VERSION ""

NS_ :

BS_:

BU_: WCM VPM VLM VKM UVM TIM TEST_TOOL_2 TEST_TOOL_1 TCP TCM TCCM3 TCCM STC SRR_SRR SRR_SLR SRR_RR SRR_RF SRR_LR_CR SRR_LF SIB SDM SCL SBZA_R SBZA_L SBM SADS RadioLow RSC RDCM PTM PDR PA NVM MTCM_R MTCM_L MSM_RR MSM_P MSM_LR MSM_D MSB2 MSB1 MRCM_R MRCM_L MFC LRR_HC LRR LIB1 IPC ICS_Info ICCM HVAC_FP_R HVAC_FP_F HUD_CAN HDLM FCM_LC FCM EPS EOCM_HCP2 EOCM_HCP1 EOCM ELM ECP_X1 ECP_MC ECP_E ECM EBCM DMS DEFC DCM CSM CMMb CMMa CGM BSM_MH BSM BCM ARS ARB APA AOS AMP ALC AHS AHL_AFL AGC

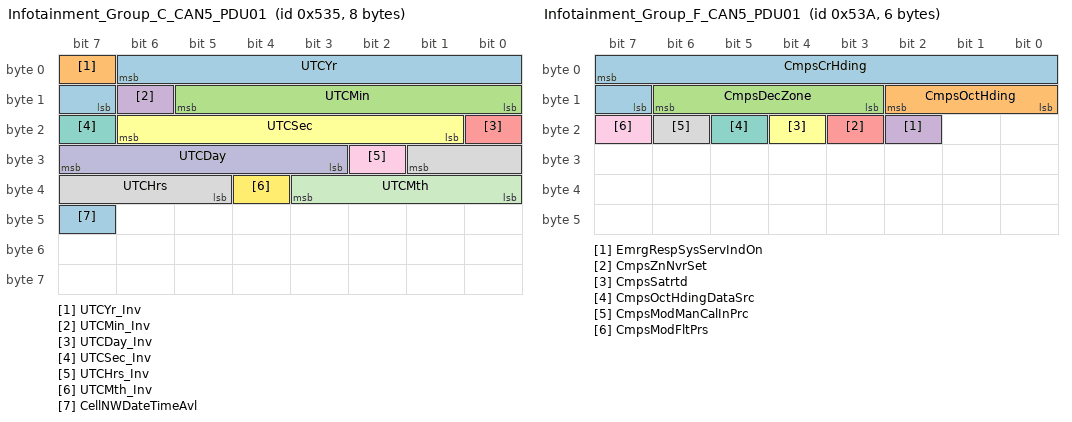
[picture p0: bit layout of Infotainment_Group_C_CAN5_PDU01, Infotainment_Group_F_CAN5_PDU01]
BO_ 1333 Infotainment_Group_C_CAN5_PDU01: 8 TCP
 SG_ UTCYr : 6|8@0+ (1,2000) [2000|2255] "year" CGM,CSM,RadioLow,VKM
 SG_ UTCYr_Inv : 7|1@0+ (1,0) [0|1] "" CGM,CSM,RadioLow,VKM
 SG_ UTCMin : 13|6@0+ (1,0) [0|63] "minutes" CGM,CSM,RadioLow,VKM
 SG_ UTCMin_Inv : 14|1@0+ (1,0) [0|1] "" CGM,CSM,RadioLow,VKM
 SG_ UTCDay_Inv : 16|1@0+ (1,0) [0|1] "" CGM,CSM,RadioLow,VKM
 SG_ UTCSec : 22|6@0+ (1,0) [0|63] "seconds" CGM,CSM,RadioLow
 SG_ UTCSec_Inv : 23|1@0+ (1,0) [0|1] "" CGM,CSM,RadioLow
 SG_ UTCHrs : 25|5@0+ (1,0) [0|31] "hour" CGM,CSM,RadioLow,VKM
 SG_ UTCHrs_Inv : 26|1@0+ (1,0) [0|1] "" CGM,CSM,RadioLow,VKM
 SG_ UTCDay : 31|5@0+ (1,0) [0|31] "day" CGM,CSM,RadioLow,VKM
 SG_ UTCMth : 35|4@0+ (1,0) [0|12] "" CGM,CSM,RadioLow,VKM
 SG_ UTCMth_Inv : 36|1@0+ (1,0) [0|1] "" CGM,CSM,RadioLow,VKM
 SG_ CellNWDateTimeAvl : 47|1@0+ (1,0) [0|1] "" CSM,RadioLow

BO_ 1338 Infotainment_Group_F_CAN5_PDU01: 6 TCP
 SG_ CmpsCrHding : 7|9@0+ (1,0) [0|511] "deg" CSM,IPC,RadioLow
 SG_ CmpsOctHding : 10|3@0+ (1,0) [0|7] "" CSM,IPC,RadioLow
 SG_ CmpsDecZone : 14|4@0+ (1,0) [0|15] "" CSM,IPC,RadioLow
 SG_ EmrgRespSysServIndOn : 18|1@0+ (1,0) [0|1] "" IPC
 SG_ CmpsZnNvrSet : 19|1@0+ (1,0) [0|1] "" CSM,RadioLow
 SG_ CmpsSatrtd : 20|1@0+ (1,0) [0|1] "" CSM,RadioLow
 SG_ CmpsOctHdingDataSrc : 21|1@0+ (1,0) [0|1] "" CSM,RadioLow
 SG_ CmpsModManCalInPrc : 22|1@0+ (1,0) [0|1] "" CSM,RadioLow
 SG_ CmpsModFltPrs : 23|1@0+ (1,0) [0|1] "" CSM,IPC,RadioLow

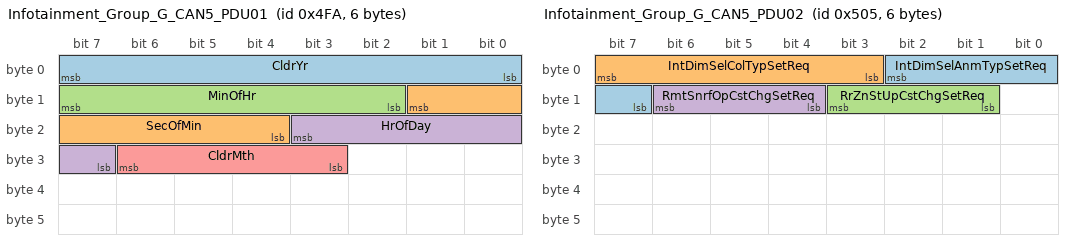
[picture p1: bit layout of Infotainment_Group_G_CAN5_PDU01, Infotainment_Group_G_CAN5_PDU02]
BO_ 1274 Infotainment_Group_G_CAN5_PDU01: 6 CSM
 SG_ CldrYr : 7|8@0+ (1,2000) [2000|2255] "year" CGM,ICS_Info,IPC,PDR
 SG_ SecOfMin : 9|6@0+ (1,0) [0|63] "seconds" CGM,ICS_Info,IPC,PDR
 SG_ MinOfHr : 15|6@0+ (1,0) [0|63] "minutes" CGM,ICS_Info,IPC,PDR
 SG_ HrOfDay : 19|5@0+ (1,0) [0|31] "hour" CGM,ICS_Info,IPC,PDR
 SG_ CldrMth : 30|4@0+ (1,0) [0|12] "" CGM,ICS_Info,IPC,PDR

BO_ 1285 Infotainment_Group_G_CAN5_PDU02: 6 CSM
 SG_ IntDimSelAnmTypSetReq : 2|4@0+ (1,0) [0|15] "" CGM
 SG_ IntDimSelColTypSetReq : 7|5@0+ (1,0) [0|31] "" CGM
 SG_ RrZnStUpCstChgSetReq : 11|3@0+ (1,0) [0|7] "" CGM
 SG_ RmtSnrfOpCstChgSetReq : 14|3@0+ (1,0) [0|7] "" CGM

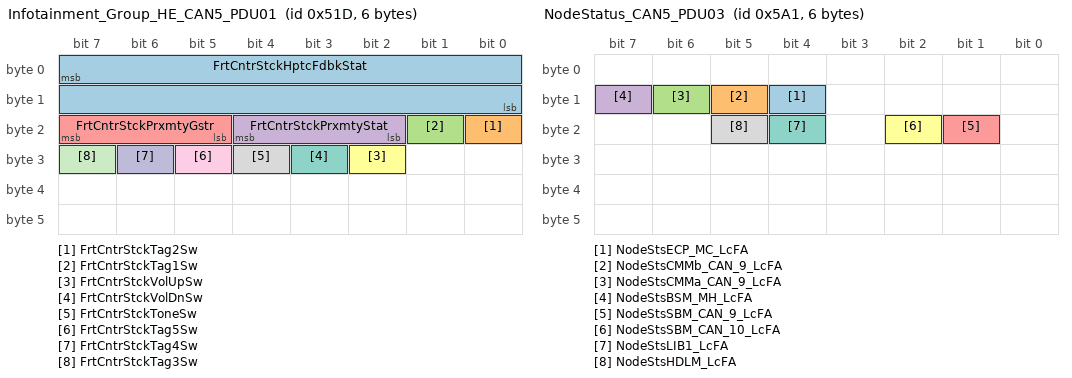
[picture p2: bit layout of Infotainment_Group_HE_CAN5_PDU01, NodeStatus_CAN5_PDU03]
BO_ 1309 Infotainment_Group_HE_CAN5_PDU01: 6 ICS_Info
 SG_ FrtCntrStckHptcFdbkStat : 7|16@0+ (1,0) [0|15] "" CSM,TCP
 SG_ FrtCntrStckTag2Sw : 16|1@0+ (1,0) [0|1] "" CSM,TCP
 SG_ FrtCntrStckTag1Sw : 17|1@0+ (1,0) [0|1] "" CSM,TCP
 SG_ FrtCntrStckPrxmtyStat : 20|3@0+ (1,0) [0|7] "" CSM,TCP
 SG_ FrtCntrStckPrxmtyGstr : 23|3@0+ (1,0) [0|7] "" CSM,TCP
 SG_ FrtCntrStckVolUpSw : 26|1@0+ (1,0) [0|1] "" CSM,TCP
 SG_ FrtCntrStckVolDnSw : 27|1@0+ (1,0) [0|1] "" CSM,TCP
 SG_ FrtCntrStckToneSw : 28|1@0+ (1,0) [0|1] "" CSM,TCP
 SG_ FrtCntrStckTag5Sw : 29|1@0+ (1,0) [0|1] "" CSM,TCP
 SG_ FrtCntrStckTag4Sw : 30|1@0+ (1,0) [0|1] "" CSM,TCP
 SG_ FrtCntrStckTag3Sw : 31|1@0+ (1,0) [0|1] "" CSM,TCP

BO_ 1033 LnFllwgFtrStat_CAN2_PDU01: 6 CGM
 SG_ LnFllwgFtrStat : 7|4@0+ (1,0) [0|10] "" TCP

BO_ 1377 NodeStatus_CAN5_PDU01: 8 CGM
 SG_ NodeStsAPA_CAN_2_LcFA : 0|1@0+ (1,0) [0|1] "" Vector__XXX
 SG_ NodeStsAPA_CAN_1_LcFA : 1|1@0+ (1,0) [0|1] "" CSM
 SG_ NodeStsAOS_LcFA : 2|1@0+ (1,0) [0|1] "" CSM
 SG_ NodeStsAMP_LcFA : 3|1@0+ (1,0) [0|1] "" Vector__XXX
 SG_ NodeStsALC_LcFA : 4|1@0+ (1,0) [0|1] "" CSM,IPC
 SG_ NodeStsAHL_AFL_LcFA : 5|1@0+ (1,0) [0|1] "" CSM,IPC
 SG_ NodeStsAGC_LcFA : 6|1@0+ (1,0) [0|1] "" Vector__XXX
 SG_ NodeStsDMS_LcFA : 8|1@0+ (1,0) [0|1] "" CSM
 SG_ NodeStsDEFC_LcFA : 9|1@0+ (1,0) [0|1] "" CSM,IPC
 SG_ NodeStsDCM_LcFA : 10|1@0+ (1,0) [0|1] "" CSM
 SG_ NodeStsCSM_LcFA : 11|1@0+ (1,0) [0|1] "" Vector__XXX
 SG_ NodeStsBSM_CAN_3_LcFA : 12|1@0+ (1,0) [0|1] "" Vector__XXX
 SG_ NodeStsBSM_CAN_2_LcFA : 13|1@0+ (1,0) [0|1] "" CSM,IPC
 SG_ NodeStsBCM_LcFA : 14|1@0+ (1,0) [0|1] "" AGC,AMP,CSM,HUD_CAN,HVAC_FP_F,HVAC_FP_R,ICS_Info,IPC,PDR,MFC,RSC,RadioLow,TCP,VKM,WCM
 SG_ NodeStsARB_LcFA : 15|1@0+ (1,0) [0|1] "" CSM
 SG_ NodeStsELM_LcFA : 16|1@0+ (1,0) [0|1] "" AMP,CSM,IPC,RadioLow,TCP
 SG_ NodeStsECP_X1_CAN_3_LcFA : 18|1@0+ (1,0) [0|1] "" Vector__XXX
 SG_ NodeStsECP_X1_CAN_2_LcFA : 19|1@0+ (1,0) [0|1] "" AMP,CSM,IPC
 SG_ NodeStsECM_CAN_3_LcFA : 20|1@0+ (1,0) [0|1] "" CSM,IPC
 SG_ NodeStsECM_CAN_2_LcFA : 21|1@0+ (1,0) [0|1] "" AGC,AMP,CSM,HUD_CAN,HVAC_FP_R,ICS_Info,IPC,PDR,MFC,RSC,RadioLow,TCP,VKM,WCM
 SG_ NodeStsEBCM_CAN_2_LcFA : 22|1@0+ (1,0) [0|1] "" CSM,IPC,TCP
 SG_ NodeStsEBCM_CAN_1_LcFA : 23|1@0+ (1,0) [0|1] "" CSM,IPC,RadioLow,TCP
 SG_ NodeStsEPS_LcFA : 24|1@0+ (1,0) [0|1] "" CSM,IPC
 SG_ NodeStsEOCM_HCP2_LcFA : 25|1@0+ (1,0) [0|1] "" CSM
 SG_ NodeStsEOCM_HCP1_CAN_8_LcFA : 26|1@0+ (1,0) [0|1] "" Vector__XXX
 SG_ NodeStsEOCM_HCP1_CAN_2_LcFA : 27|1@0+ (1,0) [0|1] "" CSM,IPC,RadioLow,TCP
 SG_ NodeStsEOCM_HCP1_CAN_1_LcFA : 28|1@0+ (1,0) [0|1] "" CSM,IPC
 SG_ NodeStsEOCM_CAN_8_LcFA : 29|1@0+ (1,0) [0|1] "" Vector__XXX
 SG_ NodeStsEOCM_CAN_2_LcFA : 30|1@0+ (1,0) [0|1] "" CSM,IPC,RadioLow,TCP
 SG_ NodeStsEOCM_CAN_1_LcFA : 31|1@0+ (1,0) [0|1] "" CSM,IPC
 SG_ NodeStsIPC_LcFA : 32|1@0+ (1,0) [0|1] "" Vector__XXX
 SG_ NodeStsICS_Info_LcFA : 33|1@0+ (1,0) [0|1] "" Vector__XXX
 SG_ NodeStsICCM_LcFA : 34|1@0+ (1,0) [0|1] "" CSM,IPC
 SG_ NodeStsHVAC_FP_R_LcFA : 35|1@0+ (1,0) [0|1] "" Vector__XXX
 SG_ NodeStsHVAC_FP_F_LcFA : 36|1@0+ (1,0) [0|1] "" Vector__XXX
 SG_ NodeStsHUD_CAN_LcFA : 37|1@0+ (1,0) [0|1] "" Vector__XXX
 SG_ NodeStsFCM_LcFA : 38|1@0+ (1,0) [0|1] "" CSM,HUD_CAN,IPC,RadioLow
 SG_ NodeStsFCM_LC_LcFA : 39|1@0+ (1,0) [0|1] "" CSM,HUD_CAN,IPC
 SG_ NodeStsMSM_D_LcFA : 40|1@0+ (1,0) [0|1] "" CSM,IPC
 SG_ NodeStsMSB2_LcFA : 41|1@0+ (1,0) [0|1] "" CSM
 SG_ NodeStsMSB1_LcFA : 42|1@0+ (1,0) [0|1] "" CSM
 SG_ NodeStsMRCM_R_LcFA : 43|1@0+ (1,0) [0|1] "" CSM
 SG_ NodeStsMRCM_L_LcFA : 44|1@0+ (1,0) [0|1] "" CSM,IPC,RadioLow
 SG_ NodeStsMFC_LcFA : 45|1@0+ (1,0) [0|1] "" Vector__XXX
 SG_ NodeStsLRR_LcFA : 46|1@0+ (1,0) [0|1] "" CSM
 SG_ NodeStsLRR_HC_LcFA : 47|1@0+ (1,0) [0|1] "" CSM
 SG_ NodeStsPDR_LcFA : 48|1@0+ (1,0) [0|1] "" Vector__XXX
 SG_ NodeStsPA_LcFA : 49|1@0+ (1,0) [0|1] "" CSM
 SG_ NodeStsNVM_LcFA : 50|1@0+ (1,0) [0|1] "" CSM
 SG_ NodeStsMTCM_R_LcFA : 51|1@0+ (1,0) [0|1] "" CSM
 SG_ NodeStsMTCM_L_LcFA : 52|1@0+ (1,0) [0|1] "" CSM
 SG_ NodeStsMSM_RR_LcFA : 53|1@0+ (1,0) [0|1] "" CSM
 SG_ NodeStsMSM_P_LcFA : 54|1@0+ (1,0) [0|1] "" CSM
 SG_ NodeStsMSM_LR_LcFA : 55|1@0+ (1,0) [0|1] "" CSM
 SG_ NodeStsSBZA_R_LcFA : 56|1@0+ (1,0) [0|1] "" CSM
 SG_ NodeStsSBZA_L_LcFA : 57|1@0+ (1,0) [0|1] "" CSM
 SG_ NodeStsSADS_LcFA : 58|1@0+ (1,0) [0|1] "" CSM,IPC
 SG_ NodeStsAHS_LcFA : 59|1@0+ (1,0) [0|1] "" Vector__XXX
 SG_ NodeStsRSC_LcFA : 60|1@0+ (1,0) [0|1] "" Vector__XXX
 SG_ NodeStsRDCM_LcFA : 61|1@0+ (1,0) [0|1] "" CSM,IPC
 SG_ NodeStsRadioLow_LcFA : 62|1@0+ (1,0) [0|1] "" Vector__XXX
 SG_ NodeStsPTM_LcFA : 63|1@0+ (1,0) [0|1] "" CSM,TCP

BO_ 1378 NodeStatus_CAN5_PDU02: 6 CGM
 SG_ NodeStsSRR_SLR_LcFA : 0|1@0+ (1,0) [0|1] "" Vector__XXX
 SG_ NodeStsSRR_RR_LcFA : 1|1@0+ (1,0) [0|1] "" CSM
 SG_ NodeStsSRR_RF_LcFA : 2|1@0+ (1,0) [0|1] "" CSM
 SG_ NodeStsSRR_LR_CR_LcFA : 3|1@0+ (1,0) [0|1] "" CSM
 SG_ NodeStsSRR_LF_LcFA : 4|1@0+ (1,0) [0|1] "" CSM
 SG_ NodeStsSIB_LcFA : 5|1@0+ (1,0) [0|1] "" CSM
 SG_ NodeStsSDM_LcFA : 6|1@0+ (1,0) [0|1] "" CSM,IPC,TCP,WCM
 SG_ NodeStsSCL_LcFA : 7|1@0+ (1,0) [0|1] "" CSM,IPC
 SG_ NodeStsTIM_LcFA : 8|1@0+ (1,0) [0|1] "" CSM
 SG_ NodeStsTCP_LcFA : 9|1@0+ (1,0) [0|1] "" Vector__XXX
 SG_ NodeStsTCM_LcFA : 10|1@0+ (1,0) [0|1] "" CSM,IPC,TCP
 SG_ NodeStsTCCM3_LcFA : 11|1@0+ (1,0) [0|1] "" CSM,IPC
 SG_ NodeStsTCCM_LcFA : 12|1@0+ (1,0) [0|1] "" CSM,IPC
 SG_ NodeStsSTC_LcFA : 14|1@0+ (1,0) [0|1] "" CSM,IPC,RadioLow
 SG_ NodeStsSRR_SRR_LcFA : 15|1@0+ (1,0) [0|1] "" Vector__XXX
 SG_ NodeStsECP_E_CAN_9_LcFA : 16|1@0+ (1,0) [0|1] "" IPC
 SG_ NodeStsCMMb_CAN_2_LcFA : 17|1@0+ (1,0) [0|1] "" CSM,TCP
 SG_ NodeStsCMMa_CAN_2_LcFA : 18|1@0+ (1,0) [0|1] "" CSM,TCP
 SG_ NodeStsARS_LcFA : 19|1@0+ (1,0) [0|1] "" CSM,TCP
 SG_ NodeStsVLM_LcFA : 20|1@0+ (1,0) [0|1] "" CSM,IPC
 SG_ NodeStsWCM_LcFA : 21|1@0+ (1,0) [0|1] "" Vector__XXX
 SG_ NodeStsVPM_LcFA : 22|1@0+ (1,0) [0|1] "" CSM
 SG_ NodeStsVKM_LcFA : 23|1@0+ (1,0) [0|1] "" Vector__XXX
 SG_ NodeStsECP_E_CAN_2_LcFA : 31|1@0+ (1,0) [0|1] "" IPC

BO_ 1441 NodeStatus_CAN5_PDU03: 6 CGM
 SG_ NodeStsECP_MC_LcFA : 12|1@0+ (1,0) [0|1] "" Vector__XXX
 SG_ NodeStsCMMb_CAN_9_LcFA : 13|1@0+ (1,0) [0|1] "" CSM,TCP
 SG_ NodeStsCMMa_CAN_9_LcFA : 14|1@0+ (1,0) [0|1] "" Vector__XXX
 SG_ NodeStsBSM_MH_LcFA : 15|1@0+ (1,0) [0|1] "" Vector__XXX
 SG_ NodeStsSBM_CAN_9_LcFA : 17|1@0+ (1,0) [0|1] "" Vector__XXX
 SG_ NodeStsSBM_CAN_10_LcFA : 18|1@0+ (1,0) [0|1] "" Vector__XXX
 SG_ NodeStsLIB1_LcFA : 20|1@0+ (1,0) [0|1] "" Vector__XXX
 SG_ NodeStsHDLM_LcFA : 21|1@0+ (1,0) [0|1] "" Vector__XXX

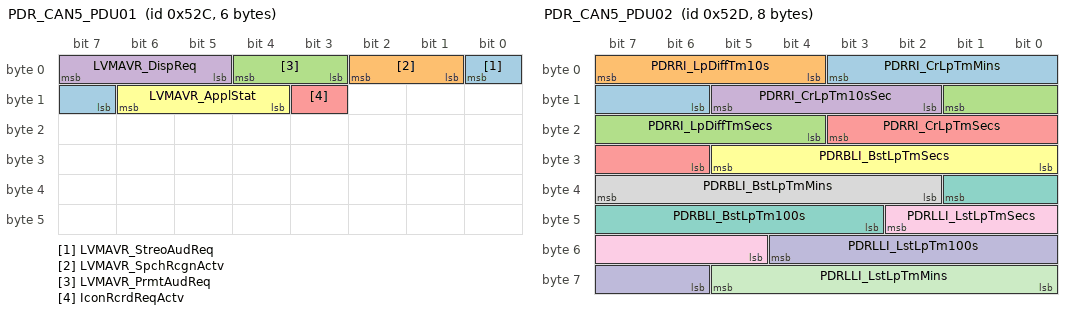
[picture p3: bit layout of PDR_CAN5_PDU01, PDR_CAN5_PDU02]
BO_ 1324 PDR_CAN5_PDU01: 6 PDR
 SG_ LVMAVR_StreoAudReq : 0|2@0+ (1,0) [0|1] "" CSM
 SG_ LVMAVR_SpchRcgnActv : 2|2@0+ (1,0) [0|2] "" CSM
 SG_ LVMAVR_PrmtAudReq : 4|2@0+ (1,0) [0|1] "" CSM
 SG_ LVMAVR_DispReq : 7|3@0+ (1,0) [0|3] "" CSM
 SG_ IconRcrdReqActv : 11|1@0+ (1,0) [0|1] "" CSM
 SG_ LVMAVR_ApplStat : 14|3@0+ (1,0) [0|4] "" CSM

BO_ 1325 PDR_CAN5_PDU02: 8 PDR
 SG_ PDRRI_CrLpTmMins : 3|6@0+ (1,0) [0|63] "Min" IPC
 SG_ PDRRI_LpDiffTm10s : 7|4@0+ (0.1,0) [0|1.5] "Sec" IPC
 SG_ PDRRI_LpDiffTmSecs : 9|6@0+ (1,0) [0|63] "Sec" IPC
 SG_ PDRRI_CrLpTm10sSec : 13|4@0+ (0.1,0) [0|1.5] "Sec" IPC
 SG_ PDRRI_CrLpTmSecs : 19|6@0+ (1,0) [0|63] "Sec" IPC
 SG_ PDRBLI_BstLpTmSecs : 29|6@0+ (1,0) [0|63] "Sec" IPC
 SG_ PDRBLI_BstLpTm100s : 33|7@0+ (0.01,0) [0|1.27] "Sec" IPC
 SG_ PDRBLI_BstLpTmMins : 39|6@0+ (1,0) [0|63] "Min" IPC
 SG_ PDRLLI_LstLpTmSecs : 42|6@0+ (1,0) [0|63] "Sec" IPC
 SG_ PDRLLI_LstLpTm100s : 52|7@0+ (0.01,0) [0|1.27] "Sec" IPC
 SG_ PDRLLI_LstLpTmMins : 61|6@0+ (1,0) [0|63] "Min" IPC

BO_ 566 PrplStat_PCSM_PDU: 8 CGM
 SG_ PrplStat_PCSM : 0|64@1+ (1,0) [0|1.84467e+019] "" IPC,TCP

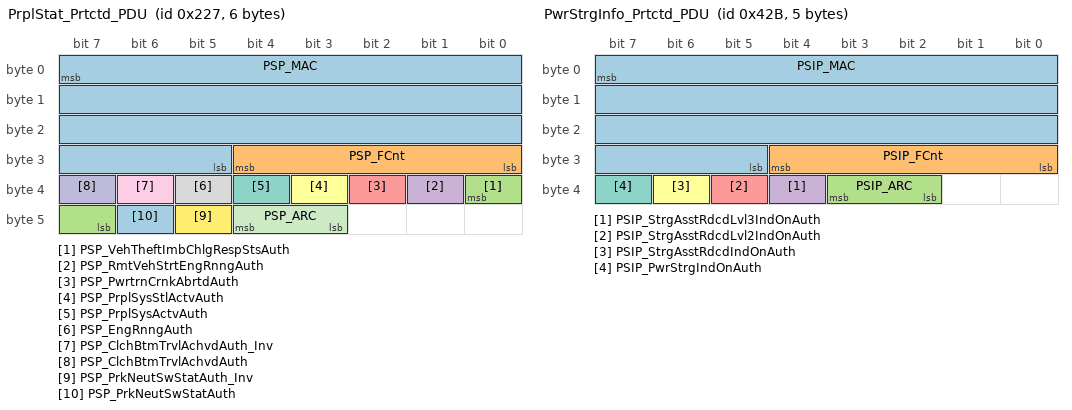
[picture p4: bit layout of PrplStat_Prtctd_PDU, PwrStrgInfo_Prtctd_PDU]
BO_ 551 PrplStat_Prtctd_PDU: 6 CGM
 SG_ PSP_MAC : 7|27@0+ (1,0) [0|1.34218e+008] "" IPC,TCP
 SG_ PSP_FCnt : 28|5@0+ (1,0) [0|31] "" IPC,TCP
 SG_ PSP_VehTheftImbChlgRespStsAuth : 32|2@0+ (1,0) [0|2] "" IPC,TCP
 SG_ PSP_RmtVehStrtEngRnngAuth : 33|1@0+ (1,0) [0|1] "" CSM,IPC,RadioLow,TCP
 SG_ PSP_PwrtrnCrnkAbrtdAuth : 34|1@0+ (1,0) [0|1] "" IPC,TCP
 SG_ PSP_PrplSysStlActvAuth : 35|1@0+ (1,0) [0|1] "" IPC,TCP
 SG_ PSP_PrplSysActvAuth : 36|1@0+ (1,0) [0|1] "" CSM,HVAC_FP_F,ICS_Info,IPC,TCP,WCM
 SG_ PSP_EngRnngAuth : 37|1@0+ (1,0) [0|1] "" AGC,AMP,CSM,HUD_CAN,HVAC_FP_F,HVAC_FP_R,ICS_Info,IPC,PDR,MFC,RSC,RadioLow,TCP,VKM,WCM
 SG_ PSP_ClchBtmTrvlAchvdAuth_Inv : 38|1@0+ (1,0) [0|1] "" CSM,IPC,TCP
 SG_ PSP_ClchBtmTrvlAchvdAuth : 39|1@0+ (1,0) [0|1] "" CSM,IPC,TCP
 SG_ PSP_ARC : 44|2@0+ (1,0) [0|3] "" IPC,TCP
 SG_ PSP_PrkNeutSwStatAuth_Inv : 45|1@0+ (1,0) [0|1] "" IPC,TCP
 SG_ PSP_PrkNeutSwStatAuth : 46|1@0+ (1,0) [0|1] "" IPC,TCP

BO_ 1092 PstClsnInfo_PCSM_PDU: 8 CGM
 SG_ PstClsnInfo_PCSM : 0|64@1+ (1,0) [0|1.84467e+019] "" TCP

BO_ 1090 PstClsnInfo_Prtctd_PDU: 8 CGM
 SG_ PCIP_MAC : 7|27@0+ (1,0) [0|1.34218e+008] "" TCP
 SG_ PCIP_FCnt : 28|5@0+ (1,0) [0|31] "" TCP
 SG_ PCIP_MemStRclDsblReqdAuth : 32|1@0+ (1,0) [0|1] "" TCP
 SG_ PCIP_IntrLgtOnReqdAuth : 33|1@0+ (1,0) [0|1] "" TCP
 SG_ PCIP_HzrdLgtsOnReqdAuth : 34|1@0+ (1,0) [0|1] "" TCP
 SG_ PCIP_HybVehHiVltgDsblReqdAuth : 35|1@0+ (1,0) [0|1] "" TCP
 SG_ PCIP_HVACBlwDsblReqdAuth : 36|1@0+ (1,0) [0|1] "" TCP
 SG_ PCIP_FuelCutOffReqdAuth : 37|1@0+ (1,0) [0|1] "" TCP
 SG_ PCIP_DrUnlckReqdAuth : 38|1@0+ (1,0) [0|1] "" TCP
 SG_ PCIP_BrkActReqdAuth : 39|1@0+ (1,0) [0|1] "" TCP
 SG_ PCIP_NtfnEvntCntAuth : 46|8@0+ (1,0) [0|255] "" TCP
 SG_ PCIP_NftnFrtImpPrtnsrSevAchAuth : 47|1@0+ (1,0) [0|1] "" TCP
 SG_ PCIP_NtfnRlOvrSevAchvdAuth : 48|1@0+ (1,0) [0|1] "" TCP
 SG_ PCIP_NtfnPedtrnPrtctnSevAchAuth : 49|1@0+ (1,0) [0|1] "" TCP
 SG_ PCIP_NtfnLtSdSevAchvdAuth : 50|1@0+ (1,0) [0|1] "" TCP
 SG_ PCIP_NtfnFrtImpStg2SevAchvdAuth : 51|1@0+ (1,0) [0|1] "" TCP
 SG_ PCIP_NtfnFrtImpStg1SevAchvdAuth : 52|1@0+ (1,0) [0|1] "" TCP
 SG_ PCIP_NtfnEvntStsAuth : 54|2@0+ (1,0) [0|2] "" CSM,RadioLow,TCP
 SG_ PCIP_HVCrshImpSnsSysDsbldAuth : 57|1@0+ (1,0) [0|1] "" TCP
 SG_ PCIP_ARC : 59|2@0+ (1,0) [0|3] "" TCP
 SG_ PCIP_CruzCtlDsblReqdAuth : 60|1@0+ (1,0) [0|1] "" TCP
 SG_ PCIP_eCallReqdAuth : 61|1@0+ (1,0) [0|1] "" CSM,ICS_Info,RadioLow,TCP
 SG_ PCIP_NtfnRtSdSevAchvdAuth : 62|1@0+ (1,0) [0|1] "" TCP
 SG_ PCIP_NtfnRrImpSevAchvdAuth : 63|1@0+ (1,0) [0|1] "" TCP

BO_ 1811 PwrStrgInfo_PCSM_PDU: 8 CGM
 SG_ PwrStrgInfo_PCSM : 0|64@1+ (1,0) [0|1.84467e+019] "" IPC

BO_ 1067 PwrStrgInfo_Prtctd_PDU: 5 CGM
 SG_ PSIP_MAC : 7|27@0+ (1,0) [0|1.34218e+008] "" IPC
 SG_ PSIP_FCnt : 28|5@0+ (1,0) [0|31] "" IPC
 SG_ PSIP_ARC : 35|2@0+ (1,0) [0|3] "" IPC
 SG_ PSIP_StrgAsstRdcdLvl3IndOnAuth : 36|1@0+ (1,0) [0|1] "" IPC
 SG_ PSIP_StrgAsstRdcdLvl2IndOnAuth : 37|1@0+ (1,0) [0|1] "" IPC
 SG_ PSIP_StrgAsstRdcdIndOnAuth : 38|1@0+ (1,0) [0|1] "" IPC
 SG_ PSIP_PwrStrgIndOnAuth : 39|1@0+ (1,0) [0|1] "" IPC

BO_ 1830 RPPSD_BrstGrp_PCSM_PDU: 8 TCP
 SG_ RPPSD_BrstGrp1_PCSM : 0|64@1+ (1,0) [0|1.84467e+019] "" Vector__XXX

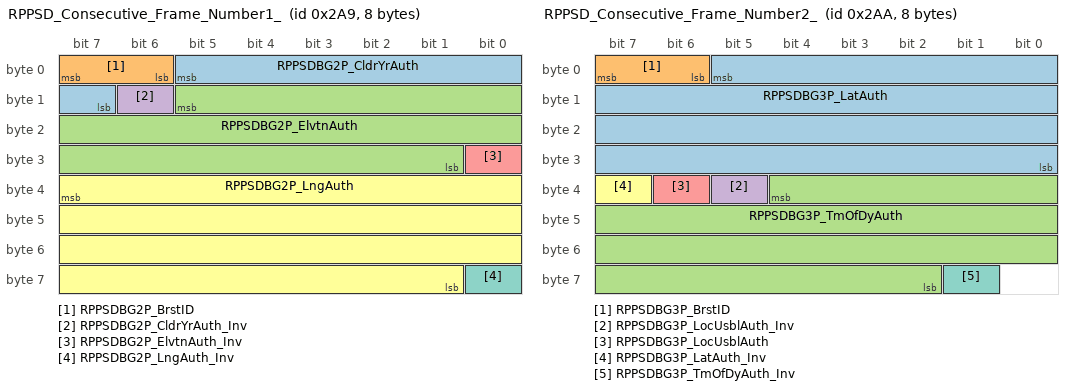
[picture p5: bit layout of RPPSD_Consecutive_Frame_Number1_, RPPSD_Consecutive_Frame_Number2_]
BO_ 681 RPPSD_Consecutive_Frame_Number1_: 8 TCP
 SG_ RPPSDBG2P_CldrYrAuth : 5|7@0+ (1,2014) [2014|2141] "year" Vector__XXX
 SG_ RPPSDBG2P_BrstID : 7|2@0+ (1,0) [0|3] "" Vector__XXX
 SG_ RPPSDBG2P_ElvtnAuth : 13|21@0+ (1,-100000) [-100000|1.99715e+006] "cm" Vector__XXX
 SG_ RPPSDBG2P_CldrYrAuth_Inv : 14|1@0+ (1,0) [0|1] "" Vector__XXX
 SG_ RPPSDBG2P_ElvtnAuth_Inv : 24|1@0+ (1,0) [0|1] "" Vector__XXX
 SG_ RPPSDBG2P_LngAuth : 39|31@0- (1,0) [-1.07374e+009|1.07374e+009] "ms arc" Vector__XXX
 SG_ RPPSDBG2P_LngAuth_Inv : 56|1@0+ (1,0) [0|1] "" Vector__XXX

BO_ 682 RPPSD_Consecutive_Frame_Number2_: 8 TCP
 SG_ RPPSDBG3P_LatAuth : 5|30@0- (1,0) [-5.36871e+008|5.36871e+008] "ms arc" Vector__XXX
 SG_ RPPSDBG3P_BrstID : 7|2@0+ (1,0) [0|3] "" Vector__XXX
 SG_ RPPSDBG3P_TmOfDyAuth : 36|27@0+ (1,0) [0|1.34218e+008] "ms" Vector__XXX
 SG_ RPPSDBG3P_LocUsblAuth_Inv : 37|1@0+ (1,0) [0|1] "" Vector__XXX
 SG_ RPPSDBG3P_LocUsblAuth : 38|1@0+ (1,0) [0|1] "" Vector__XXX
 SG_ RPPSDBG3P_LatAuth_Inv : 39|1@0+ (1,0) [0|1] "" Vector__XXX
 SG_ RPPSDBG3P_TmOfDyAuth_Inv : 57|1@0+ (1,0) [0|1] "" Vector__XXX

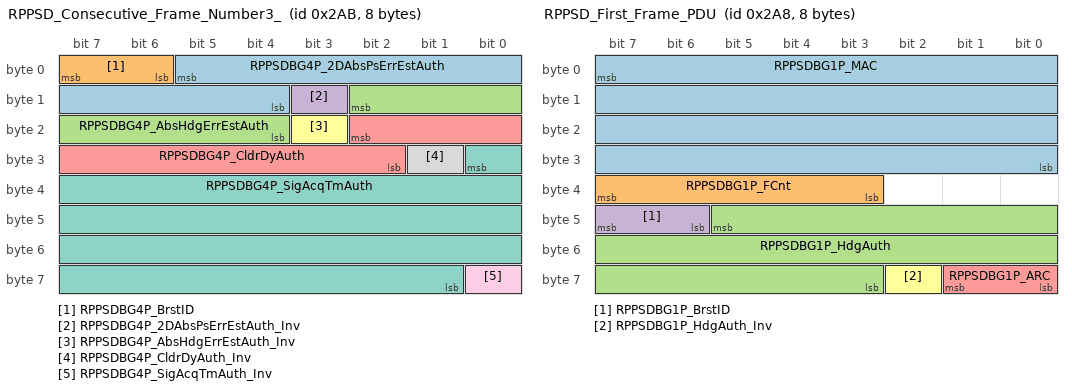
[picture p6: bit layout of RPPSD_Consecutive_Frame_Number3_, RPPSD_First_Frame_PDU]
BO_ 683 RPPSD_Consecutive_Frame_Number3_: 8 TCP
 SG_ RPPSDBG4P_2DAbsPsErrEstAuth : 5|10@0+ (0.1,0) [0|102.3] "m" Vector__XXX
 SG_ RPPSDBG4P_BrstID : 7|2@0+ (1,0) [0|3] "" Vector__XXX
 SG_ RPPSDBG4P_AbsHdgErrEstAuth : 10|7@0+ (0.5,0) [0|63.5] "deg" Vector__XXX
 SG_ RPPSDBG4P_2DAbsPsErrEstAuth_Inv : 11|1@0+ (1,0) [0|1] "" Vector__XXX
 SG_ RPPSDBG4P_CldrDyAuth : 18|9@0+ (1,0) [0|511] "day" Vector__XXX
 SG_ RPPSDBG4P_AbsHdgErrEstAuth_Inv : 19|1@0+ (1,0) [0|1] "" Vector__XXX
 SG_ RPPSDBG4P_SigAcqTmAuth : 24|32@0+ (1,0) [0|4.29497e+009] "ms" Vector__XXX
 SG_ RPPSDBG4P_CldrDyAuth_Inv : 25|1@0+ (1,0) [0|1] "" Vector__XXX
 SG_ RPPSDBG4P_SigAcqTmAuth_Inv : 56|1@0+ (1,0) [0|1] "" Vector__XXX

BO_ 680 RPPSD_First_Frame_PDU: 8 TCP
 SG_ RPPSDBG1P_MAC : 7|32@0+ (1,0) [0|4.29497e+009] "" Vector__XXX
 SG_ RPPSDBG1P_FCnt : 39|5@0+ (1,0) [0|31] "" Vector__XXX
 SG_ RPPSDBG1P_HdgAuth : 45|19@0+ (0.001,0) [0|524.287] "deg" Vector__XXX
 SG_ RPPSDBG1P_BrstID : 47|2@0+ (1,0) [0|3] "" Vector__XXX
 SG_ RPPSDBG1P_ARC : 57|2@0+ (1,0) [0|3] "" Vector__XXX
 SG_ RPPSDBG1P_HdgAuth_Inv : 58|1@0+ (1,0) [0|1] "" Vector__XXX

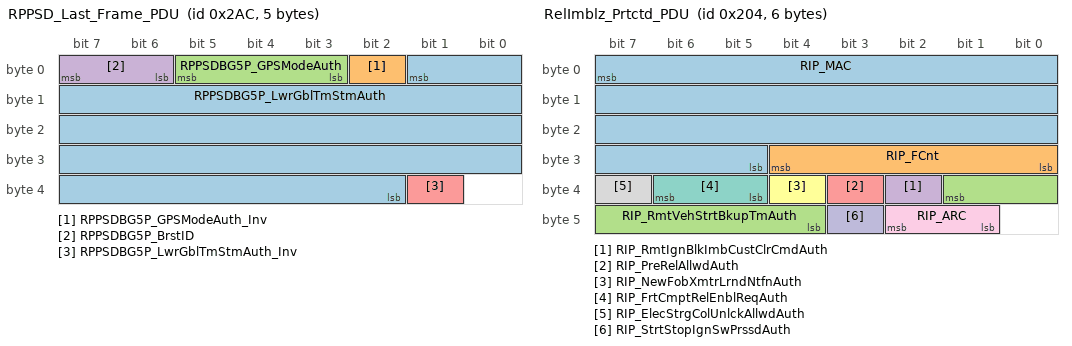
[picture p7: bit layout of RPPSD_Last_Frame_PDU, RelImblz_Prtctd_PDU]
BO_ 684 RPPSD_Last_Frame_PDU: 5 TCP
 SG_ RPPSDBG5P_LwrGblTmStmAuth : 1|32@0+ (1,0) [0|4.29497e+009] "nsec" Vector__XXX
 SG_ RPPSDBG5P_GPSModeAuth_Inv : 2|1@0+ (1,0) [0|1] "" Vector__XXX
 SG_ RPPSDBG5P_GPSModeAuth : 5|3@0+ (1,0) [0|7] "" Vector__XXX
 SG_ RPPSDBG5P_BrstID : 7|2@0+ (1,0) [0|3] "" Vector__XXX
 SG_ RPPSDBG5P_LwrGblTmStmAuth_Inv : 33|1@0+ (1,0) [0|1] "" Vector__XXX

BO_ 1327 RSC_CAN5_PDU01: 6 RSC
 SG_ RrSeatCtrlrPrsnt : 3|1@0+ (1,0) [0|1] "" CSM
 SG_ RrSeatCtrlrBttns : 7|4@0+ (1,0) [0|15] "" CSM

BO_ 520 RelImblz_PCSM_PDU: 8 CGM
 SG_ RelImblz_PCSM : 0|64@1+ (1,0) [0|1.84467e+019] "" TCP

BO_ 516 RelImblz_Prtctd_PDU: 6 CGM
 SG_ RIP_MAC : 7|27@0+ (1,0) [0|1.34218e+008] "" TCP
 SG_ RIP_FCnt : 28|5@0+ (1,0) [0|31] "" TCP
 SG_ RIP_RmtVehStrtBkupTmAuth : 33|6@0+ (1,0) [0|63] "min" TCP
 SG_ RIP_RmtIgnBlkImbCustClrCmdAuth : 34|1@0+ (1,0) [0|1] "" TCP
 SG_ RIP_PreRelAllwdAuth : 35|1@0+ (1,0) [0|1] "" TCP
 SG_ RIP_NewFobXmtrLrndNtfnAuth : 36|1@0+ (1,0) [0|1] "" TCP
 SG_ RIP_FrtCmptRelEnblReqAuth : 38|2@0+ (1,0) [0|2] "" TCP
 SG_ RIP_ElecStrgColUnlckAllwdAuth : 39|1@0+ (1,0) [0|1] "" TCP
 SG_ RIP_ARC : 42|2@0+ (1,0) [0|3] "" TCP
 SG_ RIP_StrtStopIgnSwPrssdAuth : 43|1@0+ (1,0) [0|1] "" CSM,RadioLow,TCP

BO_ 1462 RrCrsTrfcBrkgAutoBrkgRelIndOn_PD: 6 CGM
 SG_ RrCrsTrfcBrkgAutoBrkgRelIndOn : 7|1@0+ (1,0) [0|1] "" IPC

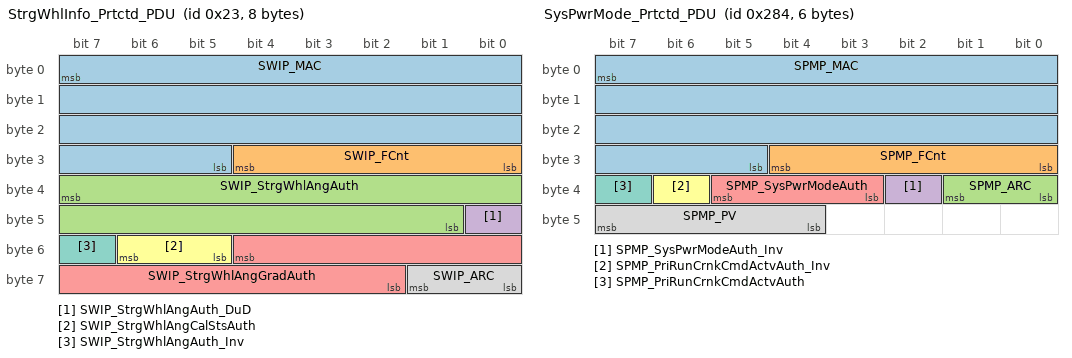
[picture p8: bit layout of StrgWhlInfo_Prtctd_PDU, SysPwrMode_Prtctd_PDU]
BO_ 35 StrgWhlInfo_Prtctd_PDU: 8 CGM
 SG_ SWIP_MAC : 7|27@0+ (1,0) [0|1.34218e+008] "" Vector__XXX
 SG_ SWIP_FCnt : 28|5@0+ (1,0) [0|31] "" Vector__XXX
 SG_ SWIP_StrgWhlAngAuth : 39|15@0- (0.0625,0) [-1024|1023.94] "deg" CSM,PDR,RadioLow,TCP
 SG_ SWIP_StrgWhlAngAuth_DuD : 40|1@0+ (1,0) [0|1] "" PDR
 SG_ SWIP_StrgWhlAngGradAuth : 52|11@0- (2,0) [-2048|2046] "deg/s" CSM,TCP
 SG_ SWIP_StrgWhlAngCalStsAuth : 54|2@0+ (1,0) [0|2] "" CSM,RadioLow
 SG_ SWIP_StrgWhlAngAuth_Inv : 55|1@0+ (1,0) [0|1] "" PDR
 SG_ SWIP_ARC : 57|2@0+ (1,0) [0|3] "" Vector__XXX

BO_ 1357 StrtupShtdnVisInds_PDU: 8 CGM
 SG_ SSVI_PrssClchPrssStrtAgnIO : 6|1@0+ (1,0) [0|1] "" IPC
 SG_ SSVI_NoRmtDtdIO : 7|1@0+ (1,0) [0|1] "" IPC,TCP
 SG_ SSVI_AutoShtdnDsbldIO : 9|1@0+ (1,0) [0|1] "" IPC
 SG_ SSVI_ShfToNeutPrssStrtAgnIO : 10|1@0+ (1,0) [0|1] "" IPC
 SG_ SSVI_AutoShtdnIO : 16|1@0+ (1,0) [0|1] "" IPC
 SG_ SSVI_AppPrkBrkIO : 17|1@0+ (1,0) [0|1] "" IPC
 SG_ SSVI_AppBrkPedIO : 18|1@0+ (1,0) [0|1] "" IPC,TCP
 SG_ SSVI_PrssStrtAgnIO : 19|1@0+ (1,0) [0|1] "" IPC
 SG_ SSVI_ShfToPrkIO : 20|1@0+ (1,0) [0|1] "" IPC
 SG_ SSVI_AppClchPedIO : 21|1@0+ (1,0) [0|1] "" IPC,TCP
 SG_ SSVI_NoRmtDtdPrssBrkToRestrtIO : 22|1@0+ (1,0) [0|1] "" IPC
 SG_ SSVI_AutoShtdnTmr : 30|8@0+ (1,0) [0|255] "Min" IPC
 SG_ SSVI_PrssBtnAgnToTrnEngOffIO : 31|1@0+ (1,0) [0|1] "" IPC
 SG_ ShfToNeutRestrtVehIndOn : 32|1@0+ (1,0) [0|1] "" IPC
 SG_ RestrtVehIndOn : 33|1@0+ (1,0) [0|1] "" IPC
 SG_ SSVI_KeyMvmtRqrdIndOn : 34|1@0+ (1,0) [0|1] "" IPC
 SG_ SSVI_PrssClchBrkForStrtIO : 35|1@0+ (1,0) [0|1] "" IPC
 SG_ SSVI_ClsEngCmptToStrtVehIO : 36|1@0+ (1,0) [0|1] "" IPC
 SG_ SSVI_KylsStrtUseXmtrPcktIO : 37|1@0+ (1,0) [0|1] "" IPC
 SG_ SSVI_NoRmtDtdPrssClchToRestrtIO : 38|1@0+ (1,0) [0|1] "" IPC
 SG_ VehInNeutShfToDrvIndOn : 47|1@0+ (1,0) [0|1] "" IPC
 SG_ SSVI_CS : 50|11@0+ (1,0) [0|2047] "" IPC
 SG_ SSVI_ARC : 55|2@0+ (1,0) [0|3] "" IPC

BO_ 522 SysPwrMode_PCSM_PDU: 8 CGM
 SG_ SysPwrMode_PCSM : 0|64@1+ (1,0) [0|1.84467e+019] "" RSC,VKM

BO_ 644 SysPwrMode_Prtctd_PDU: 6 CGM
 SG_ SPMP_MAC : 7|27@0+ (1,0) [0|1.34218e+008] "" RSC,VKM
 SG_ SPMP_FCnt : 28|5@0+ (1,0) [0|31] "" RSC,VKM
 SG_ SPMP_ARC : 33|2@0+ (1,0) [0|3] "" AGC,HUD_CAN,HVAC_FP_R,IPC,RSC,VKM
 SG_ SPMP_SysPwrModeAuth_Inv : 34|1@0+ (1,0) [0|1] "" AGC,AMP,CSM,HUD_CAN,HVAC_FP_F,HVAC_FP_R,ICS_Info,IPC,PDR,MFC,RSC,RadioLow,TCP,VKM,WCM
 SG_ SPMP_SysPwrModeAuth : 37|3@0+ (1,0) [0|4] "" AGC,AMP,CSM,HUD_CAN,HVAC_FP_F,HVAC_FP_R,ICS_Info,IPC,PDR,MFC,RSC,RadioLow,TCP,VKM,WCM
 SG_ SPMP_PriRunCrnkCmdActvAuth_Inv : 38|1@0+ (1,0) [0|1] "" IPC,RSC,VKM
 SG_ SPMP_PriRunCrnkCmdActvAuth : 39|1@0+ (1,0) [0|1] "" IPC,RSC,VKM
 SG_ SPMP_PV : 47|4@0+ (1,0) [0|15] "" AGC,HUD_CAN,HVAC_FP_R,IPC,RSC,VKM

BO_ 621 TCP_CAN5_PDU02: 6 TCP
 SG_ PrcsPsngSysSigAcqTm : 7|32@0+ (1,0) [0|4.29497e+009] "ms" CSM

BO_ 1334 TCP_CAN5_PDU03: 6 TCP
 SG_ EmrgRespSysTyp : 7|3@0+ (1,0) [0|6] "" IPC

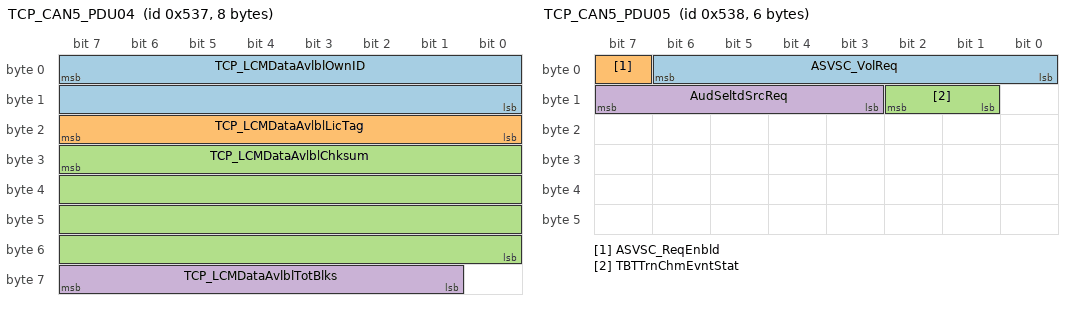
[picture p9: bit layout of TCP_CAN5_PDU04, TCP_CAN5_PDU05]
BO_ 1335 TCP_CAN5_PDU04: 8 TCP
 SG_ TCP_LCMDataAvlblOwnID : 7|16@0+ (1,0) [0|65535] "" CSM,RadioLow
 SG_ TCP_LCMDataAvlblLicTag : 23|8@0+ (1,0) [0|255] "" CSM,RadioLow
 SG_ TCP_LCMDataAvlblChksum : 31|32@0+ (1,0) [0|4.29497e+009] "" CSM,RadioLow
 SG_ TCP_LCMDataAvlblTotBlks : 63|7@0+ (1,0) [0|127] "" CSM,RadioLow

BO_ 1336 TCP_CAN5_PDU05: 6 TCP
 SG_ ASVSC_VolReq : 6|7@0+ (0.787402,0) [0|100] "" CSM
 SG_ ASVSC_ReqEnbld : 7|1@0+ (1,0) [0|1] "" CSM
 SG_ TBTTrnChmEvntStat : 10|2@0+ (1,0) [0|2] "" IPC
 SG_ AudSeltdSrcReq : 15|5@0+ (1,0) [0|30] "" CSM

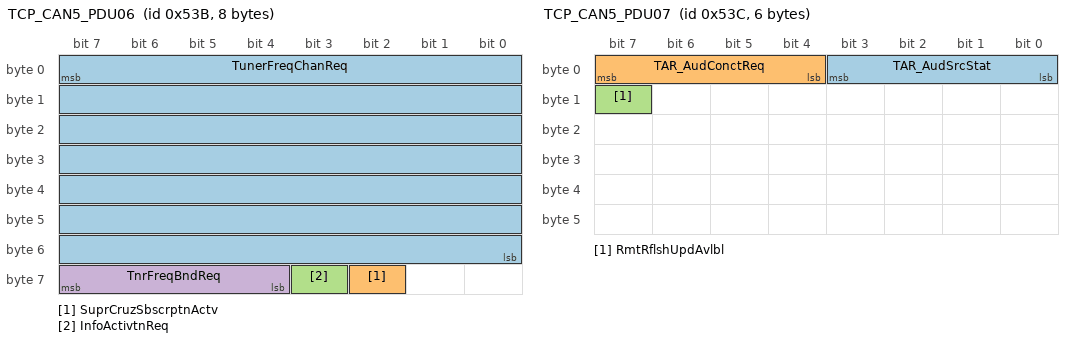
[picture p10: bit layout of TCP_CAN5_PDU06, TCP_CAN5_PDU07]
BO_ 1339 TCP_CAN5_PDU06: 8 TCP
 SG_ TunerFreqChanReq : 7|56@0+ (1,0) [0|7.20576e+016] "" CSM
 SG_ SuprCruzSbscrptnActv : 58|1@0+ (1,0) [0|1] "" CGM
 SG_ InfoActivtnReq : 59|1@0+ (1,0) [0|1] "" CSM,RadioLow
 SG_ TnrFreqBndReq : 63|4@0+ (1,0) [0|15] "" CSM

BO_ 1340 TCP_CAN5_PDU07: 6 TCP
 SG_ TAR_AudSrcStat : 3|4@0+ (1,0) [0|14] "" CGM,CSM,RadioLow
 SG_ TAR_AudConctReq : 7|4@0+ (1,0) [0|15] "" CGM,CSM,RadioLow
 SG_ RmtRflshUpdAvlbl : 15|1@0+ (1,0) [0|1] "" CSM,RadioLow

BO_ 407 TCP_NM_PDU_On_CAN_5_Cluster: 8 TCP
 SG_ ISignal_TCP_CAN_5_Cluster : 23|48@0+ (1,0) [0|281474976710655] "" AGC,AMP,CGM,CSM,HUD_CAN,HVAC_FP_F,HVAC_FP_R,ICS_Info,IPC,PDR,MFC,RSC,RadioLow,VKM,WCM

BO_ 1828 TlmGPSDateSrc_PCSM_PDU: 8 TCP
 SG_ TlmGPSDateSrc_PCSM : 0|64@1+ (1,0) [0|1.84467e+019] "" CGM,VKM

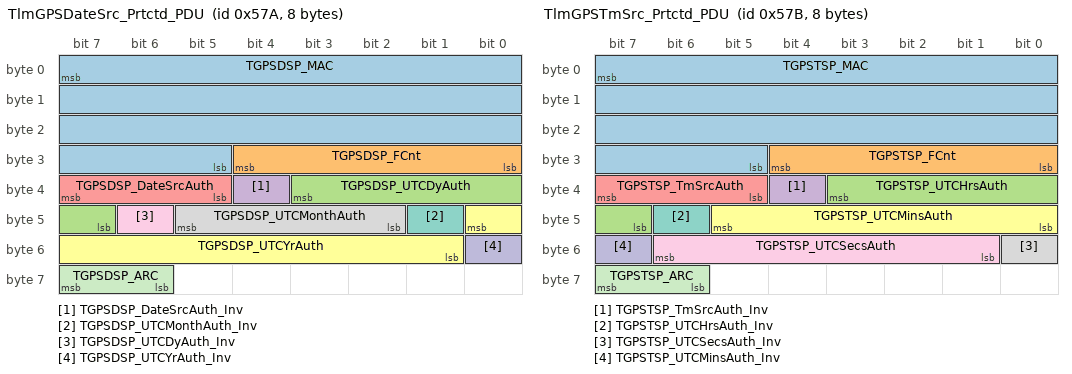
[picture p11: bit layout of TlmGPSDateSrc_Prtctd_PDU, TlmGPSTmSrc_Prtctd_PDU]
BO_ 1402 TlmGPSDateSrc_Prtctd_PDU: 8 TCP
 SG_ TGPSDSP_MAC : 7|27@0+ (1,0) [0|1.34218e+008] "" CGM,VKM
 SG_ TGPSDSP_FCnt : 28|5@0+ (1,0) [0|31] "" CGM,VKM
 SG_ TGPSDSP_UTCDyAuth : 35|5@0+ (1,0) [0|31] "day" CGM,VKM
 SG_ TGPSDSP_DateSrcAuth_Inv : 36|1@0+ (1,0) [0|1] "" CGM,VKM
 SG_ TGPSDSP_DateSrcAuth : 39|3@0+ (1,0) [0|5] "" CGM,VKM
 SG_ TGPSDSP_UTCYrAuth : 40|8@0+ (1,2000) [2000|2255] "year" CGM,VKM
 SG_ TGPSDSP_UTCMonthAuth_Inv : 41|1@0+ (1,0) [0|1] "" CGM,VKM
 SG_ TGPSDSP_UTCMonthAuth : 45|4@0+ (1,0) [0|12] "" CGM,VKM
 SG_ TGPSDSP_UTCDyAuth_Inv : 46|1@0+ (1,0) [0|1] "" CGM,VKM
 SG_ TGPSDSP_UTCYrAuth_Inv : 48|1@0+ (1,0) [0|1] "" CGM,VKM
 SG_ TGPSDSP_ARC : 63|2@0+ (1,0) [0|3] "" CGM,VKM

BO_ 1829 TlmGPSTmSrc_PCSM_PDU: 8 TCP
 SG_ TlmGPSTmSrc_PCSM : 0|64@1+ (1,0) [0|1.84467e+019] "" CGM,VKM

BO_ 1403 TlmGPSTmSrc_Prtctd_PDU: 8 TCP
 SG_ TGPSTSP_MAC : 7|27@0+ (1,0) [0|1.34218e+008] "" CGM,VKM
 SG_ TGPSTSP_FCnt : 28|5@0+ (1,0) [0|31] "" CGM,VKM
 SG_ TGPSTSP_UTCHrsAuth : 35|5@0+ (1,0) [0|31] "hour" CGM,VKM
 SG_ TGPSTSP_TmSrcAuth_Inv : 36|1@0+ (1,0) [0|1] "" CGM,VKM
 SG_ TGPSTSP_TmSrcAuth : 39|3@0+ (1,0) [0|5] "" CGM,VKM
 SG_ TGPSTSP_UTCMinsAuth : 45|6@0+ (1,0) [0|63] "minutes" CGM,VKM
 SG_ TGPSTSP_UTCHrsAuth_Inv : 46|1@0+ (1,0) [0|1] "" CGM,VKM
 SG_ TGPSTSP_UTCSecsAuth_Inv : 48|1@0+ (1,0) [0|1] "" CGM,VKM
 SG_ TGPSTSP_UTCSecsAuth : 54|6@0+ (1,0) [0|63] "seconds" CGM,VKM
 SG_ TGPSTSP_UTCMinsAuth_Inv : 55|1@0+ (1,0) [0|1] "" CGM,VKM
 SG_ TGPSTSP_ARC : 63|2@0+ (1,0) [0|3] "" CGM,VKM

BO_ 1818 TlmGenInfo1_PCSM_PDU: 8 TCP
 SG_ TlmGenInfo1_PCSM : 0|64@1+ (1,0) [0|1.84467e+019] "" Vector__XXX

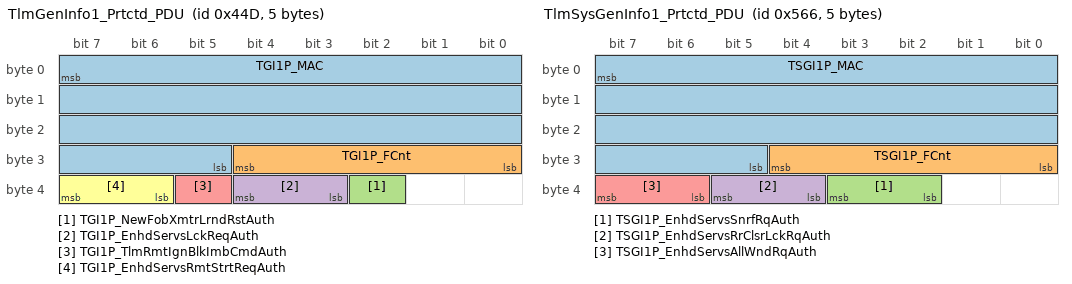
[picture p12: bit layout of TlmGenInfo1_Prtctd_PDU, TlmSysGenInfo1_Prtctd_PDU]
BO_ 1101 TlmGenInfo1_Prtctd_PDU: 5 TCP
 SG_ TGI1P_MAC : 7|27@0+ (1,0) [0|1.34218e+008] "" Vector__XXX
 SG_ TGI1P_FCnt : 28|5@0+ (1,0) [0|31] "" Vector__XXX
 SG_ TGI1P_NewFobXmtrLrndRstAuth : 34|1@0+ (1,0) [0|1] "" Vector__XXX
 SG_ TGI1P_EnhdServsLckReqAuth : 36|2@0+ (1,0) [0|2] "" Vector__XXX
 SG_ TGI1P_TlmRmtIgnBlkImbCmdAuth : 37|1@0+ (1,0) [0|1] "" Vector__XXX
 SG_ TGI1P_EnhdServsRmtStrtReqAuth : 39|2@0+ (1,0) [0|2] "" CSM,RadioLow

BO_ 1832 TlmSysGenInfo1_PCSM_PDU: 8 TCP
 SG_ TlmSysGenInfo1_PCSM : 0|64@1+ (1,0) [0|1.84467e+019] "" Vector__XXX

BO_ 1382 TlmSysGenInfo1_Prtctd_PDU: 5 TCP
 SG_ TSGI1P_MAC : 7|27@0+ (1,0) [0|1.34218e+008] "" Vector__XXX
 SG_ TSGI1P_FCnt : 28|5@0+ (1,0) [0|31] "" Vector__XXX
 SG_ TSGI1P_EnhdServsSnrfRqAuth : 35|2@0+ (1,0) [0|3] "" Vector__XXX
 SG_ TSGI1P_EnhdServsRrClsrLckRqAuth : 37|2@0+ (1,0) [0|2] "" Vector__XXX
 SG_ TSGI1P_EnhdServsAllWndRqAuth : 39|2@0+ (1,0) [0|3] "" Vector__XXX

BO_ 1104 TlmVirtKeyReq_PCSM_PDU: 8 TCP
 SG_ TlmVirtKeyReq_PCSM : 0|64@1+ (1,0) [0|1.84467e+019] "" VKM

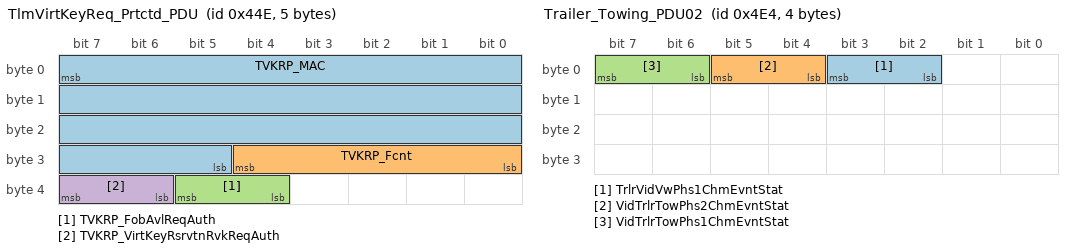
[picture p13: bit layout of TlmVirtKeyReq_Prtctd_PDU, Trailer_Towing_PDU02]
BO_ 1102 TlmVirtKeyReq_Prtctd_PDU: 5 TCP
 SG_ TVKRP_MAC : 7|27@0+ (1,0) [0|1.34218e+008] "" VKM
 SG_ TVKRP_Fcnt : 28|5@0+ (1,0) [0|31] "" VKM
 SG_ TVKRP_FobAvlReqAuth : 37|2@0+ (1,0) [0|3] "" VKM
 SG_ TVKRP_VirtKeyRsrvtnRvkReqAuth : 39|2@0+ (1,0) [0|2] "" VKM

BO_ 1520 IPC_LCMFileDat_Data_PDU: 8 IPC

BO_ 1521 IPC_LCMFileDat_FlwCtrl_PDU: 8 CSM

BO_ 1008 RrSeatCtrlrTxt_Data_PDU: 8 CSM

BO_ 1009 RrSeatCtrlrTxt_FlwCtrl_PDU: 8 RSC

BO_ 1010 TCP_LCMFileDat_Data_PDU: 8 TCP

BO_ 1011 TCP_LCMFileDat_FlwCtrl_PDU: 8 CSM

BO_ 1018 WCM_LCMFileDat_Data_PDU: 8 WCM

BO_ 1019 WCM_LCMFileDat_FlwCtrl_PDU: 8 CSM

BO_ 1267 Trailer_Towing_PDU01: 4 CSM
 SG_ HtchVwAutoElecPrkBrkAppReqd : 7|1@0+ (1,0) [0|1] "" Vector__XXX

BO_ 1252 Trailer_Towing_PDU02: 4 CGM
 SG_ TrlrVidVwPhs1ChmEvntStat : 3|2@0+ (1,0) [0|2] "" IPC
 SG_ VidTrlrTowPhs2ChmEvntStat : 5|2@0+ (1,0) [0|2] "" IPC
 SG_ VidTrlrTowPhs1ChmEvntStat : 7|2@0+ (1,0) [0|2] "" IPC

BO_ 1194 Trans_Type_CAN5_PDU01: 6 CGM
 SG_ TrnsOilTmp : 6|8@0+ (1,-40) [-40|215] "deg C" CSM,IPC,PDR,TCP
 SG_ TrnsOilTmp_Inv : 7|1@0+ (1,0) [0|1] "" CSM,IPC,PDR

BO_ 1229 Trans_Type_CAN5_PDU02: 6 CGM
 SG_ TrnsThrmlMngmntSt : 7|2@0+ (1,0) [0|2] "" CSM,IPC,TCP

BO_ 1051 TrlrBrkInfo_PCSM_PDU: 8 CGM
 SG_ TrlrBrkInfo_PCSM : 0|64@1+ (1,0) [0|1.84467e+019] "" IPC

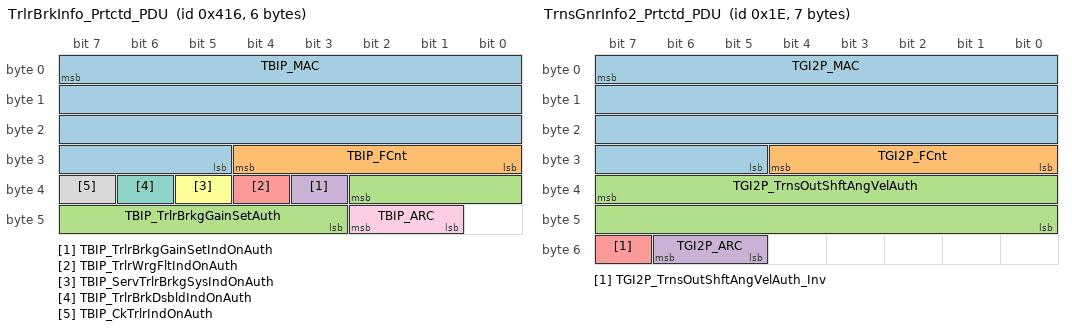
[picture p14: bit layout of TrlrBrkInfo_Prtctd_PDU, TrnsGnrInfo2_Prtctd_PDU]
BO_ 1046 TrlrBrkInfo_Prtctd_PDU: 6 CGM
 SG_ TBIP_MAC : 7|27@0+ (1,0) [0|1.34218e+008] "" IPC
 SG_ TBIP_FCnt : 28|5@0+ (1,0) [0|31] "" IPC
 SG_ TBIP_TrlrBrkgGainSetAuth : 34|8@0+ (0.392157,0) [0|100] "%" CSM,IPC
 SG_ TBIP_TrlrBrkgGainSetIndOnAuth : 35|1@0+ (1,0) [0|1] "" IPC
 SG_ TBIP_TrlrWrgFltIndOnAuth : 36|1@0+ (1,0) [0|1] "" IPC
 SG_ TBIP_ServTrlrBrkgSysIndOnAuth : 37|1@0+ (1,0) [0|1] "" IPC
 SG_ TBIP_TrlrBrkDsbldIndOnAuth : 38|1@0+ (1,0) [0|1] "" IPC
 SG_ TBIP_CkTrlrIndOnAuth : 39|1@0+ (1,0) [0|1] "" IPC
 SG_ TBIP_ARC : 42|2@0+ (1,0) [0|3] "" IPC

BO_ 30 TrnsGnrInfo2_Prtctd_PDU: 7 CGM
 SG_ TGI2P_MAC : 7|27@0+ (1,0) [0|1.34218e+008] "" Vector__XXX
 SG_ TGI2P_FCnt : 28|5@0+ (1,0) [0|31] "" Vector__XXX
 SG_ TGI2P_TrnsOutShftAngVelAuth : 39|16@0+ (0.25,0) [0|16383.8] "rpm" AMP,RadioLow
 SG_ TGI2P_ARC : 54|2@0+ (1,0) [0|3] "" Vector__XXX
 SG_ TGI2P_TrnsOutShftAngVelAuth_Inv : 55|1@0+ (1,0) [0|1] "" AMP

BO_ 1639 USDT_Req_BootMode_To_AGC_CAN_5_c: 8 CGM

BO_ 1650 USDT_Req_BootMode_To_AHL_AFL_CAN: 8 TCP

BO_ 1585 USDT_Req_BootMode_To_AHS_CAN_1_c: 8 TCP

BO_ 1594 USDT_Req_BootMode_To_ALC_CAN_1_c: 8 TCP

BO_ 1665 USDT_Req_BootMode_To_AMP_CAN_5_c: 8 CGM

BO_ 1625 USDT_Req_BootMode_To_AOS_CAN_1_c: 8 TCP

BO_ 1723 USDT_Req_BootMode_To_APA_CAN_2_c: 8 TCP

BO_ 1714 USDT_Req_BootMode_To_ARB_CAN_1_c: 8 TCP

BO_ 1586 USDT_Req_BootMode_To_ARS_CAN_2_c: 8 TCP

BO_ 1600 USDT_Req_BootMode_To_BCM_CAN_2_c: 8 TCP

BO_ 1739 USDT_Req_BootMode_To_BSM_CAN_2_c: 8 TCP

BO_ 1597 USDT_Req_BootMode_To_CMMa_CAN_2_: 8 TCP

BO_ 1598 USDT_Req_BootMode_To_CMMb_CAN_2_: 8 TCP

BO_ 1664 USDT_Req_BootMode_To_CSM_CAN_5_c: 8 CGM

BO_ 1563 USDT_Req_BootMode_To_DCM_CAN_2_c: 8 TCP

BO_ 1556 USDT_Req_BootMode_To_DEFC_CAN_3_: 8 TCP

BO_ 1642 USDT_Req_BootMode_To_DMS_CAN_2_c: 8 TCP

BO_ 1576 USDT_Req_BootMode_To_EBCM_CAN_2_: 8 TCP

BO_ 1553 USDT_Req_BootMode_To_ECM_CAN_2_c: 8 TCP

BO_ 1559 USDT_Req_BootMode_To_ECP_E_CAN_2: 8 TCP

BO_ 1565 USDT_Req_BootMode_To_ECP_MC_CAN_: 8 TCP

BO_ 1601 USDT_Req_BootMode_To_ELM_CAN_2_c: 8 TCP

BO_ 1644 USDT_Req_BootMode_To_EOCM_CAN_8_: 8 TCP

BO_ 1636 USDT_Req_BootMode_To_EOCM_HCP1_C: 8 TCP

BO_ 1755 USDT_Req_BootMode_To_EOCM_HCP2_C: 8 TCP

BO_ 1725 USDT_Req_BootMode_To_FCM_CAN_2_c: 8 TCP

BO_ 1724 USDT_Req_BootMode_To_FCM_LC_CAN_: 8 TCP

BO_ 1646 USDT_Req_BootMode_To_HDLM_CAN_8_: 8 TCP

BO_ 1634 USDT_Req_BootMode_To_HUD_CAN_CAN: 8 CGM

BO_ 1640 USDT_Req_BootMode_To_HVAC_FP_F_C: 8 CGM

BO_ 1690 USDT_Req_BootMode_To_HVAC_FP_R_C: 8 CGM

BO_ 1555 USDT_Req_BootMode_To_ICCM_CAN_2_: 8 TCP

BO_ 1638 USDT_Req_BootMode_To_ICS_Info_CA: 8 CGM

BO_ 1632 USDT_Req_BootMode_To_IPC_CAN_5_c: 8 CGM

BO_ 1766 USDT_Req_BootMode_To_LIB1_CAN_2_: 8 TCP

BO_ 1746 USDT_Req_BootMode_To_LRR_CAN_8_c: 8 TCP

BO_ 1677 USDT_Req_BootMode_To_MFC_CAN_5_c: 8 CGM

BO_ 1707 USDT_Req_BootMode_To_MRCM_L_CAN_: 8 TCP

BO_ 1708 USDT_Req_BootMode_To_MRCM_R_CAN_: 8 TCP

BO_ 1628 USDT_Req_BootMode_To_MSB1_CAN_1_: 8 TCP

BO_ 1630 USDT_Req_BootMode_To_MSB2_CAN_1_: 8 TCP

BO_ 1704 USDT_Req_BootMode_To_MSM_D_CAN_4: 8 TCP

BO_ 1706 USDT_Req_BootMode_To_MSM_LR_CAN_: 8 TCP

BO_ 1702 USDT_Req_BootMode_To_MSM_P_CAN_4: 8 TCP

BO_ 1703 USDT_Req_BootMode_To_MSM_RR_CAN_: 8 TCP

BO_ 1713 USDT_Req_BootMode_To_MTCM_L_CAN_: 8 TCP

BO_ 1720 USDT_Req_BootMode_To_MTCM_R_CAN_: 8 TCP

BO_ 1637 USDT_Req_BootMode_To_NVM_CAN_2_c: 8 TCP

BO_ 1727 USDT_Req_BootMode_To_PA_CAN_1_co: 8 TCP

BO_ 1641 USDT_Req_BootMode_To_PDR_CAN_5_c: 8 CGM

BO_ 1700 USDT_Req_BootMode_To_PTM_CAN_4_c: 8 TCP

BO_ 1562 USDT_Req_BootMode_To_RDCM_CAN_2_: 8 TCP

BO_ 1669 USDT_Req_BootMode_To_RSC_CAN_5_c: 8 CGM

BO_ 1592 USDT_Req_BootMode_To_SADS_CAN_1_: 8 TCP

BO_ 1579 USDT_Req_BootMode_To_SBM_CAN_2_c: 8 TCP

BO_ 1721 USDT_Req_BootMode_To_SBZA_L_CAN_: 8 TCP

BO_ 1722 USDT_Req_BootMode_To_SBZA_R_CAN_: 8 TCP

BO_ 1730 USDT_Req_BootMode_To_SCL_CAN_1_c: 8 TCP

BO_ 1624 USDT_Req_BootMode_To_SDM_CAN_1_c: 8 TCP

BO_ 1606 USDT_Req_BootMode_To_SIB_CAN_3_c: 8 TCP

BO_ 1747 USDT_Req_BootMode_To_SRR_LF_CAN_: 8 TCP

BO_ 1751 USDT_Req_BootMode_To_SRR_LR_CR_C: 8 TCP

BO_ 1750 USDT_Req_BootMode_To_SRR_RF_CAN_: 8 TCP

BO_ 1752 USDT_Req_BootMode_To_SRR_RR_CAN_: 8 TCP

BO_ 1753 USDT_Req_BootMode_To_SRR_SLR_CAN: 8 TCP

BO_ 1754 USDT_Req_BootMode_To_SRR_SRR_CAN: 8 TCP

BO_ 1709 USDT_Req_BootMode_To_STC_CAN_4_c: 8 TCP

BO_ 1564 USDT_Req_BootMode_To_TCCM3_CAN_3: 8 TCP

BO_ 1560 USDT_Req_BootMode_To_TCM_CAN_2_c: 8 TCP

BO_ 1687 USDT_Req_BootMode_To_TCP_CAN_5_c: 8 CGM

BO_ 1653 USDT_Req_BootMode_To_TIM_CAN_4_c: 8 TCP

BO_ 1616 USDT_Req_BootMode_To_UVM_CAN_1_c: 8 TCP

BO_ 1684 USDT_Req_BootMode_To_VKM_CAN_5_c: 8 CGM

BO_ 1593 USDT_Req_BootMode_To_VLM_CAN_1_c: 8 TCP

BO_ 1645 USDT_Req_BootMode_To_VPM_CAN_1_c: 8 TCP

BO_ 1726 USDT_Req_BootMode_To_WCM_CAN_5_c: 8 CGM

BO_ 2497341425 USDT_Req_From_TEST_TOOL_1_To_AGC: 8 CGM

BO_ 2497348081 USDT_Req_From_TEST_TOOL_1_To_AMP: 8 CGM

BO_ 2430336753 USDT_Req_From_TEST_TOOL_1_To_All: 8 CGM

BO_ 2431385329 USDT_Req_From_TEST_TOOL_1_To_CAN: 8 CGM

BO_ 2497347825 USDT_Req_From_TEST_TOOL_1_To_CSM: 8 CGM

BO_ 2497340145 USDT_Req_From_TEST_TOOL_1_To_HUD: 8 CGM

BO_ 2497341681 USDT_Req_From_TEST_TOOL_1_To_HVA: 8 CGM

BO_ 2497354481 USDT_Req_From_TEST_TOOL_1_To_H01: 8 CGM

BO_ 2497341169 USDT_Req_From_TEST_TOOL_1_To_ICS: 8 CGM

BO_ 2497339633 USDT_Req_From_TEST_TOOL_1_To_IPC: 8 CGM

BO_ 2497351153 USDT_Req_From_TEST_TOOL_1_To_MFC: 8 CGM

BO_ 2497341937 USDT_Req_From_TEST_TOOL_1_To_PDR: 8 CGM

BO_ 2497349105 USDT_Req_From_TEST_TOOL_1_To_RSC: 8 CGM

BO_ 2497353713 USDT_Req_From_TEST_TOOL_1_To_TCP: 8 CGM

BO_ 2497352945 USDT_Req_From_TEST_TOOL_1_To_VKM: 8 CGM

BO_ 2497363697 USDT_Req_From_TEST_TOOL_1_To_WCM: 8 CGM

BO_ 2497341426 USDT_Req_From_TEST_TOOL_2_To_AGC: 8 CGM

BO_ 2497348082 USDT_Req_From_TEST_TOOL_2_To_AMP: 8 CGM

BO_ 2430336754 USDT_Req_From_TEST_TOOL_2_To_All: 8 CGM

BO_ 2431385330 USDT_Req_From_TEST_TOOL_2_To_CAN: 8 CGM

BO_ 2497347826 USDT_Req_From_TEST_TOOL_2_To_CSM: 8 CGM

BO_ 2497340146 USDT_Req_From_TEST_TOOL_2_To_HUD: 8 CGM

BO_ 2497341682 USDT_Req_From_TEST_TOOL_2_To_HVA: 8 CGM

BO_ 2497354482 USDT_Req_From_TEST_TOOL_2_To_H01: 8 CGM

BO_ 2497341170 USDT_Req_From_TEST_TOOL_2_To_ICS: 8 CGM

BO_ 2497339634 USDT_Req_From_TEST_TOOL_2_To_IPC: 8 CGM

BO_ 2497351154 USDT_Req_From_TEST_TOOL_2_To_MFC: 8 CGM

BO_ 2497341938 USDT_Req_From_TEST_TOOL_2_To_PDR: 8 CGM

BO_ 2497349106 USDT_Req_From_TEST_TOOL_2_To_RSC: 8 CGM

BO_ 2497353714 USDT_Req_From_TEST_TOOL_2_To_TCP: 8 CGM

BO_ 2497352946 USDT_Req_From_TEST_TOOL_2_To_VKM: 8 CGM

BO_ 2497363698 USDT_Req_From_TEST_TOOL_2_To_WCM: 8 CGM

BO_ 2497341427 USDT_Req_From_TEST_TOOL_3_To_AGC: 8 TCP

BO_ 2497344243 USDT_Req_From_TEST_TOOL_3_To_AHL: 8 TCP

BO_ 2497327603 USDT_Req_From_TEST_TOOL_3_To_AHS: 8 TCP

BO_ 2497329907 USDT_Req_From_TEST_TOOL_3_To_ALC: 8 TCP

BO_ 2497348083 USDT_Req_From_TEST_TOOL_3_To_AMP: 8 TCP

BO_ 2497337843 USDT_Req_From_TEST_TOOL_3_To_AOS: 8 TCP

BO_ 2484780019 USDT_Req_From_TEST_TOOL_3_To_APA: 8 TCP

BO_ 2497362931 USDT_Req_From_TEST_TOOL_3_To_A01: 8 TCP

BO_ 2497360627 USDT_Req_From_TEST_TOOL_3_To_ARB: 8 TCP

BO_ 2497327859 USDT_Req_From_TEST_TOOL_3_To_ARS: 8 TCP

BO_ 2430336755 USDT_Req_From_TEST_TOOL_3_To_All: 8 TCP

BO_ 2497331443 USDT_Req_From_TEST_TOOL_3_To_BCM: 8 TCP

BO_ 2497367027 USDT_Req_From_TEST_TOOL_3_To_BSM: 8 TCP

BO_ 2486881267 USDT_Req_From_TEST_TOOL_3_To_B01: 8 TCP

BO_ 2417753843 USDT_Req_From_TEST_TOOL_3_To_CAN: 8 TCP

BO_ 2418802419 USDT_Req_From_TEST_TOOL_3_To_C01: 8 TCP

BO_ 2419850995 USDT_Req_From_TEST_TOOL_3_To_C02: 8 TCP

BO_ 2420899571 USDT_Req_From_TEST_TOOL_3_To_C03: 8 TCP

BO_ 2431385331 USDT_Req_From_TEST_TOOL_3_To_C04: 8 TCP

BO_ 2425093875 USDT_Req_From_TEST_TOOL_3_To_C05: 8 TCP

BO_ 2497332723 USDT_Req_From_TEST_TOOL_3_To_CGM: 8 TCP

BO_ 2497330675 USDT_Req_From_TEST_TOOL_3_To_CMM: 8 TCP

BO_ 2497330931 USDT_Req_From_TEST_TOOL_3_To_C06: 8 TCP

BO_ 2497347827 USDT_Req_From_TEST_TOOL_3_To_CSM: 8 TCP

BO_ 2497321971 USDT_Req_From_TEST_TOOL_3_To_DCM: 8 TCP

BO_ 2497320179 USDT_Req_From_TEST_TOOL_3_To_DEF: 8 TCP

BO_ 2497342195 USDT_Req_From_TEST_TOOL_3_To_DMS: 8 TCP

BO_ 2484742387 USDT_Req_From_TEST_TOOL_3_To_EBC: 8 TCP

BO_ 2497325299 USDT_Req_From_TEST_TOOL_3_To_E01: 8 TCP

BO_ 2497319411 USDT_Req_From_TEST_TOOL_3_To_ECM: 8 TCP

BO_ 2486833651 USDT_Req_From_TEST_TOOL_3_To_E02: 8 TCP

BO_ 2497320947 USDT_Req_From_TEST_TOOL_3_To_ECP: 8 TCP

BO_ 2497322483 USDT_Req_From_TEST_TOOL_3_To_E03: 8 TCP

BO_ 2486835187 USDT_Req_From_TEST_TOOL_3_To_E04: 8 TCP

BO_ 2497331699 USDT_Req_From_TEST_TOOL_3_To_ELM: 8 TCP

BO_ 2484759795 USDT_Req_From_TEST_TOOL_3_To_EOC: 8 TCP

BO_ 2485808371 USDT_Req_From_TEST_TOOL_3_To_E05: 8 TCP

BO_ 2497342707 USDT_Req_From_TEST_TOOL_3_To_E06: 8 TCP

BO_ 2484757747 USDT_Req_From_TEST_TOOL_3_To_E07: 8 TCP

BO_ 2485806323 USDT_Req_From_TEST_TOOL_3_To_E08: 8 TCP

BO_ 2497340659 USDT_Req_From_TEST_TOOL_3_To_E09: 8 TCP

BO_ 2497371123 USDT_Req_From_TEST_TOOL_3_To_E10: 8 TCP

BO_ 2497363443 USDT_Req_From_TEST_TOOL_3_To_FCM: 8 TCP

BO_ 2497363187 USDT_Req_From_TEST_TOOL_3_To_F01: 8 TCP

BO_ 2497343219 USDT_Req_From_TEST_TOOL_3_To_HDL: 8 TCP

BO_ 2497340147 USDT_Req_From_TEST_TOOL_3_To_HUD: 8 TCP

BO_ 2497341683 USDT_Req_From_TEST_TOOL_3_To_HVA: 8 TCP

BO_ 2497354483 USDT_Req_From_TEST_TOOL_3_To_H01: 8 TCP

BO_ 2497319923 USDT_Req_From_TEST_TOOL_3_To_ICC: 8 TCP

BO_ 2497341171 USDT_Req_From_TEST_TOOL_3_To_ICS: 8 TCP

BO_ 2497339635 USDT_Req_From_TEST_TOOL_3_To_IPC: 8 TCP

BO_ 2497373939 USDT_Req_From_TEST_TOOL_3_To_LIB: 8 TCP

BO_ 2497368819 USDT_Req_From_TEST_TOOL_3_To_LRR: 8 TCP

BO_ 2497351155 USDT_Req_From_TEST_TOOL_3_To_MFC: 8 TCP

BO_ 2497358835 USDT_Req_From_TEST_TOOL_3_To_MRC: 8 TCP

BO_ 2497359091 USDT_Req_From_TEST_TOOL_3_To_M01: 8 TCP

BO_ 2497338611 USDT_Req_From_TEST_TOOL_3_To_MSB: 8 TCP

BO_ 2497339123 USDT_Req_From_TEST_TOOL_3_To_M02: 8 TCP

BO_ 2497358067 USDT_Req_From_TEST_TOOL_3_To_MSM: 8 TCP

BO_ 2497358579 USDT_Req_From_TEST_TOOL_3_To_M03: 8 TCP

BO_ 2497357555 USDT_Req_From_TEST_TOOL_3_To_M04: 8 TCP

BO_ 2497357811 USDT_Req_From_TEST_TOOL_3_To_M05: 8 TCP

BO_ 2497360371 USDT_Req_From_TEST_TOOL_3_To_MTC: 8 TCP

BO_ 2497362163 USDT_Req_From_TEST_TOOL_3_To_M06: 8 TCP

BO_ 2497340915 USDT_Req_From_TEST_TOOL_3_To_NVM: 8 TCP

BO_ 2497363955 USDT_Req_From_TEST_TOOL_3_To_PA_: 8 TCP

BO_ 2497341939 USDT_Req_From_TEST_TOOL_3_To_PDR: 8 TCP

BO_ 2497357043 USDT_Req_From_TEST_TOOL_3_To_PTM: 8 TCP

BO_ 2497321715 USDT_Req_From_TEST_TOOL_3_To_RDC: 8 TCP

BO_ 2497349107 USDT_Req_From_TEST_TOOL_3_To_RSC: 8 TCP

BO_ 2497329395 USDT_Req_From_TEST_TOOL_3_To_SAD: 8 TCP

BO_ 2497326067 USDT_Req_From_TEST_TOOL_3_To_SBM: 8 TCP

BO_ 2497362419 USDT_Req_From_TEST_TOOL_3_To_SBZ: 8 TCP

BO_ 2497362675 USDT_Req_From_TEST_TOOL_3_To_S01: 8 TCP

BO_ 2497364723 USDT_Req_From_TEST_TOOL_3_To_SCL: 8 TCP

BO_ 2497337587 USDT_Req_From_TEST_TOOL_3_To_SDM: 8 TCP

BO_ 2497332979 USDT_Req_From_TEST_TOOL_3_To_SIB: 8 TCP

BO_ 2497369075 USDT_Req_From_TEST_TOOL_3_To_SRR: 8 TCP

BO_ 2497370099 USDT_Req_From_TEST_TOOL_3_To_S02: 8 TCP

BO_ 2497369843 USDT_Req_From_TEST_TOOL_3_To_S03: 8 TCP

BO_ 2497370355 USDT_Req_From_TEST_TOOL_3_To_S04: 8 TCP

BO_ 2497370611 USDT_Req_From_TEST_TOOL_3_To_S05: 8 TCP

BO_ 2497370867 USDT_Req_From_TEST_TOOL_3_To_S06: 8 TCP

BO_ 2497359347 USDT_Req_From_TEST_TOOL_3_To_STC: 8 TCP

BO_ 2497322227 USDT_Req_From_TEST_TOOL_3_To_TCC: 8 TCP

BO_ 2497321203 USDT_Req_From_TEST_TOOL_3_To_TCM: 8 TCP

BO_ 2497345011 USDT_Req_From_TEST_TOOL_3_To_TIM: 8 TCP

BO_ 2497335539 USDT_Req_From_TEST_TOOL_3_To_UVM: 8 TCP

BO_ 2497352947 USDT_Req_From_TEST_TOOL_3_To_VKM: 8 TCP

BO_ 2497329651 USDT_Req_From_TEST_TOOL_3_To_VLM: 8 TCP

BO_ 2497342963 USDT_Req_From_TEST_TOOL_3_To_VPM: 8 TCP

BO_ 2497363699 USDT_Req_From_TEST_TOOL_3_To_WCM: 8 TCP

BO_ 2497341428 USDT_Req_From_TEST_TOOL_4_To_AGC: 8 CGM

BO_ 2497348084 USDT_Req_From_TEST_TOOL_4_To_AMP: 8 CGM

BO_ 2430336756 USDT_Req_From_TEST_TOOL_4_To_All: 8 CGM

BO_ 2431385332 USDT_Req_From_TEST_TOOL_4_To_CAN: 8 CGM

BO_ 2497347828 USDT_Req_From_TEST_TOOL_4_To_CSM: 8 CGM

BO_ 2497340148 USDT_Req_From_TEST_TOOL_4_To_HUD: 8 CGM

BO_ 2497341684 USDT_Req_From_TEST_TOOL_4_To_HVA: 8 CGM

BO_ 2497354484 USDT_Req_From_TEST_TOOL_4_To_H01: 8 CGM

BO_ 2497341172 USDT_Req_From_TEST_TOOL_4_To_ICS: 8 CGM

BO_ 2497339636 USDT_Req_From_TEST_TOOL_4_To_IPC: 8 CGM

BO_ 2497351156 USDT_Req_From_TEST_TOOL_4_To_MFC: 8 CGM

BO_ 2497341940 USDT_Req_From_TEST_TOOL_4_To_PDR: 8 CGM

BO_ 2497349108 USDT_Req_From_TEST_TOOL_4_To_RSC: 8 CGM

BO_ 2497353716 USDT_Req_From_TEST_TOOL_4_To_TCP: 8 CGM

BO_ 2497352948 USDT_Req_From_TEST_TOOL_4_To_VKM: 8 CGM

BO_ 2497363700 USDT_Req_From_TEST_TOOL_4_To_WCM: 8 CGM

BO_ 2497341429 USDT_Req_From_TEST_TOOL_5_To_AGC: 8 CGM

BO_ 2497348085 USDT_Req_From_TEST_TOOL_5_To_AMP: 8 CGM

BO_ 2430336757 USDT_Req_From_TEST_TOOL_5_To_All: 8 CGM

BO_ 2431385333 USDT_Req_From_TEST_TOOL_5_To_CAN: 8 CGM

BO_ 2497347829 USDT_Req_From_TEST_TOOL_5_To_CSM: 8 CGM

BO_ 2497340149 USDT_Req_From_TEST_TOOL_5_To_HUD: 8 CGM

BO_ 2497341685 USDT_Req_From_TEST_TOOL_5_To_HVA: 8 CGM

BO_ 2497354485 USDT_Req_From_TEST_TOOL_5_To_H01: 8 CGM

BO_ 2497341173 USDT_Req_From_TEST_TOOL_5_To_ICS: 8 CGM

BO_ 2497339637 USDT_Req_From_TEST_TOOL_5_To_IPC: 8 CGM

BO_ 2497351157 USDT_Req_From_TEST_TOOL_5_To_MFC: 8 CGM

BO_ 2497341941 USDT_Req_From_TEST_TOOL_5_To_PDR: 8 CGM

BO_ 2497349109 USDT_Req_From_TEST_TOOL_5_To_RSC: 8 CGM

BO_ 2497353717 USDT_Req_From_TEST_TOOL_5_To_TCP: 8 CGM

BO_ 2497352949 USDT_Req_From_TEST_TOOL_5_To_VKM: 8 CGM

BO_ 2497363701 USDT_Req_From_TEST_TOOL_5_To_WCM: 8 CGM

BO_ 2497341430 USDT_Req_From_TEST_TOOL_6_To_AGC: 8 CSM

BO_ 2497344246 USDT_Req_From_TEST_TOOL_6_To_AHL: 8 CSM

BO_ 2497327606 USDT_Req_From_TEST_TOOL_6_To_AHS: 8 CSM

BO_ 2497329910 USDT_Req_From_TEST_TOOL_6_To_ALC: 8 CSM

BO_ 2497348086 USDT_Req_From_TEST_TOOL_6_To_AMP: 8 CSM

BO_ 2497337846 USDT_Req_From_TEST_TOOL_6_To_AOS: 8 CSM

BO_ 2484780022 USDT_Req_From_TEST_TOOL_6_To_APA: 8 CSM

BO_ 2497362934 USDT_Req_From_TEST_TOOL_6_To_A01: 8 CSM

BO_ 2497360630 USDT_Req_From_TEST_TOOL_6_To_ARB: 8 CSM

BO_ 2497327862 USDT_Req_From_TEST_TOOL_6_To_ARS: 8 CSM

BO_ 2430336758 USDT_Req_From_TEST_TOOL_6_To_All: 8 CSM

BO_ 2497331446 USDT_Req_From_TEST_TOOL_6_To_BCM: 8 CSM

BO_ 2497367030 USDT_Req_From_TEST_TOOL_6_To_BSM: 8 CSM

BO_ 2486881270 USDT_Req_From_TEST_TOOL_6_To_B01: 8 CSM

BO_ 2417753846 USDT_Req_From_TEST_TOOL_6_To_CAN: 8 CSM

BO_ 2418802422 USDT_Req_From_TEST_TOOL_6_To_C01: 8 CSM

BO_ 2419850998 USDT_Req_From_TEST_TOOL_6_To_C02: 8 CSM

BO_ 2420899574 USDT_Req_From_TEST_TOOL_6_To_C03: 8 CSM

BO_ 2431385334 USDT_Req_From_TEST_TOOL_6_To_C04: 8 CSM

BO_ 2425093878 USDT_Req_From_TEST_TOOL_6_To_C05: 8 CSM

BO_ 2497332726 USDT_Req_From_TEST_TOOL_6_To_CGM: 8 CSM

BO_ 2497330678 USDT_Req_From_TEST_TOOL_6_To_CMM: 8 CSM

BO_ 2497330934 USDT_Req_From_TEST_TOOL_6_To_C06: 8 CSM

BO_ 2497321974 USDT_Req_From_TEST_TOOL_6_To_DCM: 8 CSM

BO_ 2497320182 USDT_Req_From_TEST_TOOL_6_To_DEF: 8 CSM

BO_ 2497342198 USDT_Req_From_TEST_TOOL_6_To_DMS: 8 CSM

BO_ 2484742390 USDT_Req_From_TEST_TOOL_6_To_EBC: 8 CSM

BO_ 2497325302 USDT_Req_From_TEST_TOOL_6_To_E01: 8 CSM

BO_ 2497319414 USDT_Req_From_TEST_TOOL_6_To_ECM: 8 CSM

BO_ 2486833654 USDT_Req_From_TEST_TOOL_6_To_E02: 8 CSM

BO_ 2497320950 USDT_Req_From_TEST_TOOL_6_To_ECP: 8 CSM

BO_ 2497322486 USDT_Req_From_TEST_TOOL_6_To_E03: 8 CSM

BO_ 2486835190 USDT_Req_From_TEST_TOOL_6_To_E04: 8 CSM

BO_ 2497331702 USDT_Req_From_TEST_TOOL_6_To_ELM: 8 CSM

BO_ 2484759798 USDT_Req_From_TEST_TOOL_6_To_EOC: 8 CSM

BO_ 2485808374 USDT_Req_From_TEST_TOOL_6_To_E05: 8 CSM

BO_ 2497342710 USDT_Req_From_TEST_TOOL_6_To_E06: 8 CSM

BO_ 2484757750 USDT_Req_From_TEST_TOOL_6_To_E07: 8 CSM

BO_ 2485806326 USDT_Req_From_TEST_TOOL_6_To_E08: 8 CSM

BO_ 2497340662 USDT_Req_From_TEST_TOOL_6_To_E09: 8 CSM

BO_ 2497371126 USDT_Req_From_TEST_TOOL_6_To_E10: 8 CSM

BO_ 2497363446 USDT_Req_From_TEST_TOOL_6_To_FCM: 8 CSM

BO_ 2497363190 USDT_Req_From_TEST_TOOL_6_To_F01: 8 CSM

BO_ 2497343222 USDT_Req_From_TEST_TOOL_6_To_HDL: 8 CSM

BO_ 2497340150 USDT_Req_From_TEST_TOOL_6_To_HUD: 8 CSM

BO_ 2497341686 USDT_Req_From_TEST_TOOL_6_To_HVA: 8 CSM

BO_ 2497354486 USDT_Req_From_TEST_TOOL_6_To_H01: 8 CSM

BO_ 2497319926 USDT_Req_From_TEST_TOOL_6_To_ICC: 8 CSM

BO_ 2497341174 USDT_Req_From_TEST_TOOL_6_To_ICS: 8 CSM

BO_ 2497339638 USDT_Req_From_TEST_TOOL_6_To_IPC: 8 CSM

BO_ 2497373942 USDT_Req_From_TEST_TOOL_6_To_LIB: 8 CSM

BO_ 2497368822 USDT_Req_From_TEST_TOOL_6_To_LRR: 8 CSM

BO_ 2497351158 USDT_Req_From_TEST_TOOL_6_To_MFC: 8 CSM

BO_ 2497358838 USDT_Req_From_TEST_TOOL_6_To_MRC: 8 CSM

BO_ 2497359094 USDT_Req_From_TEST_TOOL_6_To_M01: 8 CSM

BO_ 2497338614 USDT_Req_From_TEST_TOOL_6_To_MSB: 8 CSM

BO_ 2497339126 USDT_Req_From_TEST_TOOL_6_To_M02: 8 CSM

BO_ 2497358070 USDT_Req_From_TEST_TOOL_6_To_MSM: 8 CSM

BO_ 2497358582 USDT_Req_From_TEST_TOOL_6_To_M03: 8 CSM

BO_ 2497357558 USDT_Req_From_TEST_TOOL_6_To_M04: 8 CSM

BO_ 2497357814 USDT_Req_From_TEST_TOOL_6_To_M05: 8 CSM

BO_ 2497360374 USDT_Req_From_TEST_TOOL_6_To_MTC: 8 CSM

BO_ 2497362166 USDT_Req_From_TEST_TOOL_6_To_M06: 8 CSM

BO_ 2497340918 USDT_Req_From_TEST_TOOL_6_To_NVM: 8 CSM

BO_ 2497363958 USDT_Req_From_TEST_TOOL_6_To_PA_: 8 CSM

BO_ 2497341942 USDT_Req_From_TEST_TOOL_6_To_PDR: 8 CSM

BO_ 2497357046 USDT_Req_From_TEST_TOOL_6_To_PTM: 8 CSM

BO_ 2497321718 USDT_Req_From_TEST_TOOL_6_To_RDC: 8 CSM

BO_ 2497349110 USDT_Req_From_TEST_TOOL_6_To_RSC: 8 CSM

BO_ 2497329398 USDT_Req_From_TEST_TOOL_6_To_SAD: 8 CSM

BO_ 2497326070 USDT_Req_From_TEST_TOOL_6_To_SBM: 8 CSM

BO_ 2497362422 USDT_Req_From_TEST_TOOL_6_To_SBZ: 8 CSM

BO_ 2497362678 USDT_Req_From_TEST_TOOL_6_To_S01: 8 CSM

BO_ 2497364726 USDT_Req_From_TEST_TOOL_6_To_SCL: 8 CSM

BO_ 2497337590 USDT_Req_From_TEST_TOOL_6_To_SDM: 8 CSM

BO_ 2497332982 USDT_Req_From_TEST_TOOL_6_To_SIB: 8 CSM

BO_ 2497369078 USDT_Req_From_TEST_TOOL_6_To_SRR: 8 CSM

BO_ 2497370102 USDT_Req_From_TEST_TOOL_6_To_S02: 8 CSM

BO_ 2497369846 USDT_Req_From_TEST_TOOL_6_To_S03: 8 CSM

BO_ 2497370358 USDT_Req_From_TEST_TOOL_6_To_S04: 8 CSM

BO_ 2497370614 USDT_Req_From_TEST_TOOL_6_To_S05: 8 CSM

BO_ 2497370870 USDT_Req_From_TEST_TOOL_6_To_S06: 8 CSM

BO_ 2497359350 USDT_Req_From_TEST_TOOL_6_To_STC: 8 CSM

BO_ 2497322230 USDT_Req_From_TEST_TOOL_6_To_TCC: 8 CSM

BO_ 2497321206 USDT_Req_From_TEST_TOOL_6_To_TCM: 8 CSM

BO_ 2497353718 USDT_Req_From_TEST_TOOL_6_To_TCP: 8 CSM

BO_ 2497345014 USDT_Req_From_TEST_TOOL_6_To_TIM: 8 CSM

BO_ 2497335542 USDT_Req_From_TEST_TOOL_6_To_UVM: 8 CSM

BO_ 2497352950 USDT_Req_From_TEST_TOOL_6_To_VKM: 8 CSM

BO_ 2497329654 USDT_Req_From_TEST_TOOL_6_To_VLM: 8 CSM

BO_ 2497342966 USDT_Req_From_TEST_TOOL_6_To_VPM: 8 CSM

BO_ 2497363702 USDT_Req_From_TEST_TOOL_6_To_WCM: 8 CSM

BO_ 2497379431 USDT_Rsp_BootMode_From_AGC_CAN_5: 8 AGC

BO_ 2497379442 USDT_Rsp_BootMode_From_AHL_AFL_C: 8 CGM

BO_ 2497379377 USDT_Rsp_BootMode_From_AHS_CAN_1: 8 CGM

BO_ 2497379386 USDT_Rsp_BootMode_From_ALC_CAN_1: 8 CGM

BO_ 2497379457 USDT_Rsp_BootMode_From_AMP_CAN_5: 8 AMP

BO_ 2497379417 USDT_Rsp_BootMode_From_AOS_CAN_1: 8 CGM

BO_ 2497379515 USDT_Rsp_BootMode_From_APA_CAN_2: 8 CGM

BO_ 2497379506 USDT_Rsp_BootMode_From_ARB_CAN_1: 8 CGM

BO_ 2497379378 USDT_Rsp_BootMode_From_ARS_CAN_2: 8 CGM

BO_ 2497379392 USDT_Rsp_BootMode_From_BCM_CAN_2: 8 CGM

BO_ 2497379531 USDT_Rsp_BootMode_From_BSM_CAN_2: 8 CGM

BO_ 2497379389 USDT_Rsp_BootMode_From_CMMa_CAN_: 8 CGM

BO_ 2497379390 USDT_Rsp_BootMode_From_CMMb_CAN_: 8 CGM

BO_ 2497379456 USDT_Rsp_BootMode_From_CSM_CAN_5: 8 CSM

BO_ 2497379355 USDT_Rsp_BootMode_From_DCM_CAN_2: 8 CGM

BO_ 2497379348 USDT_Rsp_BootMode_From_DEFC_CAN_: 8 CGM

BO_ 2497379434 USDT_Rsp_BootMode_From_DMS_CAN_2: 8 CGM

BO_ 2497379368 USDT_Rsp_BootMode_From_EBCM_CAN_: 8 CGM

BO_ 2497379345 USDT_Rsp_BootMode_From_ECM_CAN_2: 8 CGM

BO_ 2497379351 USDT_Rsp_BootMode_From_ECP_E_CAN: 8 CGM

BO_ 2497379357 USDT_Rsp_BootMode_From_ECP_MC_CA: 8 CGM

BO_ 2497379393 USDT_Rsp_BootMode_From_ELM_CAN_2: 8 CGM

BO_ 2497379436 USDT_Rsp_BootMode_From_EOCM_CAN_: 8 CGM

BO_ 2497379428 USDT_Rsp_BootMode_From_EOCM_HCP1: 8 CGM

BO_ 2497379547 USDT_Rsp_BootMode_From_EOCM_HCP2: 8 CGM

BO_ 2497379517 USDT_Rsp_BootMode_From_FCM_CAN_2: 8 CGM

BO_ 2497379516 USDT_Rsp_BootMode_From_FCM_LC_CA: 8 CGM

BO_ 2497379438 USDT_Rsp_BootMode_From_HDLM_CAN_: 8 CGM

BO_ 2497379426 USDT_Rsp_BootMode_From_HUD_CAN_C: 8 HUD_CAN

BO_ 2497379432 USDT_Rsp_BootMode_From_HVAC_FP_F: 8 HVAC_FP_F

BO_ 2497379482 USDT_Rsp_BootMode_From_HVAC_FP_R: 8 HVAC_FP_R

BO_ 2497379347 USDT_Rsp_BootMode_From_ICCM_CAN_: 8 CGM

BO_ 2497379430 USDT_Rsp_BootMode_From_ICS_Info_: 8 ICS_Info

BO_ 2497379424 USDT_Rsp_BootMode_From_IPC_CAN_5: 8 IPC

BO_ 2497379558 USDT_Rsp_BootMode_From_LIB1_CAN_: 8 CGM

BO_ 2497379538 USDT_Rsp_BootMode_From_LRR_CAN_8: 8 CGM

BO_ 2497379469 USDT_Rsp_BootMode_From_MFC_CAN_5: 8 MFC

BO_ 2497379499 USDT_Rsp_BootMode_From_MRCM_L_CA: 8 CGM

BO_ 2497379500 USDT_Rsp_BootMode_From_MRCM_R_CA: 8 CGM

BO_ 2497379420 USDT_Rsp_BootMode_From_MSB1_CAN_: 8 CGM

BO_ 2497379422 USDT_Rsp_BootMode_From_MSB2_CAN_: 8 CGM

BO_ 2497379496 USDT_Rsp_BootMode_From_MSM_D_CAN: 8 CGM

BO_ 2497379498 USDT_Rsp_BootMode_From_MSM_LR_CA: 8 CGM

BO_ 2497379494 USDT_Rsp_BootMode_From_MSM_P_CAN: 8 CGM

BO_ 2497379495 USDT_Rsp_BootMode_From_MSM_RR_CA: 8 CGM

BO_ 2497379505 USDT_Rsp_BootMode_From_MTCM_L_CA: 8 CGM

BO_ 2497379512 USDT_Rsp_BootMode_From_MTCM_R_CA: 8 CGM

BO_ 2497379429 USDT_Rsp_BootMode_From_NVM_CAN_2: 8 CGM

BO_ 2497379519 USDT_Rsp_BootMode_From_PA_CAN_1_: 8 CGM

BO_ 2497379433 USDT_Rsp_BootMode_From_PDR_CAN_5: 8 PDR

BO_ 2497379492 USDT_Rsp_BootMode_From_PTM_CAN_4: 8 CGM

BO_ 2497379354 USDT_Rsp_BootMode_From_RDCM_CAN_: 8 CGM

BO_ 2497379461 USDT_Rsp_BootMode_From_RSC_CAN_5: 8 RSC

BO_ 2497379384 USDT_Rsp_BootMode_From_SADS_CAN_: 8 CGM

BO_ 2497379371 USDT_Rsp_BootMode_From_SBM_CAN_2: 8 CGM

BO_ 2497379513 USDT_Rsp_BootMode_From_SBZA_L_CA: 8 CGM

BO_ 2497379514 USDT_Rsp_BootMode_From_SBZA_R_CA: 8 CGM

BO_ 2497379522 USDT_Rsp_BootMode_From_SCL_CAN_1: 8 CGM

BO_ 2497379416 USDT_Rsp_BootMode_From_SDM_CAN_1: 8 CGM

BO_ 2497379398 USDT_Rsp_BootMode_From_SIB_CAN_3: 8 CGM

BO_ 2497379539 USDT_Rsp_BootMode_From_SRR_LF_CA: 8 CGM

BO_ 2497379543 USDT_Rsp_BootMode_From_SRR_LR_CR: 8 CGM

BO_ 2497379542 USDT_Rsp_BootMode_From_SRR_RF_CA: 8 CGM

BO_ 2497379544 USDT_Rsp_BootMode_From_SRR_RR_CA: 8 CGM

BO_ 2497379545 USDT_Rsp_BootMode_From_SRR_SLR_C: 8 CGM

BO_ 2497379546 USDT_Rsp_BootMode_From_SRR_SRR_C: 8 CGM

BO_ 2497379501 USDT_Rsp_BootMode_From_STC_CAN_4: 8 CGM

BO_ 2497379356 USDT_Rsp_BootMode_From_TCCM3_CAN: 8 CGM

BO_ 2497379352 USDT_Rsp_BootMode_From_TCM_CAN_2: 8 CGM

BO_ 2497379479 USDT_Rsp_BootMode_From_TCP_CAN_5: 8 TCP

BO_ 2497379445 USDT_Rsp_BootMode_From_TIM_CAN_4: 8 CGM

BO_ 2497379408 USDT_Rsp_BootMode_From_UVM_CAN_1: 8 CGM

BO_ 2497379476 USDT_Rsp_BootMode_From_VKM_CAN_5: 8 VKM

BO_ 2497379385 USDT_Rsp_BootMode_From_VLM_CAN_1: 8 CGM

BO_ 2497379437 USDT_Rsp_BootMode_From_VPM_CAN_1: 8 CGM

BO_ 2497379518 USDT_Rsp_BootMode_From_WCM_CAN_5: 8 WCM

BO_ 2497376615 USDT_Rsp_From_AGC_CAN_5_connecto: 8 AGC

BO_ 2497376871 USDT_Rsp_From_AGC_CAN_5_connec01: 8 AGC

BO_ 2497377127 USDT_Rsp_From_AGC_CAN_5_connec02: 8 AGC

BO_ 2497377383 USDT_Rsp_From_AGC_CAN_5_connec03: 8 AGC

BO_ 2497377639 USDT_Rsp_From_AGC_CAN_5_connec04: 8 AGC

BO_ 2497377895 USDT_Rsp_From_AGC_CAN_5_connec05: 8 AGC

BO_ 2485842802 USDT_Rsp_From_AHL_AFL_CAN_2_conn: 8 CGM

BO_ 2485843570 USDT_Rsp_From_AHL_AFL_CAN_2_co01: 8 CGM

BO_ 2484794161 USDT_Rsp_From_AHS_CAN_1_connecto: 8 CGM

BO_ 2484794929 USDT_Rsp_From_AHS_CAN_1_connec01: 8 CGM

BO_ 2484794170 USDT_Rsp_From_ALC_CAN_1_connecto: 8 CGM

BO_ 2484794938 USDT_Rsp_From_ALC_CAN_1_connec01: 8 CGM

BO_ 2497376641 USDT_Rsp_From_AMP_CAN_5_connecto: 8 AMP

BO_ 2497376897 USDT_Rsp_From_AMP_CAN_5_connec01: 8 AMP

BO_ 2497377153 USDT_Rsp_From_AMP_CAN_5_connec02: 8 AMP

BO_ 2497377409 USDT_Rsp_From_AMP_CAN_5_connec03: 8 AMP

BO_ 2497377665 USDT_Rsp_From_AMP_CAN_5_connec04: 8 AMP

BO_ 2497377921 USDT_Rsp_From_AMP_CAN_5_connec05: 8 AMP

BO_ 2484794201 USDT_Rsp_From_AOS_CAN_1_connecto: 8 CGM

BO_ 2484794969 USDT_Rsp_From_AOS_CAN_1_connec01: 8 CGM

BO_ 2484794299 USDT_Rsp_From_APA_CAN_1_connecto: 8 CGM

BO_ 2484795067 USDT_Rsp_From_APA_CAN_1_connec01: 8 CGM

BO_ 2485842875 USDT_Rsp_From_APA_CAN_2_connecto: 8 CGM

BO_ 2485843643 USDT_Rsp_From_APA_CAN_2_connec01: 8 CGM

BO_ 2484794290 USDT_Rsp_From_ARB_CAN_1_connecto: 8 CGM

BO_ 2484795058 USDT_Rsp_From_ARB_CAN_1_connec01: 8 CGM

BO_ 2485842738 USDT_Rsp_From_ARS_CAN_2_connecto: 8 CGM

BO_ 2485843506 USDT_Rsp_From_ARS_CAN_2_connec01: 8 CGM

BO_ 2485842752 USDT_Rsp_From_BCM_CAN_2_connecto: 8 CGM

BO_ 2485843520 USDT_Rsp_From_BCM_CAN_2_connec01: 8 CGM

BO_ 2485842891 USDT_Rsp_From_BSM_CAN_2_connecto: 8 CGM

BO_ 2485843659 USDT_Rsp_From_BSM_CAN_2_connec01: 8 CGM

BO_ 2486891467 USDT_Rsp_From_BSM_CAN_3_connecto: 8 CGM

BO_ 2486892235 USDT_Rsp_From_BSM_CAN_3_connec01: 8 CGM

BO_ 2497377093 USDT_Rsp_From_CGM_CAN_5_connecto: 8 CGM

BO_ 2497377861 USDT_Rsp_From_CGM_CAN_5_connec01: 8 CGM

BO_ 2485842749 USDT_Rsp_From_CMMa_CAN_2_connect: 8 CGM

BO_ 2485843517 USDT_Rsp_From_CMMa_CAN_2_conne01: 8 CGM

BO_ 2485842750 USDT_Rsp_From_CMMb_CAN_2_connect: 8 CGM

BO_ 2485843518 USDT_Rsp_From_CMMb_CAN_2_conne01: 8 CGM

BO_ 2497376640 USDT_Rsp_From_CSM_CAN_5_connecto: 8 CSM

BO_ 2497376896 USDT_Rsp_From_CSM_CAN_5_connec01: 8 CSM

BO_ 2497377152 USDT_Rsp_From_CSM_CAN_5_connec02: 8 CSM

BO_ 2497377408 USDT_Rsp_From_CSM_CAN_5_connec03: 8 CSM

BO_ 2497377664 USDT_Rsp_From_CSM_CAN_5_connec04: 8 CSM

BO_ 2485842715 USDT_Rsp_From_DCM_CAN_2_connecto: 8 CGM

BO_ 2485843483 USDT_Rsp_From_DCM_CAN_2_connec01: 8 CGM

BO_ 2486891284 USDT_Rsp_From_DEFC_CAN_3_connect: 8 CGM

BO_ 2486892052 USDT_Rsp_From_DEFC_CAN_3_conne01: 8 CGM

BO_ 2485842794 USDT_Rsp_From_DMS_CAN_2_connecto: 8 CGM

BO_ 2485843562 USDT_Rsp_From_DMS_CAN_2_connec01: 8 CGM

BO_ 2484794152 USDT_Rsp_From_EBCM_CAN_1_connect: 8 CGM

BO_ 2484794920 USDT_Rsp_From_EBCM_CAN_1_conne01: 8 CGM

BO_ 2485842728 USDT_Rsp_From_EBCM_CAN_2_connect: 8 CGM

BO_ 2485843496 USDT_Rsp_From_EBCM_CAN_2_conne01: 8 CGM

BO_ 2485842705 USDT_Rsp_From_ECM_CAN_2_connecto: 8 CGM

BO_ 2485843473 USDT_Rsp_From_ECM_CAN_2_connec01: 8 CGM

BO_ 2486891281 USDT_Rsp_From_ECM_CAN_3_connecto: 8 CGM

BO_ 2486892049 USDT_Rsp_From_ECM_CAN_3_connec01: 8 CGM

BO_ 2485842711 USDT_Rsp_From_ECP_E_CAN_2_connec: 8 CGM

BO_ 2485843479 USDT_Rsp_From_ECP_E_CAN_2_conn01: 8 CGM

BO_ 2485842717 USDT_Rsp_From_ECP_MC_CAN_2_conne: 8 CGM

BO_ 2485843485 USDT_Rsp_From_ECP_MC_CAN_2_con01: 8 CGM

BO_ 2486891287 USDT_Rsp_From_ECP_X1_CAN_3_conne: 8 CGM

BO_ 2486892055 USDT_Rsp_From_ECP_X1_CAN_3_con01: 8 CGM

BO_ 2485842753 USDT_Rsp_From_ELM_CAN_2_connecto: 8 CGM

BO_ 2485843521 USDT_Rsp_From_ELM_CAN_2_connec01: 8 CGM

BO_ 2484794220 USDT_Rsp_From_EOCM_CAN_1_connect: 8 CGM

BO_ 2484794988 USDT_Rsp_From_EOCM_CAN_1_conne01: 8 CGM

BO_ 2485842796 USDT_Rsp_From_EOCM_CAN_2_connect: 8 CGM

BO_ 2485843564 USDT_Rsp_From_EOCM_CAN_2_conne01: 8 CGM

BO_ 2492134252 USDT_Rsp_From_EOCM_CAN_8_connect: 8 CGM

BO_ 2492135020 USDT_Rsp_From_EOCM_CAN_8_conne01: 8 CGM

BO_ 2484794212 USDT_Rsp_From_EOCM_HCP1_CAN_1_co: 8 CGM

BO_ 2484794980 USDT_Rsp_From_EOCM_HCP1_CAN_1_01: 8 CGM

BO_ 2485842788 USDT_Rsp_From_EOCM_HCP1_CAN_2_co: 8 CGM

BO_ 2485843556 USDT_Rsp_From_EOCM_HCP1_CAN_2_01: 8 CGM

BO_ 2492134244 USDT_Rsp_From_EOCM_HCP1_CAN_8_co: 8 CGM

BO_ 2492135012 USDT_Rsp_From_EOCM_HCP1_CAN_8_01: 8 CGM

BO_ 2492134363 USDT_Rsp_From_EOCM_HCP2_CAN_8_co: 8 CGM

BO_ 2492135131 USDT_Rsp_From_EOCM_HCP2_CAN_8_01: 8 CGM

BO_ 2485842877 USDT_Rsp_From_FCM_CAN_2_connecto: 8 CGM

BO_ 2485843645 USDT_Rsp_From_FCM_CAN_2_connec01: 8 CGM

BO_ 2492134332 USDT_Rsp_From_FCM_LC_CAN_8_conne: 8 CGM

BO_ 2492135100 USDT_Rsp_From_FCM_LC_CAN_8_con01: 8 CGM

BO_ 2492134254 USDT_Rsp_From_HDLM_CAN_8_connect: 8 CGM

BO_ 2492135022 USDT_Rsp_From_HDLM_CAN_8_conne01: 8 CGM

BO_ 2497376610 USDT_Rsp_From_HUD_CAN_CAN_5_conn: 8 HUD_CAN

BO_ 2497376866 USDT_Rsp_From_HUD_CAN_CAN_5_co01: 8 HUD_CAN

BO_ 2497377122 USDT_Rsp_From_HUD_CAN_CAN_5_co02: 8 HUD_CAN

BO_ 2497377378 USDT_Rsp_From_HUD_CAN_CAN_5_co03: 8 HUD_CAN

BO_ 2497377634 USDT_Rsp_From_HUD_CAN_CAN_5_co04: 8 HUD_CAN

BO_ 2497377890 USDT_Rsp_From_HUD_CAN_CAN_5_co05: 8 HUD_CAN

BO_ 2497376616 USDT_Rsp_From_HVAC_FP_F_CAN_5_co: 8 HVAC_FP_F

BO_ 2497376872 USDT_Rsp_From_HVAC_FP_F_CAN_5_01: 8 HVAC_FP_F

BO_ 2497377128 USDT_Rsp_From_HVAC_FP_F_CAN_5_02: 8 HVAC_FP_F

BO_ 2497377384 USDT_Rsp_From_HVAC_FP_F_CAN_5_03: 8 HVAC_FP_F

BO_ 2497377640 USDT_Rsp_From_HVAC_FP_F_CAN_5_04: 8 HVAC_FP_F

BO_ 2497377896 USDT_Rsp_From_HVAC_FP_F_CAN_5_05: 8 HVAC_FP_F

BO_ 2497376666 USDT_Rsp_From_HVAC_FP_R_CAN_5_co: 8 HVAC_FP_R

BO_ 2497376922 USDT_Rsp_From_HVAC_FP_R_CAN_5_01: 8 HVAC_FP_R

BO_ 2497377178 USDT_Rsp_From_HVAC_FP_R_CAN_5_02: 8 HVAC_FP_R

BO_ 2497377434 USDT_Rsp_From_HVAC_FP_R_CAN_5_03: 8 HVAC_FP_R

BO_ 2497377690 USDT_Rsp_From_HVAC_FP_R_CAN_5_04: 8 HVAC_FP_R

BO_ 2497377946 USDT_Rsp_From_HVAC_FP_R_CAN_5_05: 8 HVAC_FP_R

BO_ 2485842707 USDT_Rsp_From_ICCM_CAN_2_connect: 8 CGM

BO_ 2485843475 USDT_Rsp_From_ICCM_CAN_2_conne01: 8 CGM

BO_ 2497376614 USDT_Rsp_From_ICS_Info_CAN_5_con: 8 ICS_Info

BO_ 2497376870 USDT_Rsp_From_ICS_Info_CAN_5_c01: 8 ICS_Info

BO_ 2497377126 USDT_Rsp_From_ICS_Info_CAN_5_c02: 8 ICS_Info

BO_ 2497377382 USDT_Rsp_From_ICS_Info_CAN_5_c03: 8 ICS_Info

BO_ 2497377638 USDT_Rsp_From_ICS_Info_CAN_5_c04: 8 ICS_Info

BO_ 2497377894 USDT_Rsp_From_ICS_Info_CAN_5_c05: 8 ICS_Info

BO_ 2497376608 USDT_Rsp_From_IPC_CAN_5_connecto: 8 IPC

BO_ 2497376864 USDT_Rsp_From_IPC_CAN_5_connec01: 8 IPC

BO_ 2497377120 USDT_Rsp_From_IPC_CAN_5_connec02: 8 IPC

BO_ 2497377376 USDT_Rsp_From_IPC_CAN_5_connec03: 8 IPC

BO_ 2497377632 USDT_Rsp_From_IPC_CAN_5_connec04: 8 IPC

BO_ 2497377888 USDT_Rsp_From_IPC_CAN_5_connec05: 8 IPC

BO_ 2485842918 USDT_Rsp_From_LIB1_CAN_2_connect: 8 CGM

BO_ 2485843686 USDT_Rsp_From_LIB1_CAN_2_conne01: 8 CGM

BO_ 2492134354 USDT_Rsp_From_LRR_CAN_8_connecto: 8 CGM

BO_ 2492135122 USDT_Rsp_From_LRR_CAN_8_connec01: 8 CGM

BO_ 2497376653 USDT_Rsp_From_MFC_CAN_5_connecto: 8 MFC

BO_ 2497376909 USDT_Rsp_From_MFC_CAN_5_connec01: 8 MFC

BO_ 2497377165 USDT_Rsp_From_MFC_CAN_5_connec02: 8 MFC

BO_ 2497377421 USDT_Rsp_From_MFC_CAN_5_connec03: 8 MFC

BO_ 2497377677 USDT_Rsp_From_MFC_CAN_5_connec04: 8 MFC

BO_ 2497377933 USDT_Rsp_From_MFC_CAN_5_connec05: 8 MFC

BO_ 2487940011 USDT_Rsp_From_MRCM_L_CAN_4_conne: 8 CGM

BO_ 2487940779 USDT_Rsp_From_MRCM_L_CAN_4_con01: 8 CGM

BO_ 2487940012 USDT_Rsp_From_MRCM_R_CAN_4_conne: 8 CGM

BO_ 2487940780 USDT_Rsp_From_MRCM_R_CAN_4_con01: 8 CGM

BO_ 2484794204 USDT_Rsp_From_MSB1_CAN_1_connect: 8 CGM

BO_ 2484794972 USDT_Rsp_From_MSB1_CAN_1_conne01: 8 CGM

BO_ 2484794206 USDT_Rsp_From_MSB2_CAN_1_connect: 8 CGM

BO_ 2484794974 USDT_Rsp_From_MSB2_CAN_1_conne01: 8 CGM

BO_ 2487940008 USDT_Rsp_From_MSM_D_CAN_4_connec: 8 CGM

BO_ 2487940776 USDT_Rsp_From_MSM_D_CAN_4_conn01: 8 CGM

BO_ 2487940010 USDT_Rsp_From_MSM_LR_CAN_4_conne: 8 CGM

BO_ 2487940778 USDT_Rsp_From_MSM_LR_CAN_4_con01: 8 CGM

BO_ 2487940006 USDT_Rsp_From_MSM_P_CAN_4_connec: 8 CGM

BO_ 2487940774 USDT_Rsp_From_MSM_P_CAN_4_conn01: 8 CGM

BO_ 2487940007 USDT_Rsp_From_MSM_RR_CAN_4_conne: 8 CGM

BO_ 2487940775 USDT_Rsp_From_MSM_RR_CAN_4_con01: 8 CGM

BO_ 2487940017 USDT_Rsp_From_MTCM_L_CAN_4_conne: 8 CGM

BO_ 2487940785 USDT_Rsp_From_MTCM_L_CAN_4_con01: 8 CGM

BO_ 2487940024 USDT_Rsp_From_MTCM_R_CAN_4_conne: 8 CGM

BO_ 2487940792 USDT_Rsp_From_MTCM_R_CAN_4_con01: 8 CGM

BO_ 2485842789 USDT_Rsp_From_NVM_CAN_2_connecto: 8 CGM

BO_ 2485843557 USDT_Rsp_From_NVM_CAN_2_connec01: 8 CGM

BO_ 2484794303 USDT_Rsp_From_PA_CAN_1_connector: 8 CGM

BO_ 2484795071 USDT_Rsp_From_PA_CAN_1_connect01: 8 CGM

BO_ 2497376617 USDT_Rsp_From_PDR_CAN_5_connecto: 8 PDR

BO_ 2497376873 USDT_Rsp_From_PDR_CAN_5_connec01: 8 PDR

BO_ 2497377129 USDT_Rsp_From_PDR_CAN_5_connec02: 8 PDR

BO_ 2497377385 USDT_Rsp_From_PDR_CAN_5_connec03: 8 PDR

BO_ 2497377641 USDT_Rsp_From_PDR_CAN_5_connec04: 8 PDR

BO_ 2497377897 USDT_Rsp_From_PDR_CAN_5_connec05: 8 PDR

BO_ 2487940004 USDT_Rsp_From_PTM_CAN_4_connecto: 8 CGM

BO_ 2487940772 USDT_Rsp_From_PTM_CAN_4_connec01: 8 CGM

BO_ 2485842714 USDT_Rsp_From_RDCM_CAN_2_connect: 8 CGM

BO_ 2485843482 USDT_Rsp_From_RDCM_CAN_2_conne01: 8 CGM

BO_ 2497376645 USDT_Rsp_From_RSC_CAN_5_connecto: 8 RSC

BO_ 2497376901 USDT_Rsp_From_RSC_CAN_5_connec01: 8 RSC

BO_ 2497377157 USDT_Rsp_From_RSC_CAN_5_connec02: 8 RSC

BO_ 2497377413 USDT_Rsp_From_RSC_CAN_5_connec03: 8 RSC

BO_ 2497377669 USDT_Rsp_From_RSC_CAN_5_connec04: 8 RSC

BO_ 2497377925 USDT_Rsp_From_RSC_CAN_5_connec05: 8 RSC

BO_ 2484794168 USDT_Rsp_From_SADS_CAN_1_connect: 8 CGM

BO_ 2484794936 USDT_Rsp_From_SADS_CAN_1_conne01: 8 CGM

BO_ 2485842731 USDT_Rsp_From_SBM_CAN_2_connecto: 8 CGM

BO_ 2485843499 USDT_Rsp_From_SBM_CAN_2_connec01: 8 CGM

BO_ 2487940025 USDT_Rsp_From_SBZA_L_CAN_4_conne: 8 CGM

BO_ 2487940793 USDT_Rsp_From_SBZA_L_CAN_4_con01: 8 CGM

BO_ 2487940026 USDT_Rsp_From_SBZA_R_CAN_4_conne: 8 CGM

BO_ 2487940794 USDT_Rsp_From_SBZA_R_CAN_4_con01: 8 CGM

BO_ 2484794306 USDT_Rsp_From_SCL_CAN_1_connecto: 8 CGM

BO_ 2484795074 USDT_Rsp_From_SCL_CAN_1_connec01: 8 CGM

BO_ 2484794200 USDT_Rsp_From_SDM_CAN_1_connecto: 8 CGM

BO_ 2484794968 USDT_Rsp_From_SDM_CAN_1_connec01: 8 CGM

BO_ 2486891334 USDT_Rsp_From_SIB_CAN_3_connecto: 8 CGM

BO_ 2486892102 USDT_Rsp_From_SIB_CAN_3_connec01: 8 CGM

BO_ 2492134355 USDT_Rsp_From_SRR_LF_CAN_8_conne: 8 CGM

BO_ 2492135123 USDT_Rsp_From_SRR_LF_CAN_8_con01: 8 CGM

BO_ 2492134359 USDT_Rsp_From_SRR_LR_CR_CAN_8_co: 8 CGM

BO_ 2492135127 USDT_Rsp_From_SRR_LR_CR_CAN_8_01: 8 CGM

BO_ 2492134358 USDT_Rsp_From_SRR_RF_CAN_8_conne: 8 CGM

BO_ 2492135126 USDT_Rsp_From_SRR_RF_CAN_8_con01: 8 CGM

BO_ 2492134360 USDT_Rsp_From_SRR_RR_CAN_8_conne: 8 CGM

BO_ 2492135128 USDT_Rsp_From_SRR_RR_CAN_8_con01: 8 CGM

BO_ 2492134361 USDT_Rsp_From_SRR_SLR_CAN_8_conn: 8 CGM

BO_ 2492135129 USDT_Rsp_From_SRR_SLR_CAN_8_co01: 8 CGM

BO_ 2492134362 USDT_Rsp_From_SRR_SRR_CAN_8_conn: 8 CGM

BO_ 2492135130 USDT_Rsp_From_SRR_SRR_CAN_8_co01: 8 CGM

BO_ 2487940013 USDT_Rsp_From_STC_CAN_4_connecto: 8 CGM

BO_ 2487940781 USDT_Rsp_From_STC_CAN_4_connec01: 8 CGM

BO_ 2486891292 USDT_Rsp_From_TCCM3_CAN_3_connec: 8 CGM

BO_ 2486892060 USDT_Rsp_From_TCCM3_CAN_3_conn01: 8 CGM

BO_ 2485842712 USDT_Rsp_From_TCM_CAN_2_connecto: 8 CGM

BO_ 2485843480 USDT_Rsp_From_TCM_CAN_2_connec01: 8 CGM

BO_ 2497376663 USDT_Rsp_From_TCP_CAN_5_connecto: 8 TCP

BO_ 2497376919 USDT_Rsp_From_TCP_CAN_5_connec01: 8 TCP

BO_ 2497377431 USDT_Rsp_From_TCP_CAN_5_connec02: 8 TCP

BO_ 2497377687 USDT_Rsp_From_TCP_CAN_5_connec03: 8 TCP

BO_ 2497377943 USDT_Rsp_From_TCP_CAN_5_connec04: 8 TCP

BO_ 2487939957 USDT_Rsp_From_TIM_CAN_4_connecto: 8 CGM

BO_ 2487940725 USDT_Rsp_From_TIM_CAN_4_connec01: 8 CGM

BO_ 2484794192 USDT_Rsp_From_UVM_CAN_1_connecto: 8 CGM

BO_ 2484794960 USDT_Rsp_From_UVM_CAN_1_connec01: 8 CGM

BO_ 2497376660 USDT_Rsp_From_VKM_CAN_5_connecto: 8 VKM

BO_ 2497376916 USDT_Rsp_From_VKM_CAN_5_connec01: 8 VKM

BO_ 2497377172 USDT_Rsp_From_VKM_CAN_5_connec02: 8 VKM

BO_ 2497377428 USDT_Rsp_From_VKM_CAN_5_connec03: 8 VKM

BO_ 2497377684 USDT_Rsp_From_VKM_CAN_5_connec04: 8 VKM

BO_ 2497377940 USDT_Rsp_From_VKM_CAN_5_connec05: 8 VKM

BO_ 2484794169 USDT_Rsp_From_VLM_CAN_1_connecto: 8 CGM

BO_ 2484794937 USDT_Rsp_From_VLM_CAN_1_connec01: 8 CGM

BO_ 2484794221 USDT_Rsp_From_VPM_CAN_1_connecto: 8 CGM

BO_ 2484794989 USDT_Rsp_From_VPM_CAN_1_connec01: 8 CGM

BO_ 2497376702 USDT_Rsp_From_WCM_CAN_5_connecto: 8 WCM

BO_ 2497376958 USDT_Rsp_From_WCM_CAN_5_connec01: 8 WCM

BO_ 2497377214 USDT_Rsp_From_WCM_CAN_5_connec02: 8 WCM

BO_ 2497377470 USDT_Rsp_From_WCM_CAN_5_connec03: 8 WCM

BO_ 2497377726 USDT_Rsp_From_WCM_CAN_5_connec04: 8 WCM

BO_ 2497377982 USDT_Rsp_From_WCM_CAN_5_connec05: 8 WCM

BO_ 2497507687 UUDT_Rsp_From_AGC_CAN_5_connecto: 8 AGC

BO_ 2497507943 UUDT_Rsp_From_AGC_CAN_5_connec01: 8 AGC

BO_ 2497508199 UUDT_Rsp_From_AGC_CAN_5_connec02: 8 AGC

BO_ 2497508455 UUDT_Rsp_From_AGC_CAN_5_connec03: 8 AGC

BO_ 2497508711 UUDT_Rsp_From_AGC_CAN_5_connec04: 8 AGC

BO_ 2497508967 UUDT_Rsp_From_AGC_CAN_5_connec05: 8 AGC

BO_ 2485973874 UUDT_Rsp_From_AHL_AFL_CAN_2_conn: 8 CGM

BO_ 2485974642 UUDT_Rsp_From_AHL_AFL_CAN_2_co01: 8 CGM

BO_ 2484925233 UUDT_Rsp_From_AHS_CAN_1_connecto: 8 CGM

BO_ 2484926001 UUDT_Rsp_From_AHS_CAN_1_connec01: 8 CGM

BO_ 2484925242 UUDT_Rsp_From_ALC_CAN_1_connecto: 8 CGM

BO_ 2484926010 UUDT_Rsp_From_ALC_CAN_1_connec01: 8 CGM

BO_ 2497507713 UUDT_Rsp_From_AMP_CAN_5_connecto: 8 AMP

BO_ 2497507969 UUDT_Rsp_From_AMP_CAN_5_connec01: 8 AMP

BO_ 2497508225 UUDT_Rsp_From_AMP_CAN_5_connec02: 8 AMP

BO_ 2497508481 UUDT_Rsp_From_AMP_CAN_5_connec03: 8 AMP

BO_ 2497508737 UUDT_Rsp_From_AMP_CAN_5_connec04: 8 AMP

BO_ 2497508993 UUDT_Rsp_From_AMP_CAN_5_connec05: 8 AMP

BO_ 2484925273 UUDT_Rsp_From_AOS_CAN_1_connecto: 8 CGM

BO_ 2484926041 UUDT_Rsp_From_AOS_CAN_1_connec01: 8 CGM

BO_ 2485973947 UUDT_Rsp_From_APA_CAN_2_connecto: 8 CGM

BO_ 2485974715 UUDT_Rsp_From_APA_CAN_2_connec01: 8 CGM

BO_ 2484925362 UUDT_Rsp_From_ARB_CAN_1_connecto: 8 CGM

BO_ 2484926130 UUDT_Rsp_From_ARB_CAN_1_connec01: 8 CGM

BO_ 2485973810 UUDT_Rsp_From_ARS_CAN_2_connecto: 8 CGM

BO_ 2485974578 UUDT_Rsp_From_ARS_CAN_2_connec01: 8 CGM

BO_ 2485973824 UUDT_Rsp_From_BCM_CAN_2_connecto: 8 CGM

BO_ 2485974592 UUDT_Rsp_From_BCM_CAN_2_connec01: 8 CGM

BO_ 2485973963 UUDT_Rsp_From_BSM_CAN_2_connecto: 8 CGM

BO_ 2485974731 UUDT_Rsp_From_BSM_CAN_2_connec01: 8 CGM

BO_ 2497508165 UUDT_Rsp_From_CGM_CAN_5_connecto: 8 CGM

BO_ 2497508933 UUDT_Rsp_From_CGM_CAN_5_connec01: 8 CGM

BO_ 2485973821 UUDT_Rsp_From_CMMa_CAN_2_connect: 8 CGM

BO_ 2485974589 UUDT_Rsp_From_CMMa_CAN_2_conne01: 8 CGM

BO_ 2485973822 UUDT_Rsp_From_CMMb_CAN_2_connect: 8 CGM

BO_ 2485974590 UUDT_Rsp_From_CMMb_CAN_2_conne01: 8 CGM

BO_ 2497507712 UUDT_Rsp_From_CSM_CAN_5_connecto: 8 CSM

BO_ 2497507968 UUDT_Rsp_From_CSM_CAN_5_connec01: 8 CSM

BO_ 2497508224 UUDT_Rsp_From_CSM_CAN_5_connec02: 8 CSM

BO_ 2497508480 UUDT_Rsp_From_CSM_CAN_5_connec03: 8 CSM

BO_ 2497508736 UUDT_Rsp_From_CSM_CAN_5_connec04: 8 CSM

BO_ 2485973787 UUDT_Rsp_From_DCM_CAN_2_connecto: 8 CGM

BO_ 2485974555 UUDT_Rsp_From_DCM_CAN_2_connec01: 8 CGM

BO_ 2487022356 UUDT_Rsp_From_DEFC_CAN_3_connect: 8 CGM

BO_ 2487023124 UUDT_Rsp_From_DEFC_CAN_3_conne01: 8 CGM

BO_ 2485973866 UUDT_Rsp_From_DMS_CAN_2_connecto: 8 CGM

BO_ 2485974634 UUDT_Rsp_From_DMS_CAN_2_connec01: 8 CGM

BO_ 2485973800 UUDT_Rsp_From_EBCM_CAN_2_connect: 8 CGM

BO_ 2485974568 UUDT_Rsp_From_EBCM_CAN_2_conne01: 8 CGM

BO_ 2485973777 UUDT_Rsp_From_ECM_CAN_2_connecto: 8 CGM

BO_ 2485974545 UUDT_Rsp_From_ECM_CAN_2_connec01: 8 CGM

BO_ 2485973783 UUDT_Rsp_From_ECP_E_CAN_2_connec: 8 CGM

BO_ 2485974551 UUDT_Rsp_From_ECP_E_CAN_2_conn01: 8 CGM

BO_ 2485973789 UUDT_Rsp_From_ECP_MC_CAN_2_conne: 8 CGM

BO_ 2485974557 UUDT_Rsp_From_ECP_MC_CAN_2_con01: 8 CGM

BO_ 2485973825 UUDT_Rsp_From_ELM_CAN_2_connecto: 8 CGM

BO_ 2485974593 UUDT_Rsp_From_ELM_CAN_2_connec01: 8 CGM

BO_ 2492265324 UUDT_Rsp_From_EOCM_CAN_8_connect: 8 CGM

BO_ 2492266092 UUDT_Rsp_From_EOCM_CAN_8_conne01: 8 CGM

BO_ 2492265316 UUDT_Rsp_From_EOCM_HCP1_CAN_8_co: 8 CGM

BO_ 2492266084 UUDT_Rsp_From_EOCM_HCP1_CAN_8_01: 8 CGM

BO_ 2492265435 UUDT_Rsp_From_EOCM_HCP2_CAN_8_co: 8 CGM

BO_ 2492266203 UUDT_Rsp_From_EOCM_HCP2_CAN_8_01: 8 CGM

BO_ 2485973949 UUDT_Rsp_From_FCM_CAN_2_connecto: 8 CGM

BO_ 2485974717 UUDT_Rsp_From_FCM_CAN_2_connec01: 8 CGM

BO_ 2492265404 UUDT_Rsp_From_FCM_LC_CAN_8_conne: 8 CGM

BO_ 2492266172 UUDT_Rsp_From_FCM_LC_CAN_8_con01: 8 CGM

BO_ 2492265326 UUDT_Rsp_From_HDLM_CAN_8_connect: 8 CGM

BO_ 2492266094 UUDT_Rsp_From_HDLM_CAN_8_conne01: 8 CGM

BO_ 2497507682 UUDT_Rsp_From_HUD_CAN_CAN_5_conn: 8 HUD_CAN

BO_ 2497507938 UUDT_Rsp_From_HUD_CAN_CAN_5_co01: 8 HUD_CAN

BO_ 2497508194 UUDT_Rsp_From_HUD_CAN_CAN_5_co02: 8 HUD_CAN

BO_ 2497508450 UUDT_Rsp_From_HUD_CAN_CAN_5_co03: 8 HUD_CAN

BO_ 2497508706 UUDT_Rsp_From_HUD_CAN_CAN_5_co04: 8 HUD_CAN

BO_ 2497508962 UUDT_Rsp_From_HUD_CAN_CAN_5_co05: 8 HUD_CAN

BO_ 2497507688 UUDT_Rsp_From_HVAC_FP_F_CAN_5_co: 8 HVAC_FP_F

BO_ 2497507944 UUDT_Rsp_From_HVAC_FP_F_CAN_5_01: 8 HVAC_FP_F

BO_ 2497508200 UUDT_Rsp_From_HVAC_FP_F_CAN_5_02: 8 HVAC_FP_F

BO_ 2497508456 UUDT_Rsp_From_HVAC_FP_F_CAN_5_03: 8 HVAC_FP_F

BO_ 2497508712 UUDT_Rsp_From_HVAC_FP_F_CAN_5_04: 8 HVAC_FP_F

BO_ 2497508968 UUDT_Rsp_From_HVAC_FP_F_CAN_5_05: 8 HVAC_FP_F

BO_ 2497507738 UUDT_Rsp_From_HVAC_FP_R_CAN_5_co: 8 HVAC_FP_R

BO_ 2497507994 UUDT_Rsp_From_HVAC_FP_R_CAN_5_01: 8 HVAC_FP_R

BO_ 2497508250 UUDT_Rsp_From_HVAC_FP_R_CAN_5_02: 8 HVAC_FP_R

BO_ 2497508506 UUDT_Rsp_From_HVAC_FP_R_CAN_5_03: 8 HVAC_FP_R

BO_ 2497508762 UUDT_Rsp_From_HVAC_FP_R_CAN_5_04: 8 HVAC_FP_R

BO_ 2497509018 UUDT_Rsp_From_HVAC_FP_R_CAN_5_05: 8 HVAC_FP_R

BO_ 2485973779 UUDT_Rsp_From_ICCM_CAN_2_connect: 8 CGM

BO_ 2485974547 UUDT_Rsp_From_ICCM_CAN_2_conne01: 8 CGM

BO_ 2497507686 UUDT_Rsp_From_ICS_Info_CAN_5_con: 8 ICS_Info

BO_ 2497507942 UUDT_Rsp_From_ICS_Info_CAN_5_c01: 8 ICS_Info

BO_ 2497508198 UUDT_Rsp_From_ICS_Info_CAN_5_c02: 8 ICS_Info

BO_ 2497508454 UUDT_Rsp_From_ICS_Info_CAN_5_c03: 8 ICS_Info

BO_ 2497508710 UUDT_Rsp_From_ICS_Info_CAN_5_c04: 8 ICS_Info

BO_ 2497508966 UUDT_Rsp_From_ICS_Info_CAN_5_c05: 8 ICS_Info

BO_ 2497507680 UUDT_Rsp_From_IPC_CAN_5_connecto: 8 IPC

BO_ 2497507936 UUDT_Rsp_From_IPC_CAN_5_connec01: 8 IPC

BO_ 2497508192 UUDT_Rsp_From_IPC_CAN_5_connec02: 8 IPC

BO_ 2497508448 UUDT_Rsp_From_IPC_CAN_5_connec03: 8 IPC

BO_ 2497508704 UUDT_Rsp_From_IPC_CAN_5_connec04: 8 IPC

BO_ 2497508960 UUDT_Rsp_From_IPC_CAN_5_connec05: 8 IPC

BO_ 2485973990 UUDT_Rsp_From_LIB1_CAN_2_connect: 8 CGM

BO_ 2485974758 UUDT_Rsp_From_LIB1_CAN_2_conne01: 8 CGM

BO_ 2492265426 UUDT_Rsp_From_LRR_CAN_8_connecto: 8 CGM

BO_ 2492266194 UUDT_Rsp_From_LRR_CAN_8_connec01: 8 CGM

BO_ 2497507725 UUDT_Rsp_From_MFC_CAN_5_connecto: 8 MFC

BO_ 2497507981 UUDT_Rsp_From_MFC_CAN_5_connec01: 8 MFC

BO_ 2497508237 UUDT_Rsp_From_MFC_CAN_5_connec02: 8 MFC

BO_ 2497508493 UUDT_Rsp_From_MFC_CAN_5_connec03: 8 MFC

BO_ 2497508749 UUDT_Rsp_From_MFC_CAN_5_connec04: 8 MFC

BO_ 2497509005 UUDT_Rsp_From_MFC_CAN_5_connec05: 8 MFC

BO_ 2488071083 UUDT_Rsp_From_MRCM_L_CAN_4_conne: 8 CGM

BO_ 2488071851 UUDT_Rsp_From_MRCM_L_CAN_4_con01: 8 CGM

BO_ 2488071084 UUDT_Rsp_From_MRCM_R_CAN_4_conne: 8 CGM

BO_ 2488071852 UUDT_Rsp_From_MRCM_R_CAN_4_con01: 8 CGM

BO_ 2484925276 UUDT_Rsp_From_MSB1_CAN_1_connect: 8 CGM

BO_ 2484926044 UUDT_Rsp_From_MSB1_CAN_1_conne01: 8 CGM

BO_ 2484925278 UUDT_Rsp_From_MSB2_CAN_1_connect: 8 CGM

BO_ 2484926046 UUDT_Rsp_From_MSB2_CAN_1_conne01: 8 CGM

BO_ 2488071080 UUDT_Rsp_From_MSM_D_CAN_4_connec: 8 CGM

BO_ 2488071848 UUDT_Rsp_From_MSM_D_CAN_4_conn01: 8 CGM

BO_ 2488071082 UUDT_Rsp_From_MSM_LR_CAN_4_conne: 8 CGM

BO_ 2488071850 UUDT_Rsp_From_MSM_LR_CAN_4_con01: 8 CGM

BO_ 2488071078 UUDT_Rsp_From_MSM_P_CAN_4_connec: 8 CGM

BO_ 2488071846 UUDT_Rsp_From_MSM_P_CAN_4_conn01: 8 CGM

BO_ 2488071079 UUDT_Rsp_From_MSM_RR_CAN_4_conne: 8 CGM

BO_ 2488071847 UUDT_Rsp_From_MSM_RR_CAN_4_con01: 8 CGM

BO_ 2488071089 UUDT_Rsp_From_MTCM_L_CAN_4_conne: 8 CGM

BO_ 2488071857 UUDT_Rsp_From_MTCM_L_CAN_4_con01: 8 CGM

BO_ 2488071096 UUDT_Rsp_From_MTCM_R_CAN_4_conne: 8 CGM

BO_ 2488071864 UUDT_Rsp_From_MTCM_R_CAN_4_con01: 8 CGM

BO_ 2485973861 UUDT_Rsp_From_NVM_CAN_2_connecto: 8 CGM

BO_ 2485974629 UUDT_Rsp_From_NVM_CAN_2_connec01: 8 CGM

BO_ 2484925375 UUDT_Rsp_From_PA_CAN_1_connector: 8 CGM

BO_ 2484926143 UUDT_Rsp_From_PA_CAN_1_connect01: 8 CGM

BO_ 2497507689 UUDT_Rsp_From_PDR_CAN_5_connecto: 8 PDR

BO_ 2497507945 UUDT_Rsp_From_PDR_CAN_5_connec01: 8 PDR

BO_ 2497508201 UUDT_Rsp_From_PDR_CAN_5_connec02: 8 PDR

BO_ 2497508457 UUDT_Rsp_From_PDR_CAN_5_connec03: 8 PDR

BO_ 2497508713 UUDT_Rsp_From_PDR_CAN_5_connec04: 8 PDR

BO_ 2497508969 UUDT_Rsp_From_PDR_CAN_5_connec05: 8 PDR

BO_ 2488071076 UUDT_Rsp_From_PTM_CAN_4_connecto: 8 CGM

BO_ 2488071844 UUDT_Rsp_From_PTM_CAN_4_connec01: 8 CGM

BO_ 2485973786 UUDT_Rsp_From_RDCM_CAN_2_connect: 8 CGM

BO_ 2485974554 UUDT_Rsp_From_RDCM_CAN_2_conne01: 8 CGM

BO_ 2497507717 UUDT_Rsp_From_RSC_CAN_5_connecto: 8 RSC

BO_ 2497507973 UUDT_Rsp_From_RSC_CAN_5_connec01: 8 RSC

BO_ 2497508229 UUDT_Rsp_From_RSC_CAN_5_connec02: 8 RSC

BO_ 2497508485 UUDT_Rsp_From_RSC_CAN_5_connec03: 8 RSC

BO_ 2497508741 UUDT_Rsp_From_RSC_CAN_5_connec04: 8 RSC

BO_ 2497508997 UUDT_Rsp_From_RSC_CAN_5_connec05: 8 RSC

BO_ 2484925240 UUDT_Rsp_From_SADS_CAN_1_connect: 8 CGM

BO_ 2484926008 UUDT_Rsp_From_SADS_CAN_1_conne01: 8 CGM

BO_ 2485973803 UUDT_Rsp_From_SBM_CAN_2_connecto: 8 CGM

BO_ 2485974571 UUDT_Rsp_From_SBM_CAN_2_connec01: 8 CGM

BO_ 2488071097 UUDT_Rsp_From_SBZA_L_CAN_4_conne: 8 CGM

BO_ 2488071865 UUDT_Rsp_From_SBZA_L_CAN_4_con01: 8 CGM

BO_ 2488071098 UUDT_Rsp_From_SBZA_R_CAN_4_conne: 8 CGM

BO_ 2488071866 UUDT_Rsp_From_SBZA_R_CAN_4_con01: 8 CGM

BO_ 2484925378 UUDT_Rsp_From_SCL_CAN_1_connecto: 8 CGM

BO_ 2484926146 UUDT_Rsp_From_SCL_CAN_1_connec01: 8 CGM

BO_ 2484925272 UUDT_Rsp_From_SDM_CAN_1_connecto: 8 CGM

BO_ 2484926040 UUDT_Rsp_From_SDM_CAN_1_connec01: 8 CGM

BO_ 2487022406 UUDT_Rsp_From_SIB_CAN_3_connecto: 8 CGM

BO_ 2487023174 UUDT_Rsp_From_SIB_CAN_3_connec01: 8 CGM

BO_ 2492265427 UUDT_Rsp_From_SRR_LF_CAN_8_conne: 8 CGM

BO_ 2492266195 UUDT_Rsp_From_SRR_LF_CAN_8_con01: 8 CGM

BO_ 2492265431 UUDT_Rsp_From_SRR_LR_CR_CAN_8_co: 8 CGM

BO_ 2492266199 UUDT_Rsp_From_SRR_LR_CR_CAN_8_01: 8 CGM

BO_ 2492265430 UUDT_Rsp_From_SRR_RF_CAN_8_conne: 8 CGM

BO_ 2492266198 UUDT_Rsp_From_SRR_RF_CAN_8_con01: 8 CGM

BO_ 2492265432 UUDT_Rsp_From_SRR_RR_CAN_8_conne: 8 CGM

BO_ 2492266200 UUDT_Rsp_From_SRR_RR_CAN_8_con01: 8 CGM

BO_ 2492265433 UUDT_Rsp_From_SRR_SLR_CAN_8_conn: 8 CGM

BO_ 2492266201 UUDT_Rsp_From_SRR_SLR_CAN_8_co01: 8 CGM

BO_ 2492265434 UUDT_Rsp_From_SRR_SRR_CAN_8_conn: 8 CGM

BO_ 2492266202 UUDT_Rsp_From_SRR_SRR_CAN_8_co01: 8 CGM

BO_ 2488071085 UUDT_Rsp_From_STC_CAN_4_connecto: 8 CGM

BO_ 2488071853 UUDT_Rsp_From_STC_CAN_4_connec01: 8 CGM

BO_ 2487022364 UUDT_Rsp_From_TCCM3_CAN_3_connec: 8 CGM

BO_ 2487023132 UUDT_Rsp_From_TCCM3_CAN_3_conn01: 8 CGM

BO_ 2485973784 UUDT_Rsp_From_TCM_CAN_2_connecto: 8 CGM

BO_ 2485974552 UUDT_Rsp_From_TCM_CAN_2_connec01: 8 CGM

BO_ 2497507735 UUDT_Rsp_From_TCP_CAN_5_connecto: 8 TCP

BO_ 2497507991 UUDT_Rsp_From_TCP_CAN_5_connec01: 8 TCP

BO_ 2497508503 UUDT_Rsp_From_TCP_CAN_5_connec02: 8 TCP

BO_ 2497508759 UUDT_Rsp_From_TCP_CAN_5_connec03: 8 TCP

BO_ 2497509015 UUDT_Rsp_From_TCP_CAN_5_connec04: 8 TCP

BO_ 2488071029 UUDT_Rsp_From_TIM_CAN_4_connecto: 8 CGM

BO_ 2488071797 UUDT_Rsp_From_TIM_CAN_4_connec01: 8 CGM

BO_ 2484925264 UUDT_Rsp_From_UVM_CAN_1_connecto: 8 CGM

BO_ 2484926032 UUDT_Rsp_From_UVM_CAN_1_connec01: 8 CGM

BO_ 2497507732 UUDT_Rsp_From_VKM_CAN_5_connecto: 8 VKM

BO_ 2497507988 UUDT_Rsp_From_VKM_CAN_5_connec01: 8 VKM

BO_ 2497508244 UUDT_Rsp_From_VKM_CAN_5_connec02: 8 VKM

BO_ 2497508500 UUDT_Rsp_From_VKM_CAN_5_connec03: 8 VKM

BO_ 2497508756 UUDT_Rsp_From_VKM_CAN_5_connec04: 8 VKM

BO_ 2497509012 UUDT_Rsp_From_VKM_CAN_5_connec05: 8 VKM

BO_ 2484925241 UUDT_Rsp_From_VLM_CAN_1_connecto: 8 CGM

BO_ 2484926009 UUDT_Rsp_From_VLM_CAN_1_connec01: 8 CGM

BO_ 2484925293 UUDT_Rsp_From_VPM_CAN_1_connecto: 8 CGM

BO_ 2484926061 UUDT_Rsp_From_VPM_CAN_1_connec01: 8 CGM

BO_ 2497507774 UUDT_Rsp_From_WCM_CAN_5_connecto: 8 WCM

BO_ 2497508030 UUDT_Rsp_From_WCM_CAN_5_connec01: 8 WCM

BO_ 2497508286 UUDT_Rsp_From_WCM_CAN_5_connec02: 8 WCM

BO_ 2497508542 UUDT_Rsp_From_WCM_CAN_5_connec03: 8 WCM

BO_ 2497508798 UUDT_Rsp_From_WCM_CAN_5_connec04: 8 WCM

BO_ 2497509054 UUDT_Rsp_From_WCM_CAN_5_connec05: 8 WCM

BO_ 1111 UnlckKeyStorCrptoDat1_PDU: 8 CGM
 SG_ UnlckKeyStorCrptoDat1 : 7|64@0+ (1,0) [0|1.84467e+019] "" CSM,RadioLow

BO_ 1112 UnlckKeyStorCrptoDat2_PDU: 8 CGM
 SG_ UnlckKeyStorCrptoDat2 : 7|64@0+ (1,0) [0|1.84467e+019] "" CSM,RadioLow

BO_ 404 VKM_NM_PDU_On_CAN_5_Cluster: 8 VKM
 SG_ ISignal_VKM_CAN_5_Cluster : 23|48@0+ (1,0) [0|281474976710655] "" AGC,AMP,CGM,CSM,HUD_CAN,HVAC_FP_F,HVAC_FP_R,ICS_Info,IPC,PDR,MFC,RSC,RadioLow,TCP,WCM

BO_ 1113 VehIdNmDig10_17_PDU: 8 CGM
 SG_ VehIdNmDig10_17 : 7|64@0+ (1,0) [0|18446744073709551615] "" CSM,PDR,RadioLow,TCP,VKM

BO_ 1114 VehIdNmDig2_9_PDU: 8 CGM
 SG_ VehIdNmDig2_9 : 7|64@0+ (1,0) [0|18446744073709551615] "" CSM,PDR,RadioLow,TCP,VKM

BO_ 1797 VehMtnMvmt_PCSM_PDU: 8 CGM
 SG_ VehMtnMvmt_PCSM : 0|64@1+ (1,0) [0|1.84467e+019] "" TCP

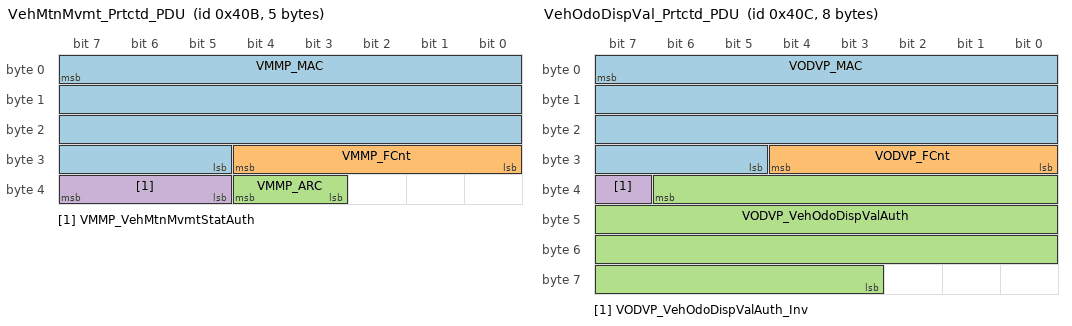
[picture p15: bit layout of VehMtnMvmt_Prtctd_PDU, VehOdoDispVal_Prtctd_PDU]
BO_ 1035 VehMtnMvmt_Prtctd_PDU: 5 CGM
 SG_ VMMP_MAC : 7|27@0+ (1,0) [0|1.34218e+008] "" TCP
 SG_ VMMP_FCnt : 28|5@0+ (1,0) [0|31] "" TCP
 SG_ VMMP_ARC : 36|2@0+ (1,0) [0|3] "" TCP
 SG_ VMMP_VehMtnMvmtStatAuth : 39|3@0+ (1,0) [0|4] "" CSM,ICS_Info,RadioLow,TCP

BO_ 1798 VehOdoDispVal_PCSM_PDU: 8 CGM
 SG_ VehOdoDispVal_PCSM : 0|64@1+ (1,0) [0|1.84467e+019] "" IPC

BO_ 1036 VehOdoDispVal_Prtctd_PDU: 8 CGM
 SG_ VODVP_MAC : 7|27@0+ (1,0) [0|1.34218e+008] "" IPC
 SG_ VODVP_FCnt : 28|5@0+ (1,0) [0|31] "" IPC
 SG_ VODVP_VehOdoDispValAuth : 38|28@0+ (0.015625,0) [0|4.1943e+006] "km" CSM,IPC,PDR,RadioLow,TCP,VKM
 SG_ VODVP_VehOdoDispValAuth_Inv : 39|1@0+ (1,0) [0|1] "" CSM,IPC,PDR,RadioLow,TCP

BO_ 1815 VehOdoStrdDispVal_PCSM_PDU: 8 IPC
 SG_ VehOdoStrdDispVal_PCSM : 0|64@1+ (1,0) [0|1.84467e+019] "" Vector__XXX

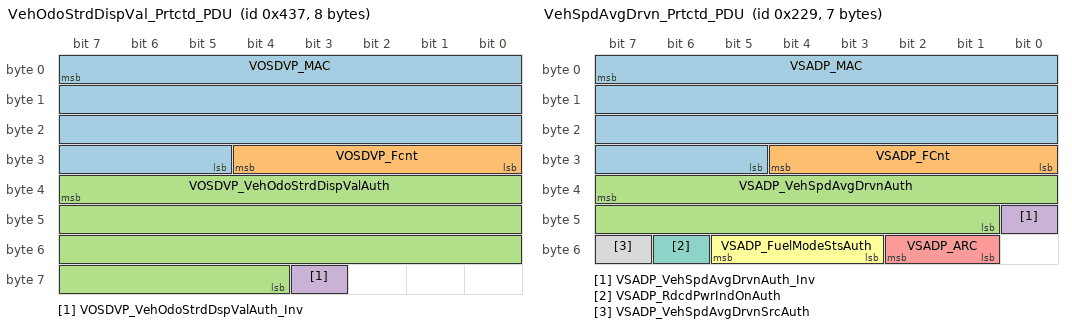
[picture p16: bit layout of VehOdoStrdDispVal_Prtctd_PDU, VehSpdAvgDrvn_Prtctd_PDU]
BO_ 1079 VehOdoStrdDispVal_Prtctd_PDU: 8 IPC
 SG_ VOSDVP_MAC : 7|27@0+ (1,0) [0|1.34218e+008] "" Vector__XXX
 SG_ VOSDVP_Fcnt : 28|5@0+ (1,0) [0|31] "" Vector__XXX
 SG_ VOSDVP_VehOdoStrdDispValAuth : 39|28@0+ (0.015625,0) [0|4.1943e+006] "km" Vector__XXX
 SG_ VOSDVP_VehOdoStrdDspValAuth_Inv : 59|1@0+ (1,0) [0|1] "" Vector__XXX

BO_ 1807 VehSpdAvgDrvn_PCSM_PDU: 8 CGM
 SG_ VehSpdAvgDrvn_PCSM : 0|64@1+ (1,0) [0|1.84467e+019] "" IPC,TCP

BO_ 553 VehSpdAvgDrvn_Prtctd_PDU: 7 CGM
 SG_ VSADP_MAC : 7|27@0+ (1,0) [0|1.34218e+008] "" IPC,TCP
 SG_ VSADP_FCnt : 28|5@0+ (1,0) [0|31] "" IPC,TCP
 SG_ VSADP_VehSpdAvgDrvnAuth : 39|15@0+ (0.015625,0) [0|511.984] "km / h" AGC,AMP,CSM,HUD_CAN,HVAC_FP_F,HVAC_FP_R,ICS_Info,IPC,PDR,MFC,RSC,RadioLow,TCP,VKM,WCM
 SG_ VSADP_VehSpdAvgDrvnAuth_Inv : 40|1@0+ (1,0) [0|1] "" AGC,AMP,CSM,HUD_CAN,HVAC_FP_F,HVAC_FP_R,ICS_Info,IPC,PDR,RSC,RadioLow,TCP,WCM
 SG_ VSADP_ARC : 50|2@0+ (1,0) [0|3] "" IPC,TCP
 SG_ VSADP_FuelModeStsAuth : 53|3@0+ (1,0) [0|4] "" CSM,IPC,TCP,VKM
 SG_ VSADP_RdcdPwrIndOnAuth : 54|1@0+ (1,0) [0|1] "" AMP,CSM,IPC,TCP
 SG_ VSADP_VehSpdAvgDrvnSrcAuth : 55|1@0+ (1,0) [0|1] "" AGC,AMP,CSM,HUD_CAN,HVAC_FP_F,HVAC_FP_R,ICS_Info,IPC,PDR,RSC,RadioLow,TCP

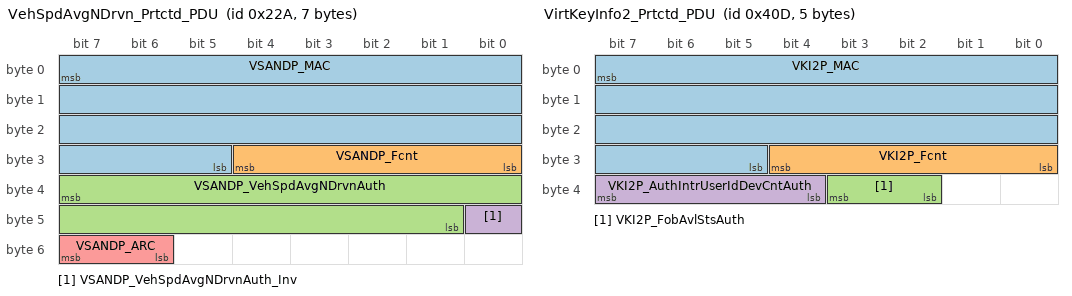
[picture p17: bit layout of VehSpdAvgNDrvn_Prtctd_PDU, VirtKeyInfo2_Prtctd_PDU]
BO_ 554 VehSpdAvgNDrvn_Prtctd_PDU: 7 CGM
 SG_ VSANDP_MAC : 7|27@0+ (1,0) [0|1.34218e+008] "" Vector__XXX
 SG_ VSANDP_Fcnt : 28|5@0+ (1,0) [0|31] "" Vector__XXX
 SG_ VSANDP_VehSpdAvgNDrvnAuth : 39|15@0+ (0.015625,0) [0|511.984] "Km/h" AMP,CSM,IPC,PDR,RadioLow,TCP
 SG_ VSANDP_VehSpdAvgNDrvnAuth_Inv : 40|1@0+ (1,0) [0|1] "" AMP,CSM,IPC,PDR,RadioLow,TCP
 SG_ VSANDP_ARC : 55|2@0+ (1,0) [0|3] "" Vector__XXX

BO_ 1042 VirtKeyInfo2_PCSM_PDU: 8 CGM
 SG_ VirtKeyInfo2_PCSM : 0|64@1+ (1,0) [0|1.84467e+019] "" TCP

BO_ 1037 VirtKeyInfo2_Prtctd_PDU: 5 CGM
 SG_ VKI2P_MAC : 7|27@0+ (1,0) [0|1.34218e+008] "" TCP
 SG_ VKI2P_Fcnt : 28|5@0+ (1,0) [0|31] "" TCP
 SG_ VKI2P_FobAvlStsAuth : 35|2@0+ (1,0) [0|3] "" TCP,VKM
 SG_ VKI2P_AuthIntrUserIdDevCntAuth : 39|4@0+ (1,0) [0|15] "Count" TCP

BO_ 1822 VirtKeyInfo3_PCSM_PDU: 8 VKM
 SG_ VirtKeyInfo3_PCSM : 0|64@1+ (1,0) [0|1.84467e+019] "" TCP

BO_ 1260 VirtKeyInfo3_Prtctd_PDU: 8 VKM
 SG_ VKI3P_MAC : 7|27@0+ (1,0) [0|1.34218e+008] "" TCP
 SG_ VKI3P_FCnt : 28|5@0+ (1,0) [0|31] "" TCP
 SG_ VKI3P_PncHrnReqAuth : 33|2@0+ (1,0) [0|2] "" TCP
 SG_ VKI3P_MirUnfldReqdAuth : 34|1@0+ (1,0) [0|1] "" TCP
 SG_ VKI3P_MirFoldReqdAuth : 35|1@0+ (1,0) [0|1] "" TCP
 SG_ VKI3P_FobAvlReqAuth : 37|2@0+ (1,0) [0|3] "" TCP
 SG_ VKI3P_ChrgOnReqdAuth : 38|1@0+ (1,0) [0|1] "" TCP
 SG_ VKI3P_ChrgOffReqdAuth : 39|1@0+ (1,0) [0|1] "" TCP
 SG_ VKI3P_RmtLctrHrnReqAuth : 40|3@0+ (1,0) [0|4] "" TCP
 SG_ VKI3P_RmtFlOprtdHtrOnReqdAuth : 41|1@0+ (1,0) [0|1] "" TCP
 SG_ VKI3P_RmtFlOprtdHtrOffReqdAuth : 42|1@0+ (1,0) [0|1] "" TCP
 SG_ VKI3P_PwrToPCtlReqAuth : 45|3@0+ (1,0) [0|4] "" TCP
 SG_ VKI3P_PncLgtReqAuth : 47|2@0+ (1,0) [0|2] "" TCP
 SG_ VKI3P_VehStrtReqdAuth : 48|1@0+ (1,0) [0|1] "" TCP
 SG_ VKI3P_VehStopReqdAuth : 49|1@0+ (1,0) [0|1] "" TCP
 SG_ VKI3P_RsrvtnRvkStsAuth : 52|3@0+ (1,0) [0|4] "" TCP
 SG_ VKI3P_RmtLctrLgtReqAuth : 53|1@0+ (1,0) [0|1] "" TCP
 SG_ VKI3P_WndOpnReqdAuth : 62|1@0+ (1,0) [0|1] "" TCP
 SG_ VKI3P_WndClsReqdAuth : 63|1@0+ (1,0) [0|1] "" TCP

BO_ 1823 VirtKeyInfo_PCSM_PDU: 8 VKM
 SG_ VirtKeyInfo_PCSM : 0|64@1+ (1,0) [0|1.84467e+019] "" Vector__XXX

BO_ 1288 VirtKeyInfo_Prtctd_PDU: 8 VKM
 SG_ VKIP_MAC : 7|27@0+ (1,0) [0|1.34218e+008] "" Vector__XXX
 SG_ VKIP_FCnt : 28|5@0+ (1,0) [0|31] "" Vector__XXX
 SG_ VKIP_ExtLtStsAuth : 33|3@0+ (1,0) [0|5] "" Vector__XXX
 SG_ VKIP_ExtFrtStsAuth : 36|3@0+ (1,0) [0|5] "" Vector__XXX
 SG_ VKIP_DrvrDrUnlckReqdAuth : 37|1@0+ (1,0) [0|1] "" Vector__XXX
 SG_ VKIP_DrLckReqdAuth : 38|1@0+ (1,0) [0|1] "" Vector__XXX
 SG_ VKIP_AllDrUnlckReqdAuth : 39|1@0+ (1,0) [0|1] "" Vector__XXX
 SG_ VKIP_FrtCmptRelReqdAuth : 40|1@0+ (1,0) [0|1] "" Vector__XXX
 SG_ VKIP_ExtRtStsAuth : 43|3@0+ (1,0) [0|5] "" Vector__XXX
 SG_ VKIP_ExtRrStsAuth : 46|3@0+ (1,0) [0|5] "" Vector__XXX
 SG_ VKIP_PwrRrClsrCtlReqAuth : 48|2@0+ (1,0) [0|2] "" Vector__XXX
 SG_ VKIP_IntrZnCntAuth : 51|3@0+ (1,0) [0|7] "" Vector__XXX
 SG_ VKIP_FrtRtEntZnDevPrsntAuth : 52|1@0+ (1,0) [0|1] "" Vector__XXX
 SG_ VKIP_RrLtEntZnDevPrsntAuth : 53|1@0+ (1,0) [0|1] "" Vector__XXX
 SG_ VKIP_FrtLtEntZnDevPrsntAuth : 54|1@0+ (1,0) [0|1] "" Vector__XXX
 SG_ VKIP_WlcmZnDevPrsntAuth : 55|1@0+ (1,0) [0|1] "" Vector__XXX
 SG_ VKIP_RrRtEntZnDevPrsntAuth : 59|1@0+ (1,0) [0|1] "" Vector__XXX
 SG_ VKIP_RrExtZnDevPrsntAuth : 60|1@0+ (1,0) [0|1] "" Vector__XXX
 SG_ VKIP_RrClsrRelReqdAuth : 61|1@0+ (1,0) [0|1] "" Vector__XXX
 SG_ VKIP_RrClsrOnAprchReqdAuth : 62|1@0+ (1,0) [0|1] "" Vector__XXX

BO_ 1105 VirtKeyRsrvtnRvk_PCSM_PDU: 8 TCP
 SG_ VirtKeyRsrvtnRvk_PCSM : 0|64@1+ (1,0) [0|1.84467e+019] "" VKM

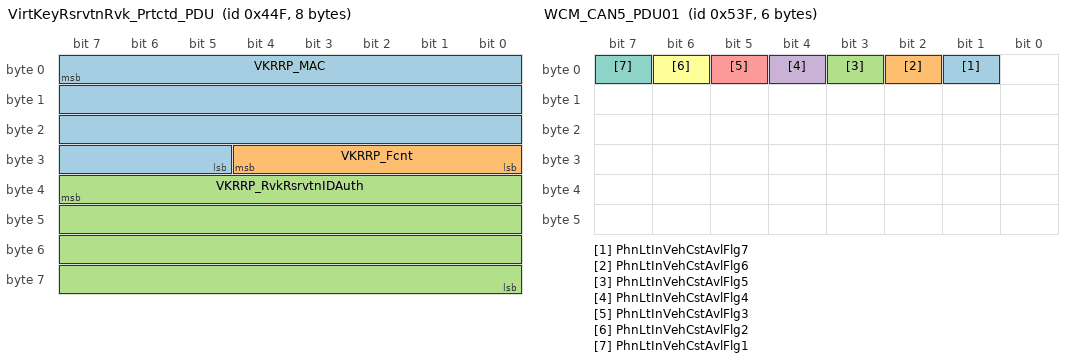
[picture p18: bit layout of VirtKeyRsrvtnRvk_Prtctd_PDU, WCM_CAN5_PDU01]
BO_ 1103 VirtKeyRsrvtnRvk_Prtctd_PDU: 8 TCP
 SG_ VKRRP_MAC : 7|27@0+ (1,0) [0|1.34218e+008] "" VKM
 SG_ VKRRP_Fcnt : 28|5@0+ (1,0) [0|31] "" VKM
 SG_ VKRRP_RvkRsrvtnIDAuth : 39|32@0+ (1,0) [0|4.29497e+009] "" VKM

BO_ 1343 WCM_CAN5_PDU01: 6 WCM
 SG_ PhnLtInVehCstAvlFlg7 : 1|1@0+ (1,0) [0|1] "" CSM,RadioLow
 SG_ PhnLtInVehCstAvlFlg6 : 2|1@0+ (1,0) [0|1] "" CSM,RadioLow
 SG_ PhnLtInVehCstAvlFlg5 : 3|1@0+ (1,0) [0|1] "" CSM,RadioLow
 SG_ PhnLtInVehCstAvlFlg4 : 4|1@0+ (1,0) [0|1] "" CSM,RadioLow
 SG_ PhnLtInVehCstAvlFlg3 : 5|1@0+ (1,0) [0|1] "" CSM,RadioLow
 SG_ PhnLtInVehCstAvlFlg2 : 6|1@0+ (1,0) [0|1] "" CSM,RadioLow
 SG_ PhnLtInVehCstAvlFlg1 : 7|1@0+ (1,0) [0|1] "" CSM,RadioLow

BO_ 1344 WCM_CAN5_PDU02: 6 WCM
 SG_ PhnLtInVehIndOn : 4|1@0+ (1,0) [0|1] "" IPC
 SG_ WrlsChrgSysChrgStat : 7|3@0+ (1,0) [0|7] "" CSM,RadioLow

BO_ 1345 WCM_CAN5_PDU03: 6 WCM
 SG_ PhnLtInVehCstSetAval : 4|1@0+ (1,0) [0|1] "" CSM,RadioLow
 SG_ PhnLtInVehCstCurrSetVal : 7|3@0+ (1,0) [0|7] "" CSM,RadioLow

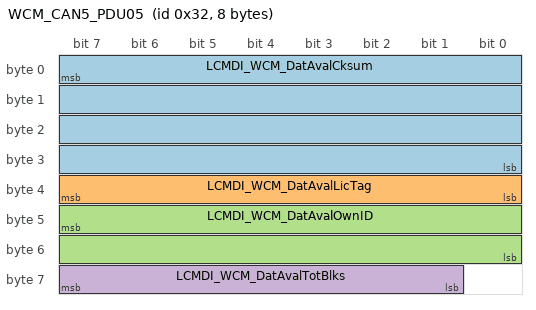
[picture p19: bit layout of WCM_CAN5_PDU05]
BO_ 50 WCM_CAN5_PDU05: 8 WCM
 SG_ LCMDI_WCM_DatAvalCksum : 7|32@0+ (1,0) [0|4.29497e+009] "" CSM,RadioLow
 SG_ LCMDI_WCM_DatAvalLicTag : 39|8@0+ (1,0) [0|255] "" CSM,RadioLow
 SG_ LCMDI_WCM_DatAvalOwnID : 47|16@0+ (1,0) [0|65535] "" CSM,RadioLow
 SG_ LCMDI_WCM_DatAvalTotBlks : 63|7@0+ (1,0) [0|127] "" CSM,RadioLow

BO_ 446 WCM_NM_PDU_On_CAN_5_Cluster: 8 WCM
 SG_ ISignal_WCM_CAN_5_Cluster : 23|48@0+ (1,0) [0|281474976710655] "" AGC,AMP,CGM,CSM,HUD_CAN,HVAC_FP_F,HVAC_FP_R,ICS_Info,IPC,PDR,MFC,RSC,RadioLow,TCP,VKM

BA_DEF_ SG_  "SignalType" STRING ;
BA_DEF_ SG_  "SignalLongName" STRING ;
BA_DEF_ BO_  "GenMsgCycleTime" INT 0 10000;
BA_DEF_ BO_  "GenMsgSendType" ENUM "cyclicX","spontanX","cyclicIfActiveX","spontanWithDelay","cyclicAndSpontanX","cyclicAndSpontanWithDelay","spontanWithRepetition","cyclicIfActiveAndSpontanWD";
BA_DEF_DEF_  "SignalType" "";
BA_DEF_DEF_  "SignalLongName" "";
BA_DEF_DEF_  "GenMsgCycleTime" 0;
BA_DEF_DEF_  "GenMsgSendType" "cyclicX";
BA_ "GenMsgCycleTime" BO_ 1333 1000;
BA_ "GenMsgCycleTime" BO_ 1338 1000;
BA_ "GenMsgCycleTime" BO_ 1274 1000;
BA_ "GenMsgCycleTime" BO_ 1285 1000;
BA_ "GenMsgCycleTime" BO_ 1309 1000;
BA_ "GenMsgCycleTime" BO_ 1033 1000;
BA_ "GenMsgCycleTime" BO_ 1377 1000;
BA_ "GenMsgCycleTime" BO_ 1378 1000;
BA_ "GenMsgCycleTime" BO_ 1441 1000;
BA_ "GenMsgCycleTime" BO_ 1324 1000;
BA_ "GenMsgCycleTime" BO_ 1325 1000;
BA_ "GenMsgCycleTime" BO_ 551 250;
BA_ "GenMsgCycleTime" BO_ 1092 3500;
BA_ "GenMsgCycleTime" BO_ 1090 1000;
BA_ "GenMsgCycleTime" BO_ 1067 250;
BA_ "GenMsgCycleTime" BO_ 681 100;
BA_ "GenMsgCycleTime" BO_ 682 100;
BA_ "GenMsgCycleTime" BO_ 683 100;
BA_ "GenMsgCycleTime" BO_ 680 100;
BA_ "GenMsgCycleTime" BO_ 684 100;
BA_ "GenMsgCycleTime" BO_ 1327 1000;
BA_ "GenMsgCycleTime" BO_ 516 250;
BA_ "GenMsgCycleTime" BO_ 1462 1000;
BA_ "GenMsgCycleTime" BO_ 35 10;
BA_ "GenMsgCycleTime" BO_ 1357 100;
BA_ "GenMsgCycleTime" BO_ 522 1000;
BA_ "GenMsgCycleTime" BO_ 644 250;
BA_ "GenMsgCycleTime" BO_ 621 100;
BA_ "GenMsgCycleTime" BO_ 1334 1000;
BA_ "GenMsgCycleTime" BO_ 1336 1000;
BA_ "GenMsgCycleTime" BO_ 1339 1000;
BA_ "GenMsgCycleTime" BO_ 1340 1000;
BA_ "GenMsgCycleTime" BO_ 1402 1000;
BA_ "GenMsgCycleTime" BO_ 1403 500;
BA_ "GenMsgCycleTime" BO_ 1101 1000;
BA_ "GenMsgCycleTime" BO_ 1382 1000;
BA_ "GenMsgCycleTime" BO_ 1102 1000;
BA_ "GenMsgCycleTime" BO_ 1267 1000;
BA_ "GenMsgCycleTime" BO_ 1252 1000;
BA_ "GenMsgCycleTime" BO_ 1194 1000;
BA_ "GenMsgCycleTime" BO_ 1229 1000;
BA_ "GenMsgCycleTime" BO_ 1046 100;
BA_ "GenMsgCycleTime" BO_ 30 12.5;
BA_ "GenMsgCycleTime" BO_ 1111 1000;
BA_ "GenMsgCycleTime" BO_ 1112 1000;
BA_ "GenMsgCycleTime" BO_ 1113 1000;
BA_ "GenMsgCycleTime" BO_ 1114 1000;
BA_ "GenMsgCycleTime" BO_ 1797 3500;
BA_ "GenMsgCycleTime" BO_ 1035 1000;
BA_ "GenMsgCycleTime" BO_ 1798 3500;
BA_ "GenMsgCycleTime" BO_ 1036 1000;
BA_ "GenMsgCycleTime" BO_ 1815 3500;
BA_ "GenMsgCycleTime" BO_ 1079 1000;
BA_ "GenMsgCycleTime" BO_ 553 100;
BA_ "GenMsgCycleTime" BO_ 554 250;
BA_ "GenMsgCycleTime" BO_ 1042 3500;
BA_ "GenMsgCycleTime" BO_ 1037 1000;
BA_ "GenMsgCycleTime" BO_ 1822 3500;
BA_ "GenMsgCycleTime" BO_ 1260 1000;
BA_ "GenMsgCycleTime" BO_ 1823 3500;
BA_ "GenMsgCycleTime" BO_ 1288 1000;
BA_ "GenMsgCycleTime" BO_ 1103 1000;
BA_ "GenMsgCycleTime" BO_ 1343 1000;
BA_ "GenMsgCycleTime" BO_ 1344 1000;
BA_ "GenMsgCycleTime" BO_ 1345 1000;
BA_ "SignalLongName" SG_ 1333 UTCYr "UTC Year";
BA_ "SignalType" SG_ 1333 UTCYr_Inv "ENM";
BA_ "SignalLongName" SG_ 1333 UTCYr_Inv "UTC Year Invalid";
BA_ "SignalLongName" SG_ 1333 UTCMin "UTC Minutes";
BA_ "SignalType" SG_ 1333 UTCMin_Inv "ENM";
BA_ "SignalLongName" SG_ 1333 UTCMin_Inv "UTC Minutes Invalid";
BA_ "SignalType" SG_ 1333 UTCDay_Inv "ENM";
BA_ "SignalLongName" SG_ 1333 UTCDay_Inv "UTC Day Invalid";
BA_ "SignalLongName" SG_ 1333 UTCSec "UTC Seconds";
BA_ "SignalType" SG_ 1333 UTCSec_Inv "ENM";
BA_ "SignalLongName" SG_ 1333 UTCSec_Inv "UTC Seconds Invalid";
BA_ "SignalLongName" SG_ 1333 UTCHrs "UTC Hours";
BA_ "SignalType" SG_ 1333 UTCHrs_Inv "ENM";
BA_ "SignalLongName" SG_ 1333 UTCHrs_Inv "UTC Hours Invalid";
BA_ "SignalLongName" SG_ 1333 UTCDay "UTC Day";
BA_ "SignalType" SG_ 1333 UTCMth "ENM";
BA_ "SignalLongName" SG_ 1333 UTCMth "UTC Month";
BA_ "SignalType" SG_ 1333 UTCMth_Inv "ENM";
BA_ "SignalLongName" SG_ 1333 UTCMth_Inv "UTC Month Invalid";
BA_ "SignalType" SG_ 1333 CellNWDateTimeAvl "ENM";
BA_ "SignalLongName" SG_ 1333 CellNWDateTimeAvl "Cellular Network Date and Time Available";
BA_ "SignalLongName" SG_ 1338 CmpsCrHding "Compass Corrected Heading";
BA_ "SignalType" SG_ 1338 CmpsOctHding "ENM";
BA_ "SignalLongName" SG_ 1338 CmpsOctHding "Compass Octant Heading";
BA_ "SignalType" SG_ 1338 CmpsDecZone "ENM";
BA_ "SignalLongName" SG_ 1338 CmpsDecZone "Compass Declination Zone";
BA_ "SignalType" SG_ 1338 EmrgRespSysServIndOn "ENM";
BA_ "SignalLongName" SG_ 1338 EmrgRespSysServIndOn "Emergency Response System Service Indication On";
BA_ "SignalType" SG_ 1338 CmpsZnNvrSet "ENM";
BA_ "SignalLongName" SG_ 1338 CmpsZnNvrSet "Compass Zone Never Set";
BA_ "SignalType" SG_ 1338 CmpsSatrtd "ENM";
BA_ "SignalLongName" SG_ 1338 CmpsSatrtd "Compass Saturated";
BA_ "SignalType" SG_ 1338 CmpsOctHdingDataSrc "ENM";
BA_ "SignalLongName" SG_ 1338 CmpsOctHdingDataSrc "Compass Octant Heading Data Source";
BA_ "SignalType" SG_ 1338 CmpsModManCalInPrc "ENM";
BA_ "SignalLongName" SG_ 1338 CmpsModManCalInPrc "Compass Module Manual Calibration In Process";
BA_ "SignalType" SG_ 1338 CmpsModFltPrs "ENM";
BA_ "SignalLongName" SG_ 1338 CmpsModFltPrs "Compass Module Fault Present";
BA_ "SignalLongName" SG_ 1274 CldrYr "Calendar Year";
BA_ "SignalLongName" SG_ 1274 SecOfMin "Seconds of Minute";
BA_ "SignalLongName" SG_ 1274 MinOfHr "Minute of Hour";
BA_ "SignalLongName" SG_ 1274 HrOfDay "Hour of Day";
BA_ "SignalType" SG_ 1274 CldrMth "ENM";
BA_ "SignalLongName" SG_ 1274 CldrMth "Calendar Month";
BA_ "SignalType" SG_ 1285 IntDimSelAnmTypSetReq "ENM";
BA_ "SignalLongName" SG_ 1285 IntDimSelAnmTypSetReq "Interior Dimming Selected Animation Type Setting Request";
BA_ "SignalType" SG_ 1285 IntDimSelColTypSetReq "ENM";
BA_ "SignalLongName" SG_ 1285 IntDimSelColTypSetReq "Interior Dimming Selected Color Type Setting Request";
BA_ "SignalType" SG_ 1285 RrZnStUpCstChgSetReq "ENM";
BA_ "SignalLongName" SG_ 1285 RrZnStUpCstChgSetReq "Rear Zone Startup Customization Change Setting Request";
BA_ "SignalType" SG_ 1285 RmtSnrfOpCstChgSetReq "ENM";
BA_ "SignalLongName" SG_ 1285 RmtSnrfOpCstChgSetReq "Remote Sunroof Operation Customization Change Setting Request";
BA_ "SignalType" SG_ 1309 FrtCntrStckHptcFdbkStat "ENM";
BA_ "SignalLongName" SG_ 1309 FrtCntrStckHptcFdbkStat "Front Center Stack Haptic Feedback State";
BA_ "SignalType" SG_ 1309 FrtCntrStckTag2Sw "ENM";
BA_ "SignalLongName" SG_ 1309 FrtCntrStckTag2Sw "Front Center Stack Tag 2 Switch";
BA_ "SignalType" SG_ 1309 FrtCntrStckTag1Sw "ENM";
BA_ "SignalLongName" SG_ 1309 FrtCntrStckTag1Sw "Front Center Stack Tag 1 Switch";
BA_ "SignalType" SG_ 1309 FrtCntrStckPrxmtyStat "ENM";
BA_ "SignalLongName" SG_ 1309 FrtCntrStckPrxmtyStat "Front Center Stack Proximity State";
BA_ "SignalType" SG_ 1309 FrtCntrStckPrxmtyGstr "ENM";
BA_ "SignalLongName" SG_ 1309 FrtCntrStckPrxmtyGstr "Front Center Stack Proximity Gesture";
BA_ "SignalType" SG_ 1309 FrtCntrStckVolUpSw "ENM";
BA_ "SignalLongName" SG_ 1309 FrtCntrStckVolUpSw "Front Center Stack Volume Up Switch";
BA_ "SignalType" SG_ 1309 FrtCntrStckVolDnSw "ENM";
BA_ "SignalLongName" SG_ 1309 FrtCntrStckVolDnSw "Front Center Stack Volume Down Switch";
BA_ "SignalType" SG_ 1309 FrtCntrStckToneSw "ENM";
BA_ "SignalLongName" SG_ 1309 FrtCntrStckToneSw "Front Center Stack Tone Switch";
BA_ "SignalType" SG_ 1309 FrtCntrStckTag5Sw "ENM";
BA_ "SignalLongName" SG_ 1309 FrtCntrStckTag5Sw "Front Center Stack Tag 5 Switch";
BA_ "SignalType" SG_ 1309 FrtCntrStckTag4Sw "ENM";
BA_ "SignalLongName" SG_ 1309 FrtCntrStckTag4Sw "Front Center Stack Tag 4 Switch";
BA_ "SignalType" SG_ 1309 FrtCntrStckTag3Sw "ENM";
BA_ "SignalLongName" SG_ 1309 FrtCntrStckTag3Sw "Front Center Stack Tag 3 Switch";
BA_ "SignalType" SG_ 1033 LnFllwgFtrStat "ENM";
BA_ "SignalLongName" SG_ 1033 LnFllwgFtrStat "Lane Following Feature State";
BA_ "SignalType" SG_ 1377 NodeStsAPA_CAN_2_LcFA "ENM";
BA_ "SignalLongName" SG_ 1377 NodeStsAPA_CAN_2_LcFA "Node Status APA_CAN_2 Loss of Communication Fault Active";
BA_ "SignalType" SG_ 1377 NodeStsAPA_CAN_1_LcFA "ENM";
BA_ "SignalLongName" SG_ 1377 NodeStsAPA_CAN_1_LcFA "Node Status APA_CAN_1 Loss of Communication Fault Active";
BA_ "SignalType" SG_ 1377 NodeStsAOS_LcFA "ENM";
BA_ "SignalLongName" SG_ 1377 NodeStsAOS_LcFA "Node Status AOS Loss of Communication Fault Active";
BA_ "SignalType" SG_ 1377 NodeStsAMP_LcFA "ENM";
BA_ "SignalLongName" SG_ 1377 NodeStsAMP_LcFA "Node Status AMP Loss of Communication Fault Active";
BA_ "SignalType" SG_ 1377 NodeStsALC_LcFA "ENM";
BA_ "SignalLongName" SG_ 1377 NodeStsALC_LcFA "Node Status ALC Loss of Communication Fault Active";
BA_ "SignalType" SG_ 1377 NodeStsAHL_AFL_LcFA "ENM";
BA_ "SignalLongName" SG_ 1377 NodeStsAHL_AFL_LcFA "Node Status AHL_AFL Loss of Communication Fault Active";
BA_ "SignalType" SG_ 1377 NodeStsAGC_LcFA "ENM";
BA_ "SignalLongName" SG_ 1377 NodeStsAGC_LcFA "Node Status AGC Loss of Communication Fault Active";
BA_ "SignalType" SG_ 1377 NodeStsDMS_LcFA "ENM";
BA_ "SignalLongName" SG_ 1377 NodeStsDMS_LcFA "Node Status DMS Loss of Communication Fault Active";
BA_ "SignalType" SG_ 1377 NodeStsDEFC_LcFA "ENM";
BA_ "SignalLongName" SG_ 1377 NodeStsDEFC_LcFA "Node Status DEFC Loss of Communication Fault Active";
BA_ "SignalType" SG_ 1377 NodeStsDCM_LcFA "ENM";
BA_ "SignalLongName" SG_ 1377 NodeStsDCM_LcFA "Node Status DCM Loss of Communication Fault Active";
BA_ "SignalType" SG_ 1377 NodeStsCSM_LcFA "ENM";
BA_ "SignalLongName" SG_ 1377 NodeStsCSM_LcFA "Node Status CSM Loss of Communication Fault Active";
BA_ "SignalType" SG_ 1377 NodeStsBSM_CAN_3_LcFA "ENM";
BA_ "SignalLongName" SG_ 1377 NodeStsBSM_CAN_3_LcFA "Node Status BSM_CAN_3 Loss of Communication Fault Active";
BA_ "SignalType" SG_ 1377 NodeStsBSM_CAN_2_LcFA "ENM";
BA_ "SignalLongName" SG_ 1377 NodeStsBSM_CAN_2_LcFA "Node Status BSM_CAN_2 Loss of Communication Fault Active";
BA_ "SignalType" SG_ 1377 NodeStsBCM_LcFA "ENM";
BA_ "SignalLongName" SG_ 1377 NodeStsBCM_LcFA "Node Status BCM Loss of Communication Fault Active";
BA_ "SignalType" SG_ 1377 NodeStsARB_LcFA "ENM";
BA_ "SignalLongName" SG_ 1377 NodeStsARB_LcFA "Node Status ARB Loss of Communication Fault Active";
BA_ "SignalType" SG_ 1377 NodeStsELM_LcFA "ENM";
BA_ "SignalLongName" SG_ 1377 NodeStsELM_LcFA "Node Status ELM Loss of Communication Fault Active";
BA_ "SignalType" SG_ 1377 NodeStsECP_X1_CAN_3_LcFA "ENM";
BA_ "SignalLongName" SG_ 1377 NodeStsECP_X1_CAN_3_LcFA "Node Status ECP_X1_CAN_3 Loss of Communication Fault Active";
BA_ "SignalType" SG_ 1377 NodeStsECP_X1_CAN_2_LcFA "ENM";
BA_ "SignalLongName" SG_ 1377 NodeStsECP_X1_CAN_2_LcFA "Node Status ECP_X1_CAN_2 Loss of Communication Fault Active";
BA_ "SignalType" SG_ 1377 NodeStsECM_CAN_3_LcFA "ENM";
BA_ "SignalLongName" SG_ 1377 NodeStsECM_CAN_3_LcFA "Node Status ECM_CAN_3 Loss of Communication Fault Active";
BA_ "SignalType" SG_ 1377 NodeStsECM_CAN_2_LcFA "ENM";
BA_ "SignalLongName" SG_ 1377 NodeStsECM_CAN_2_LcFA "Node Status ECM_CAN_2 Loss of Communication Fault Active";
BA_ "SignalType" SG_ 1377 NodeStsEBCM_CAN_2_LcFA "ENM";
BA_ "SignalLongName" SG_ 1377 NodeStsEBCM_CAN_2_LcFA "Node Status EBCM_CAN_2 Loss of Communication Fault Active";
BA_ "SignalType" SG_ 1377 NodeStsEBCM_CAN_1_LcFA "ENM";
BA_ "SignalLongName" SG_ 1377 NodeStsEBCM_CAN_1_LcFA "Node Status EBCM_CAN_1 Loss of Communication Fault Active";
BA_ "SignalType" SG_ 1377 NodeStsEPS_LcFA "ENM";
BA_ "SignalLongName" SG_ 1377 NodeStsEPS_LcFA "Node Status EPS Loss of Communication Fault Active";
BA_ "SignalType" SG_ 1377 NodeStsEOCM_HCP2_LcFA "ENM";
BA_ "SignalLongName" SG_ 1377 NodeStsEOCM_HCP2_LcFA "Node Status EOCM_HCP2 Loss of Communication Fault Active";
BA_ "SignalType" SG_ 1377 NodeStsEOCM_HCP1_CAN_8_LcFA "ENM";
BA_ "SignalLongName" SG_ 1377 NodeStsEOCM_HCP1_CAN_8_LcFA "Node Status EOCM_HCP1_CAN_8 Loss of Communication Fault Active";
BA_ "SignalType" SG_ 1377 NodeStsEOCM_HCP1_CAN_2_LcFA "ENM";
BA_ "SignalLongName" SG_ 1377 NodeStsEOCM_HCP1_CAN_2_LcFA "Node Status EOCM_HCP1_CAN_2 Loss of Communication Fault Active";
BA_ "SignalType" SG_ 1377 NodeStsEOCM_HCP1_CAN_1_LcFA "ENM";
BA_ "SignalLongName" SG_ 1377 NodeStsEOCM_HCP1_CAN_1_LcFA "Node Status EOCM_HCP1_CAN_1 Loss of Communication Fault Active";
BA_ "SignalType" SG_ 1377 NodeStsEOCM_CAN_8_LcFA "ENM";
BA_ "SignalLongName" SG_ 1377 NodeStsEOCM_CAN_8_LcFA "Node Status EOCM_CAN_8 Loss of Communication Fault Active";
BA_ "SignalType" SG_ 1377 NodeStsEOCM_CAN_2_LcFA "ENM";
BA_ "SignalLongName" SG_ 1377 NodeStsEOCM_CAN_2_LcFA "Node Status EOCM_CAN_2 Loss of Communication Fault Active";
BA_ "SignalType" SG_ 1377 NodeStsEOCM_CAN_1_LcFA "ENM";
BA_ "SignalLongName" SG_ 1377 NodeStsEOCM_CAN_1_LcFA "Node Status EOCM_CAN_1 Loss of Communication Fault Active";
BA_ "SignalType" SG_ 1377 NodeStsIPC_LcFA "ENM";
BA_ "SignalLongName" SG_ 1377 NodeStsIPC_LcFA "Node Status IPC Loss of Communication Fault Active";
BA_ "SignalType" SG_ 1377 NodeStsICS_Info_LcFA "ENM";
BA_ "SignalLongName" SG_ 1377 NodeStsICS_Info_LcFA "Node Status ICS_Info Loss of Communication Fault Active";
BA_ "SignalType" SG_ 1377 NodeStsICCM_LcFA "ENM";
BA_ "SignalLongName" SG_ 1377 NodeStsICCM_LcFA "Node Status ICCM Loss of Communication Fault Active";
BA_ "SignalType" SG_ 1377 NodeStsHVAC_FP_R_LcFA "ENM";
BA_ "SignalLongName" SG_ 1377 NodeStsHVAC_FP_R_LcFA "Node Status HVAC_FP_R Loss of Communication Fault Active";
BA_ "SignalType" SG_ 1377 NodeStsHVAC_FP_F_LcFA "ENM";
BA_ "SignalLongName" SG_ 1377 NodeStsHVAC_FP_F_LcFA "Node Status HVAC_FP_F Loss of Communication Fault Active";
BA_ "SignalType" SG_ 1377 NodeStsHUD_CAN_LcFA "ENM";
BA_ "SignalLongName" SG_ 1377 NodeStsHUD_CAN_LcFA "Node Status HUD_CAN Loss of Communication Fault Active";
BA_ "SignalType" SG_ 1377 NodeStsFCM_LcFA "ENM";
BA_ "SignalLongName" SG_ 1377 NodeStsFCM_LcFA "Node Status FCM Loss of Communication Fault Active";
BA_ "SignalType" SG_ 1377 NodeStsFCM_LC_LcFA "ENM";
BA_ "SignalLongName" SG_ 1377 NodeStsFCM_LC_LcFA "Node Status FCM LC Loss of Communication Fault Active";
BA_ "SignalType" SG_ 1377 NodeStsMSM_D_LcFA "ENM";
BA_ "SignalLongName" SG_ 1377 NodeStsMSM_D_LcFA "Node Status MSM_D Loss of Communication Fault Active";
BA_ "SignalType" SG_ 1377 NodeStsMSB2_LcFA "ENM";
BA_ "SignalLongName" SG_ 1377 NodeStsMSB2_LcFA "Node Status MSB2 Loss of Communication Fault Active";
BA_ "SignalType" SG_ 1377 NodeStsMSB1_LcFA "ENM";
BA_ "SignalLongName" SG_ 1377 NodeStsMSB1_LcFA "Node Status MSB1 Loss of Communication Fault Active";
BA_ "SignalType" SG_ 1377 NodeStsMRCM_R_LcFA "ENM";
BA_ "SignalLongName" SG_ 1377 NodeStsMRCM_R_LcFA "Node Status MRCM_R Loss of Communication Fault Active";
BA_ "SignalType" SG_ 1377 NodeStsMRCM_L_LcFA "ENM";
BA_ "SignalLongName" SG_ 1377 NodeStsMRCM_L_LcFA "Node Status MRCM_L Loss of Communication Fault Active";
BA_ "SignalType" SG_ 1377 NodeStsMFC_LcFA "ENM";
BA_ "SignalLongName" SG_ 1377 NodeStsMFC_LcFA "Node Status MFC Loss of Communication Fault Active";
BA_ "SignalType" SG_ 1377 NodeStsLRR_LcFA "ENM";
BA_ "SignalLongName" SG_ 1377 NodeStsLRR_LcFA "Node Status LRR Loss of Communication Fault Active";
BA_ "SignalType" SG_ 1377 NodeStsLRR_HC_LcFA "ENM";
BA_ "SignalLongName" SG_ 1377 NodeStsLRR_HC_LcFA "Node StatusLRR_HC Loss of Communication Fault Active";
BA_ "SignalType" SG_ 1377 NodeStsPDR_LcFA "ENM";
BA_ "SignalLongName" SG_ 1377 NodeStsPDR_LcFA "Node Status PDR Loss of Communication Fault Active";
BA_ "SignalType" SG_ 1377 NodeStsPA_LcFA "ENM";
BA_ "SignalLongName" SG_ 1377 NodeStsPA_LcFA "Node Status PA Loss of Communication Fault Active";
BA_ "SignalType" SG_ 1377 NodeStsNVM_LcFA "ENM";
BA_ "SignalLongName" SG_ 1377 NodeStsNVM_LcFA "Node Status NVM Loss of Communication Fault Active";
BA_ "SignalType" SG_ 1377 NodeStsMTCM_R_LcFA "ENM";
BA_ "SignalLongName" SG_ 1377 NodeStsMTCM_R_LcFA "Node Status MTCM_R Loss of Communication Fault Active";
BA_ "SignalType" SG_ 1377 NodeStsMTCM_L_LcFA "ENM";
BA_ "SignalLongName" SG_ 1377 NodeStsMTCM_L_LcFA "Node Status MTCM_L Loss of Communication Fault Active";
BA_ "SignalType" SG_ 1377 NodeStsMSM_RR_LcFA "ENM";
BA_ "SignalLongName" SG_ 1377 NodeStsMSM_RR_LcFA "Node Status MSM_RR Loss of Communication Fault Active";
BA_ "SignalType" SG_ 1377 NodeStsMSM_P_LcFA "ENM";
BA_ "SignalLongName" SG_ 1377 NodeStsMSM_P_LcFA "Node Status MSM_P Loss of Communication Fault Active";
BA_ "SignalType" SG_ 1377 NodeStsMSM_LR_LcFA "ENM";
BA_ "SignalLongName" SG_ 1377 NodeStsMSM_LR_LcFA "Node Status MSM_LR Loss of Communication Fault Active";
BA_ "SignalType" SG_ 1377 NodeStsSBZA_R_LcFA "ENM";
BA_ "SignalLongName" SG_ 1377 NodeStsSBZA_R_LcFA "Node Status SBZA_R Loss of Communication Fault Active";
BA_ "SignalType" SG_ 1377 NodeStsSBZA_L_LcFA "ENM";
BA_ "SignalLongName" SG_ 1377 NodeStsSBZA_L_LcFA "Node Status SBZA_L Loss of Communication Fault Active";
BA_ "SignalType" SG_ 1377 NodeStsSADS_LcFA "ENM";
BA_ "SignalLongName" SG_ 1377 NodeStsSADS_LcFA "Node Status SADS Loss of Communication Fault Active";
BA_ "SignalType" SG_ 1377 NodeStsAHS_LcFA "ENM";
BA_ "SignalLongName" SG_ 1377 NodeStsAHS_LcFA "Node Status AHS Loss of Communication Fault Active";
BA_ "SignalType" SG_ 1377 NodeStsRSC_LcFA "ENM";
BA_ "SignalLongName" SG_ 1377 NodeStsRSC_LcFA "Node Status RSC Loss of Communication Fault Active";
BA_ "SignalType" SG_ 1377 NodeStsRDCM_LcFA "ENM";
BA_ "SignalLongName" SG_ 1377 NodeStsRDCM_LcFA "Node Status RDCM Loss of Communication Fault Active";
BA_ "SignalType" SG_ 1377 NodeStsRadioLow_LcFA "ENM";
BA_ "SignalLongName" SG_ 1377 NodeStsRadioLow_LcFA "Node Status RadioLow Loss of Communication Fault Active";
BA_ "SignalType" SG_ 1377 NodeStsPTM_LcFA "ENM";
BA_ "SignalLongName" SG_ 1377 NodeStsPTM_LcFA "Node Status PTM Loss of Communication Fault Active";
BA_ "SignalType" SG_ 1378 NodeStsSRR_SLR_LcFA "ENM";
BA_ "SignalLongName" SG_ 1378 NodeStsSRR_SLR_LcFA "Node Status SRR_SLR Loss of Communication Fault Active";
BA_ "SignalType" SG_ 1378 NodeStsSRR_RR_LcFA "ENM";
BA_ "SignalLongName" SG_ 1378 NodeStsSRR_RR_LcFA "Node Status SRR_RR Loss of Communication Fault Active";
BA_ "SignalType" SG_ 1378 NodeStsSRR_RF_LcFA "ENM";
BA_ "SignalLongName" SG_ 1378 NodeStsSRR_RF_LcFA "Node Status SRR_RF Loss of Communication Fault Active";
BA_ "SignalType" SG_ 1378 NodeStsSRR_LR_CR_LcFA "ENM";
BA_ "SignalLongName" SG_ 1378 NodeStsSRR_LR_CR_LcFA "Node Status SRR_LR_CR Loss of Communication Fault Active";
BA_ "SignalType" SG_ 1378 NodeStsSRR_LF_LcFA "ENM";
BA_ "SignalLongName" SG_ 1378 NodeStsSRR_LF_LcFA "Node Status SRR_LF Loss of Communication Fault Active";
BA_ "SignalType" SG_ 1378 NodeStsSIB_LcFA "ENM";
BA_ "SignalLongName" SG_ 1378 NodeStsSIB_LcFA "Node Status SIB Loss of Communication Fault Active";
BA_ "SignalType" SG_ 1378 NodeStsSDM_LcFA "ENM";
BA_ "SignalLongName" SG_ 1378 NodeStsSDM_LcFA "Node Status SDM Loss of Communication Fault Active";
BA_ "SignalType" SG_ 1378 NodeStsSCL_LcFA "ENM";
BA_ "SignalLongName" SG_ 1378 NodeStsSCL_LcFA "Node Status SCL Loss of Communication Fault Active";
BA_ "SignalType" SG_ 1378 NodeStsTIM_LcFA "ENM";
BA_ "SignalLongName" SG_ 1378 NodeStsTIM_LcFA "Node Status TIM Loss of Communication Fault Active";
BA_ "SignalType" SG_ 1378 NodeStsTCP_LcFA "ENM";
BA_ "SignalLongName" SG_ 1378 NodeStsTCP_LcFA "Node Status TCP Loss of Communication Fault Active";
BA_ "SignalType" SG_ 1378 NodeStsTCM_LcFA "ENM";
BA_ "SignalLongName" SG_ 1378 NodeStsTCM_LcFA "Node Status TCM Loss of Communication Fault Active";
BA_ "SignalType" SG_ 1378 NodeStsTCCM3_LcFA "ENM";
BA_ "SignalLongName" SG_ 1378 NodeStsTCCM3_LcFA "Node Status TCCM3 Loss of Communication Fault Active";
BA_ "SignalType" SG_ 1378 NodeStsTCCM_LcFA "ENM";
BA_ "SignalLongName" SG_ 1378 NodeStsTCCM_LcFA "Node Status TCCM Loss of Communication Fault Active";
BA_ "SignalType" SG_ 1378 NodeStsSTC_LcFA "ENM";
BA_ "SignalLongName" SG_ 1378 NodeStsSTC_LcFA "Node Status STC Loss of Communication Fault Active";
BA_ "SignalType" SG_ 1378 NodeStsSRR_SRR_LcFA "ENM";
BA_ "SignalLongName" SG_ 1378 NodeStsSRR_SRR_LcFA "Node Status SRR_SRR Loss of Communication Fault Active";
BA_ "SignalType" SG_ 1378 NodeStsECP_E_CAN_9_LcFA "ENM";
BA_ "SignalLongName" SG_ 1378 NodeStsECP_E_CAN_9_LcFA "Node Status ECP_E CAN 9 Loss of Communication Fault Active";
BA_ "SignalType" SG_ 1378 NodeStsCMMb_CAN_2_LcFA "ENM";
BA_ "SignalLongName" SG_ 1378 NodeStsCMMb_CAN_2_LcFA "Node Status CMMb CAN 2 Loss of Communication Fault Active";
BA_ "SignalType" SG_ 1378 NodeStsCMMa_CAN_2_LcFA "ENM";
BA_ "SignalLongName" SG_ 1378 NodeStsCMMa_CAN_2_LcFA "Node Status CMMa CAN 2 Loss of Communication Fault Active";
BA_ "SignalType" SG_ 1378 NodeStsARS_LcFA "ENM";
BA_ "SignalLongName" SG_ 1378 NodeStsARS_LcFA "Node Status ARS Loss of Communication Fault Active";
BA_ "SignalType" SG_ 1378 NodeStsVLM_LcFA "ENM";
BA_ "SignalLongName" SG_ 1378 NodeStsVLM_LcFA "Node Status VLM Loss of Communication Fault Active";
BA_ "SignalType" SG_ 1378 NodeStsWCM_LcFA "ENM";
BA_ "SignalLongName" SG_ 1378 NodeStsWCM_LcFA "Node Status WCM Loss of Communication Fault Active";
BA_ "SignalType" SG_ 1378 NodeStsVPM_LcFA "ENM";
BA_ "SignalLongName" SG_ 1378 NodeStsVPM_LcFA "Node Status VPM Loss of Communication Fault Active";
BA_ "SignalType" SG_ 1378 NodeStsVKM_LcFA "ENM";
BA_ "SignalLongName" SG_ 1378 NodeStsVKM_LcFA "Node StatusVKM Loss of Communication Fault Active";
BA_ "SignalType" SG_ 1378 NodeStsECP_E_CAN_2_LcFA "ENM";
BA_ "SignalLongName" SG_ 1378 NodeStsECP_E_CAN_2_LcFA "Node Status ECP_E_CAN_2 Loss of Communication Fault Active";
BA_ "SignalType" SG_ 1441 NodeStsECP_MC_LcFA "ENM";
BA_ "SignalLongName" SG_ 1441 NodeStsECP_MC_LcFA "Node Status ECP_MC Loss of Communication Fault Active";
BA_ "SignalType" SG_ 1441 NodeStsCMMb_CAN_9_LcFA "ENM";
BA_ "SignalLongName" SG_ 1441 NodeStsCMMb_CAN_9_LcFA "Node Status CMMb_CAN_9 Loss of Communication Fault Active";
BA_ "SignalType" SG_ 1441 NodeStsCMMa_CAN_9_LcFA "ENM";
BA_ "SignalLongName" SG_ 1441 NodeStsCMMa_CAN_9_LcFA "Node Status CMMa_CAN_9 Loss of Communication Fault Active";
BA_ "SignalType" SG_ 1441 NodeStsBSM_MH_LcFA "ENM";
BA_ "SignalLongName" SG_ 1441 NodeStsBSM_MH_LcFA "Node Status BSM_MH Loss of Communication Fault Active";
BA_ "SignalType" SG_ 1441 NodeStsSBM_CAN_9_LcFA "ENM";
BA_ "SignalLongName" SG_ 1441 NodeStsSBM_CAN_9_LcFA "Node Status SBM_CAN_9 Loss of Communication Fault Active";
BA_ "SignalType" SG_ 1441 NodeStsSBM_CAN_10_LcFA "ENM";
BA_ "SignalLongName" SG_ 1441 NodeStsSBM_CAN_10_LcFA "Node Status SBM CAN 10 Loss of Communication Fault Active";
BA_ "SignalType" SG_ 1441 NodeStsLIB1_LcFA "ENM";
BA_ "SignalLongName" SG_ 1441 NodeStsLIB1_LcFA "Node Status LIB1 Loss of Communication Fault Active";
BA_ "SignalType" SG_ 1441 NodeStsHDLM_LcFA "ENM";
BA_ "SignalLongName" SG_ 1441 NodeStsHDLM_LcFA "Node Status HDLM Loss of Communication Fault Active";
BA_ "SignalType" SG_ 1324 LVMAVR_StreoAudReq "ENM";
BA_ "SignalLongName" SG_ 1324 LVMAVR_StreoAudReq "Low Volume Module Audio Video Request : Stereo Audio Request";
BA_ "SignalType" SG_ 1324 LVMAVR_SpchRcgnActv "ENM";
BA_ "SignalLongName" SG_ 1324 LVMAVR_SpchRcgnActv "Low Volume Module Audio Video Request : Speech Recognition Active";
BA_ "SignalType" SG_ 1324 LVMAVR_PrmtAudReq "ENM";
BA_ "SignalLongName" SG_ 1324 LVMAVR_PrmtAudReq "Low Volume Module Audio Video Request : Prompt Audio Request";
BA_ "SignalType" SG_ 1324 LVMAVR_DispReq "ENM";
BA_ "SignalLongName" SG_ 1324 LVMAVR_DispReq "Low Volume Module Audio Video Request : Display Request";
BA_ "SignalType" SG_ 1324 IconRcrdReqActv "ENM";
BA_ "SignalLongName" SG_ 1324 IconRcrdReqActv "Icon Record Request Active";
BA_ "SignalType" SG_ 1324 LVMAVR_ApplStat "ENM";
BA_ "SignalLongName" SG_ 1324 LVMAVR_ApplStat "Low Volume Module Audio Video Request : Application State";
BA_ "SignalLongName" SG_ 1325 PDRRI_CrLpTmMins "Performance Data Recorder Realtime Information : Performance Data Recorder Realtime Information Current Lap Time Minutes";
BA_ "SignalLongName" SG_ 1325 PDRRI_LpDiffTm10s "Performance Data Recorder Realtime Information : Performance Data Recorder Realtime Information Lap Differential Time Tenths of a Second";
BA_ "SignalLongName" SG_ 1325 PDRRI_LpDiffTmSecs "Performance Data Recorder Realtime Information : Performance Data Recorder Realtime Information Lap Differential Time Seconds";
BA_ "SignalLongName" SG_ 1325 PDRRI_CrLpTm10sSec "Performance Data Recorder Realtime Information : Performance Data Recorder Realtime Information Current Lap Time Tenths of a Second";
BA_ "SignalLongName" SG_ 1325 PDRRI_CrLpTmSecs "Performance Data Recorder Realtime Information : Performance Data Recorder Realtime Information Current Lap Time Seconds";
BA_ "SignalLongName" SG_ 1325 PDRBLI_BstLpTmSecs "Performance Data Recorder Best Lap Information : Performance Data Recorder Best Lap Information Best Lap Time Seconds";
BA_ "SignalLongName" SG_ 1325 PDRBLI_BstLpTm100s "Performance Data Recorder Best Lap Information : Performance Data Recorder Best Lap Information Best Lap Time Hundredths of a Second";
BA_ "SignalLongName" SG_ 1325 PDRBLI_BstLpTmMins "Performance Data Recorder Best Lap Information : Performance Data Recorder Best Lap Information Best Lap Time Minutes";
BA_ "SignalLongName" SG_ 1325 PDRLLI_LstLpTmSecs "Performance Data Recorder Last Lap Information : Performance Data Recorder Last Lap Information Last Lap Time Seconds";
BA_ "SignalLongName" SG_ 1325 PDRLLI_LstLpTm100s "Performance Data Recorder Last Lap Information : Performance Data Recorder Last Lap Information Last Lap Time Hundredths of a Second";
BA_ "SignalLongName" SG_ 1325 PDRLLI_LstLpTmMins "Performance Data Recorder Last Lap Information : Performance Data Recorder Last Lap Information Last Lap Time Minutes";
BA_ "SignalLongName" SG_ 566 PrplStat_PCSM "Propulsion State Protected Counter Sync Message";
BA_ "SignalLongName" SG_ 551 PSP_MAC "Propulsion State Protected : MAC";
BA_ "SignalLongName" SG_ 551 PSP_FCnt "Propulsion State Protected : Freshness Counter";
BA_ "SignalType" SG_ 551 PSP_VehTheftImbChlgRespStsAuth "ENM";
BA_ "SignalLongName" SG_ 551 PSP_VehTheftImbChlgRespStsAuth "Propulsion State Protected : Vehicle Theft Immobilizer Challenge Response Status Authenticated";
BA_ "SignalType" SG_ 551 PSP_RmtVehStrtEngRnngAuth "ENM";
BA_ "SignalLongName" SG_ 551 PSP_RmtVehStrtEngRnngAuth "Propulsion State Protected : Remote Vehicle Start Engine Running Authenticated";
BA_ "SignalType" SG_ 551 PSP_PwrtrnCrnkAbrtdAuth "ENM";
BA_ "SignalLongName" SG_ 551 PSP_PwrtrnCrnkAbrtdAuth "Propulsion State Protected : Powertrain Crank Aborted Authenticated";
BA_ "SignalType" SG_ 551 PSP_PrplSysStlActvAuth "ENM";
BA_ "SignalLongName" SG_ 551 PSP_PrplSysStlActvAuth "Propulsion State Protected : Propulsion System Stall Active Authenticated";
BA_ "SignalType" SG_ 551 PSP_PrplSysActvAuth "ENM";
BA_ "SignalLongName" SG_ 551 PSP_PrplSysActvAuth "Propulsion State Protected : Propulsion System Active Authenticated";
BA_ "SignalType" SG_ 551 PSP_EngRnngAuth "ENM";
BA_ "SignalLongName" SG_ 551 PSP_EngRnngAuth "Propulsion State Protected : Engine Running Authenticated";
BA_ "SignalType" SG_ 551 PSP_ClchBtmTrvlAchvdAuth_Inv "ENM";
BA_ "SignalLongName" SG_ 551 PSP_ClchBtmTrvlAchvdAuth_Inv "Propulsion State Protected : Clutch Bottom of Travel Achieved Authenticated Invalid";
BA_ "SignalType" SG_ 551 PSP_ClchBtmTrvlAchvdAuth "ENM";
BA_ "SignalLongName" SG_ 551 PSP_ClchBtmTrvlAchvdAuth "Propulsion State Protected : Clutch Bottom of Travel Achieved Authenticated";
BA_ "SignalLongName" SG_ 551 PSP_ARC "Propulsion State Protected : Alive Rolling Count";
BA_ "SignalType" SG_ 551 PSP_PrkNeutSwStatAuth_Inv "ENM";
BA_ "SignalLongName" SG_ 551 PSP_PrkNeutSwStatAuth_Inv "Propulsion State Protected : Park Neutral Switch State Authenticated Invalid";
BA_ "SignalType" SG_ 551 PSP_PrkNeutSwStatAuth "ENM";
BA_ "SignalLongName" SG_ 551 PSP_PrkNeutSwStatAuth "Propulsion State Protected : Park Neutral Switch State Authenticated";
BA_ "SignalLongName" SG_ 1092 PstClsnInfo_PCSM "Post Collision Information Protected Counter Sync Message";
BA_ "SignalLongName" SG_ 1090 PCIP_MAC "Post Collision Information Protected : MAC";
BA_ "SignalLongName" SG_ 1090 PCIP_FCnt "Post Collision Information Protected : Freshness Counter";
BA_ "SignalType" SG_ 1090 PCIP_MemStRclDsblReqdAuth "ENM";
BA_ "SignalLongName" SG_ 1090 PCIP_MemStRclDsblReqdAuth "Post Collision Information Protected : Memory Seat Recall Disable Requested Authenticated";
BA_ "SignalType" SG_ 1090 PCIP_IntrLgtOnReqdAuth "ENM";
BA_ "SignalLongName" SG_ 1090 PCIP_IntrLgtOnReqdAuth "Post Collision Information Protected : Interior Light On Requested Authenticated";
BA_ "SignalType" SG_ 1090 PCIP_HzrdLgtsOnReqdAuth "ENM";
BA_ "SignalLongName" SG_ 1090 PCIP_HzrdLgtsOnReqdAuth "Post Collision Information Protected : Hazard Lights On Requested Authenticated";
BA_ "SignalType" SG_ 1090 PCIP_HybVehHiVltgDsblReqdAuth "ENM";
BA_ "SignalLongName" SG_ 1090 PCIP_HybVehHiVltgDsblReqdAuth "Post Collision Information Protected : High Voltage System Disable Requested Authenticated";
BA_ "SignalType" SG_ 1090 PCIP_HVACBlwDsblReqdAuth "ENM";
BA_ "SignalLongName" SG_ 1090 PCIP_HVACBlwDsblReqdAuth "Post Collision Information Protected : HVAC Blower Disable Requested Authenticated";
BA_ "SignalType" SG_ 1090 PCIP_FuelCutOffReqdAuth "ENM";
BA_ "SignalLongName" SG_ 1090 PCIP_FuelCutOffReqdAuth "Post Collision Information Protected : Fuel Cut Off Requested Authenticated";
BA_ "SignalType" SG_ 1090 PCIP_DrUnlckReqdAuth "ENM";
BA_ "SignalLongName" SG_ 1090 PCIP_DrUnlckReqdAuth "Post Collision Information Protected : Door Unlock Requested Authenticated";
BA_ "SignalType" SG_ 1090 PCIP_BrkActReqdAuth "ENM";
BA_ "SignalLongName" SG_ 1090 PCIP_BrkActReqdAuth "Post Collision Information Protected : Brake Actuation Requested Authenticated";
BA_ "SignalLongName" SG_ 1090 PCIP_NtfnEvntCntAuth "Post Collision Information Protected : Notification Event Counter Authenticated";
BA_ "SignalType" SG_ 1090 PCIP_NftnFrtImpPrtnsrSevAchAuth "ENM";
BA_ "SignalLongName" SG_ 1090 PCIP_NftnFrtImpPrtnsrSevAchAuth "Post Collision Information Protected : Notification Frontal Impact Pretensioner Severity Achieved Authenticated";
BA_ "SignalType" SG_ 1090 PCIP_NtfnRlOvrSevAchvdAuth "ENM";
BA_ "SignalLongName" SG_ 1090 PCIP_NtfnRlOvrSevAchvdAuth "Post Collision Information Protected : Notification Roll Over Severity Achieved Authenticated";
BA_ "SignalType" SG_ 1090 PCIP_NtfnPedtrnPrtctnSevAchAuth "ENM";
BA_ "SignalLongName" SG_ 1090 PCIP_NtfnPedtrnPrtctnSevAchAuth "Post Collision Information Protected : Notification Pedpro Severity Achieved Authenticated";
BA_ "SignalType" SG_ 1090 PCIP_NtfnLtSdSevAchvdAuth "ENM";
BA_ "SignalLongName" SG_ 1090 PCIP_NtfnLtSdSevAchvdAuth "Post Collision Information Protected : Notification Left Side Severity Achieved Authenticated";
BA_ "SignalType" SG_ 1090 PCIP_NtfnFrtImpStg2SevAchvdAuth "ENM";
BA_ "SignalLongName" SG_ 1090 PCIP_NtfnFrtImpStg2SevAchvdAuth "Post Collision Information Protected : Notification Frontal Impact Stage2 Severity Achieved Authenticated";
BA_ "SignalType" SG_ 1090 PCIP_NtfnFrtImpStg1SevAchvdAuth "ENM";
BA_ "SignalLongName" SG_ 1090 PCIP_NtfnFrtImpStg1SevAchvdAuth "Post Collision Information Protected : Notification Frontal Impact Stage1 Severity Achieved Authenticated";
BA_ "SignalType" SG_ 1090 PCIP_NtfnEvntStsAuth "ENM";
BA_ "SignalLongName" SG_ 1090 PCIP_NtfnEvntStsAuth "Post Collision Information Protected : Notification Event Status Authenticated";
BA_ "SignalType" SG_ 1090 PCIP_HVCrshImpSnsSysDsbldAuth "ENM";
BA_ "SignalLongName" SG_ 1090 PCIP_HVCrshImpSnsSysDsbldAuth "Post Collision Information Protected : High Voltage Crash Impact Sensing System Disabled Authenticated";
BA_ "SignalLongName" SG_ 1090 PCIP_ARC "Post Collision Information Protected : Alive Rolling Count";
BA_ "SignalType" SG_ 1090 PCIP_CruzCtlDsblReqdAuth "ENM";
BA_ "SignalLongName" SG_ 1090 PCIP_CruzCtlDsblReqdAuth "Post Collision Information Protected : Cruise Control Disable Requested Authenticated";
BA_ "SignalType" SG_ 1090 PCIP_eCallReqdAuth "ENM";
BA_ "SignalLongName" SG_ 1090 PCIP_eCallReqdAuth "Post Collision Information Protected : eCall Requested Authenticated";
BA_ "SignalType" SG_ 1090 PCIP_NtfnRtSdSevAchvdAuth "ENM";
BA_ "SignalLongName" SG_ 1090 PCIP_NtfnRtSdSevAchvdAuth "Post Collision Information Protected : Notification Right Side Severity Achieved Authenticated";
BA_ "SignalType" SG_ 1090 PCIP_NtfnRrImpSevAchvdAuth "ENM";
BA_ "SignalLongName" SG_ 1090 PCIP_NtfnRrImpSevAchvdAuth "Post Collision Information Protected : Notification Rear Impact Severity Achieved Authenticated";
BA_ "SignalLongName" SG_ 1811 PwrStrgInfo_PCSM "Power Steering Information Protected Counter Sync Message";
BA_ "SignalLongName" SG_ 1067 PSIP_MAC "Power Steering Information Protected : MAC";
BA_ "SignalLongName" SG_ 1067 PSIP_FCnt "Power Steering Information Protected : Freshness Counter";
BA_ "SignalLongName" SG_ 1067 PSIP_ARC "Power Steering Information Protected : Alive Rolling Count";
BA_ "SignalType" SG_ 1067 PSIP_StrgAsstRdcdLvl3IndOnAuth "ENM";
BA_ "SignalLongName" SG_ 1067 PSIP_StrgAsstRdcdLvl3IndOnAuth "Power Steering Information Protected : Steering Assist Reduced Level 3 Indication On Authenticated";
BA_ "SignalType" SG_ 1067 PSIP_StrgAsstRdcdLvl2IndOnAuth "ENM";
BA_ "SignalLongName" SG_ 1067 PSIP_StrgAsstRdcdLvl2IndOnAuth "Power Steering Information Protected : Steering Assist Reduced Level 2 Indication On Authenticated";
BA_ "SignalType" SG_ 1067 PSIP_StrgAsstRdcdIndOnAuth "ENM";
BA_ "SignalLongName" SG_ 1067 PSIP_StrgAsstRdcdIndOnAuth "Power Steering Information Protected : Steering Assist Reduced Indication On Authenticated";
BA_ "SignalType" SG_ 1067 PSIP_PwrStrgIndOnAuth "ENM";
BA_ "SignalLongName" SG_ 1067 PSIP_PwrStrgIndOnAuth "Power Steering Information Protected : Power Steering Indication On Authenticated";
BA_ "SignalLongName" SG_ 1830 RPPSD_BrstGrp1_PCSM "Redundant Precise Positioning System Data Burst Group Protected Counter Sync Message";
BA_ "SignalLongName" SG_ 681 RPPSDBG2P_CldrYrAuth "Redundant Precise Positioning System Data Burst Group 2 Protected : Calendar Year Authenticated";
BA_ "SignalLongName" SG_ 681 RPPSDBG2P_BrstID "Redundant Precise Positioning System Data Burst Group 2 Protected : Burst ID";
BA_ "SignalLongName" SG_ 681 RPPSDBG2P_ElvtnAuth "Redundant Precise Positioning System Data Burst Group 2 Protected : Elevation Authenticated";
BA_ "SignalType" SG_ 681 RPPSDBG2P_CldrYrAuth_Inv "ENM";
BA_ "SignalLongName" SG_ 681 RPPSDBG2P_CldrYrAuth_Inv "Redundant Precise Positioning System Data Burst Group 2 Protected : Calendar Year Authenticated Invalid";
BA_ "SignalType" SG_ 681 RPPSDBG2P_ElvtnAuth_Inv "ENM";
BA_ "SignalLongName" SG_ 681 RPPSDBG2P_ElvtnAuth_Inv "Redundant Precise Positioning System Data Burst Group 2 Protected : Elevation Authenticated Invalid";
BA_ "SignalLongName" SG_ 681 RPPSDBG2P_LngAuth "Redundant Precise Positioning System Data Burst Group 2 Protected : Longitude Authenticated";
BA_ "SignalType" SG_ 681 RPPSDBG2P_LngAuth_Inv "ENM";
BA_ "SignalLongName" SG_ 681 RPPSDBG2P_LngAuth_Inv "Redundant Precise Positioning System Data Burst Group 2 Protected : Longitude Authenticated Invalid";
BA_ "SignalLongName" SG_ 682 RPPSDBG3P_LatAuth "Redundant Precise Positioning System Data Burst Group 3 Protected : Latitude Authenticated";
BA_ "SignalLongName" SG_ 682 RPPSDBG3P_BrstID "Redundant Precise Positioning System Data Burst Group 3 Protected : Burst ID";
BA_ "SignalLongName" SG_ 682 RPPSDBG3P_TmOfDyAuth "Redundant Precise Positioning System Data Burst Group 3 Protected : Time of Day Authenticated";
BA_ "SignalType" SG_ 682 RPPSDBG3P_LocUsblAuth_Inv "ENM";
BA_ "SignalLongName" SG_ 682 RPPSDBG3P_LocUsblAuth_Inv "Redundant Precise Positioning System Data Burst Group 3 Protected : Location Usable Authenticated Invalid";
BA_ "SignalType" SG_ 682 RPPSDBG3P_LocUsblAuth "ENM";
BA_ "SignalLongName" SG_ 682 RPPSDBG3P_LocUsblAuth "Redundant Precise Positioning System Data Burst Group 3 Protected : Location Usable Authenticated";
BA_ "SignalType" SG_ 682 RPPSDBG3P_LatAuth_Inv "ENM";
BA_ "SignalLongName" SG_ 682 RPPSDBG3P_LatAuth_Inv "Redundant Precise Positioning System Data Burst Group 3 Protected : Latitude Authenticated Invalid";
BA_ "SignalType" SG_ 682 RPPSDBG3P_TmOfDyAuth_Inv "ENM";
BA_ "SignalLongName" SG_ 682 RPPSDBG3P_TmOfDyAuth_Inv "Redundant Precise Positioning System Data Burst Group 3 Protected : Time of Day Authenticated Invalid";
BA_ "SignalLongName" SG_ 683 RPPSDBG4P_2DAbsPsErrEstAuth "Redundant Precise Positioning System Data Burst Group 4 Protected : 2D Absolute Position Error Estimate Authenticated";
BA_ "SignalLongName" SG_ 683 RPPSDBG4P_BrstID "Redundant Precise Positioning System Data Burst Group 4 Protected : Burst ID";
BA_ "SignalLongName" SG_ 683 RPPSDBG4P_AbsHdgErrEstAuth "Redundant Precise Positioning System Data Burst Group 4 Protected : Absolute Heading Error Estimate Authenticated";
BA_ "SignalType" SG_ 683 RPPSDBG4P_2DAbsPsErrEstAuth_Inv "ENM";
BA_ "SignalLongName" SG_ 683 RPPSDBG4P_2DAbsPsErrEstAuth_Inv "Redundant Precise Positioning System Data Burst Group 4 Protected : 2D Absolute Position Error Estimate Authenticated Invalid";
BA_ "SignalLongName" SG_ 683 RPPSDBG4P_CldrDyAuth "Redundant Precise Positioning System Data Burst Group 4 Protected : Calendar Day Authenticated";
BA_ "SignalType" SG_ 683 RPPSDBG4P_AbsHdgErrEstAuth_Inv "ENM";
BA_ "SignalLongName" SG_ 683 RPPSDBG4P_AbsHdgErrEstAuth_Inv "Redundant Precise Positioning System Data Burst Group 4 Protected : Absolute Heading Error Estimate Authenticated Invalid";
BA_ "SignalLongName" SG_ 683 RPPSDBG4P_SigAcqTmAuth "Redundant Precise Positioning System Data Burst Group 4 Protected : Signal Acquisition Time Authenticated";
BA_ "SignalType" SG_ 683 RPPSDBG4P_CldrDyAuth_Inv "ENM";
BA_ "SignalLongName" SG_ 683 RPPSDBG4P_CldrDyAuth_Inv "Redundant Precise Positioning System Data Burst Group 4 Protected : Calendar Day Authenticated Invalid";
BA_ "SignalType" SG_ 683 RPPSDBG4P_SigAcqTmAuth_Inv "ENM";
BA_ "SignalLongName" SG_ 683 RPPSDBG4P_SigAcqTmAuth_Inv "Redundant Precise Positioning System Data Burst Group 4 Protected : Signal AcquisitionTime Authenticated Invalid";
BA_ "SignalLongName" SG_ 680 RPPSDBG1P_MAC "Redundant Precise Positioning System Data Burst Group 1 Protected : MAC";
BA_ "SignalLongName" SG_ 680 RPPSDBG1P_FCnt "Redundant Precise Positioning System Data Burst Group 1 Protected : Freshness Counter";
BA_ "SignalLongName" SG_ 680 RPPSDBG1P_HdgAuth "Redundant Precise Positioning System Data Burst Group 1 Protected : Heading Authenticated";
BA_ "SignalLongName" SG_ 680 RPPSDBG1P_BrstID "Redundant Precise Positioning System Data Burst Group 1 Protected : Burst ID";
BA_ "SignalLongName" SG_ 680 RPPSDBG1P_ARC "Redundant Precise Positioning System Data Burst Group 1 Protected : Alive Rolling Count";
BA_ "SignalType" SG_ 680 RPPSDBG1P_HdgAuth_Inv "ENM";
BA_ "SignalLongName" SG_ 680 RPPSDBG1P_HdgAuth_Inv "Redundant Precise Positioning System Data Burst Group 1 Protected : Heading Authenticated Invalid";
BA_ "SignalLongName" SG_ 684 RPPSDBG5P_LwrGblTmStmAuth "Redundant Precise Positioning System Data Burst Group 5 Protected : Lower Global Time Stamp Authenticated";
BA_ "SignalType" SG_ 684 RPPSDBG5P_GPSModeAuth_Inv "ENM";
BA_ "SignalLongName" SG_ 684 RPPSDBG5P_GPSModeAuth_Inv "Redundant Precise Positioning System Data Burst Group 5 Protected : Global Positioning System Mode Authenticated Invalid";
BA_ "SignalType" SG_ 684 RPPSDBG5P_GPSModeAuth "ENM";
BA_ "SignalLongName" SG_ 684 RPPSDBG5P_GPSModeAuth "Redundant Precise Positioning System Data Burst Group 5 Protected : Global Positioning System Mode Authenticated";
BA_ "SignalLongName" SG_ 684 RPPSDBG5P_BrstID "Redundant Precise Positioning System Data Burst Group 5 Protected : Burst ID";
BA_ "SignalType" SG_ 684 RPPSDBG5P_LwrGblTmStmAuth_Inv "ENM";
BA_ "SignalLongName" SG_ 684 RPPSDBG5P_LwrGblTmStmAuth_Inv "Redundant Precise Positioning System Data Burst Group 5 Protected : Lower Global Time Stamp Authenticated Invalid";
BA_ "SignalType" SG_ 1327 RrSeatCtrlrPrsnt "ENM";
BA_ "SignalLongName" SG_ 1327 RrSeatCtrlrPrsnt "Rear Seat Controller Present";
BA_ "SignalType" SG_ 1327 RrSeatCtrlrBttns "ENM";
BA_ "SignalLongName" SG_ 1327 RrSeatCtrlrBttns "Rear Seat Controller Buttons";
BA_ "SignalLongName" SG_ 520 RelImblz_PCSM "Release Immobilize Protected Counter Sync Message";
BA_ "SignalLongName" SG_ 516 RIP_MAC "Release Immobilize Protected : MAC";
BA_ "SignalLongName" SG_ 516 RIP_FCnt "Release Immobilize Protected : Freshness Counter";
BA_ "SignalLongName" SG_ 516 RIP_RmtVehStrtBkupTmAuth "Release Immobilize Protected : Remote Vehicle Start Backup Time Authenticated";
BA_ "SignalType" SG_ 516 RIP_RmtIgnBlkImbCustClrCmdAuth "ENM";
BA_ "SignalLongName" SG_ 516 RIP_RmtIgnBlkImbCustClrCmdAuth "Release Immobilize Protected : Remote Ignition Block Immobilization Customer Clear Command Authenticated";
BA_ "SignalType" SG_ 516 RIP_PreRelAllwdAuth "ENM";
BA_ "SignalLongName" SG_ 516 RIP_PreRelAllwdAuth "Release Immobilize Protected : Pre-Release Allowed Authenticated";
BA_ "SignalType" SG_ 516 RIP_NewFobXmtrLrndNtfnAuth "ENM";
BA_ "SignalLongName" SG_ 516 RIP_NewFobXmtrLrndNtfnAuth "Release Immobilize Protected : New Fob Transmitter Learned Notification Authenticated";
BA_ "SignalType" SG_ 516 RIP_FrtCmptRelEnblReqAuth "ENM";
BA_ "SignalLongName" SG_ 516 RIP_FrtCmptRelEnblReqAuth "Release Immobilize Protected : Front Compartment Release Enable Request Authenticated";
BA_ "SignalType" SG_ 516 RIP_ElecStrgColUnlckAllwdAuth "ENM";
BA_ "SignalLongName" SG_ 516 RIP_ElecStrgColUnlckAllwdAuth "Release Immobilize Protected : Electric Steering Column Unlock Allowed Authenticated";
BA_ "SignalLongName" SG_ 516 RIP_ARC "Release Immobilize Protected : Alive Rolling Count";
BA_ "SignalType" SG_ 516 RIP_StrtStopIgnSwPrssdAuth "ENM";
BA_ "SignalLongName" SG_ 516 RIP_StrtStopIgnSwPrssdAuth "Release Immobilize Protected : Start/Stop Ignition Switch Pressed Authenticated";
BA_ "SignalType" SG_ 1462 RrCrsTrfcBrkgAutoBrkgRelIndOn "ENM";
BA_ "SignalLongName" SG_ 1462 RrCrsTrfcBrkgAutoBrkgRelIndOn "Rear Cross Traffic Braking Autonomous Braking Release Indication On";
BA_ "SignalLongName" SG_ 35 SWIP_MAC "Steering Wheel Information Protected : MAC";
BA_ "SignalLongName" SG_ 35 SWIP_FCnt "Steering Wheel Information Protected : Freshness Counter";
BA_ "SignalLongName" SG_ 35 SWIP_StrgWhlAngAuth "Steering Wheel Information Protected : Steering Wheel Angle Authenticated";
BA_ "SignalType" SG_ 35 SWIP_StrgWhlAngAuth_DuD "ENM";
BA_ "SignalLongName" SG_ 35 SWIP_StrgWhlAngAuth_DuD "Steering Wheel Information Protected : Steering Wheel Angle Authenticated Don't Use Data";
BA_ "SignalLongName" SG_ 35 SWIP_StrgWhlAngGradAuth "Steering Wheel Information Protected : Steering Wheel Angle Gradient Authenticated";
BA_ "SignalType" SG_ 35 SWIP_StrgWhlAngCalStsAuth "ENM";
BA_ "SignalLongName" SG_ 35 SWIP_StrgWhlAngCalStsAuth "Steering Wheel Information Protected : Steering Wheel Angle Calibration Status Authenticated";
BA_ "SignalType" SG_ 35 SWIP_StrgWhlAngAuth_Inv "ENM";
BA_ "SignalLongName" SG_ 35 SWIP_StrgWhlAngAuth_Inv "Steering Wheel Information Protected : Steering Wheel Angle Authenticated Invalid";
BA_ "SignalLongName" SG_ 35 SWIP_ARC "Steering Wheel Information Protected : Alive Rolling Count";
BA_ "SignalType" SG_ 1357 SSVI_PrssClchPrssStrtAgnIO "ENM";
BA_ "SignalLongName" SG_ 1357 SSVI_PrssClchPrssStrtAgnIO "Startup Shutdown Visual Indications : Press Clutch and Press Start Again Indication On";
BA_ "SignalType" SG_ 1357 SSVI_NoRmtDtdIO "ENM";
BA_ "SignalLongName" SG_ 1357 SSVI_NoRmtDtdIO "Startup Shutdown Visual Indications : No Remote Detected Indication On";
BA_ "SignalType" SG_ 1357 SSVI_AutoShtdnDsbldIO "ENM";
BA_ "SignalLongName" SG_ 1357 SSVI_AutoShtdnDsbldIO "Startup Shutdown Visual Indications : Automatic Shutdown Disabled Indication On";
BA_ "SignalType" SG_ 1357 SSVI_ShfToNeutPrssStrtAgnIO "ENM";
BA_ "SignalLongName" SG_ 1357 SSVI_ShfToNeutPrssStrtAgnIO "Startup Shutdown Visual Indications : Shift to Neutral and Press Start Again Indication On";
BA_ "SignalType" SG_ 1357 SSVI_AutoShtdnIO "ENM";
BA_ "SignalLongName" SG_ 1357 SSVI_AutoShtdnIO "Startup Shutdown Visual Indications : Automatic Shutdown Indication On";
BA_ "SignalType" SG_ 1357 SSVI_AppPrkBrkIO "ENM";
BA_ "SignalLongName" SG_ 1357 SSVI_AppPrkBrkIO "Startup Shutdown Visual Indications : Apply Park Brake Indication On";
BA_ "SignalType" SG_ 1357 SSVI_AppBrkPedIO "ENM";
BA_ "SignalLongName" SG_ 1357 SSVI_AppBrkPedIO "Startup Shutdown Visual Indications : Apply Brake Pedal Indication On";
BA_ "SignalType" SG_ 1357 SSVI_PrssStrtAgnIO "ENM";
BA_ "SignalLongName" SG_ 1357 SSVI_PrssStrtAgnIO "Startup Shutdown Visual Indications : Press Start Again Indication On";
BA_ "SignalType" SG_ 1357 SSVI_ShfToPrkIO "ENM";
BA_ "SignalLongName" SG_ 1357 SSVI_ShfToPrkIO "Startup Shutdown Visual Indications : Shift to Park Indication On";
BA_ "SignalType" SG_ 1357 SSVI_AppClchPedIO "ENM";
BA_ "SignalLongName" SG_ 1357 SSVI_AppClchPedIO "Startup Shutdown Visual Indications : Apply Clutch Pedal Indication On";
BA_ "SignalType" SG_ 1357 SSVI_NoRmtDtdPrssBrkToRestrtIO "ENM";
BA_ "SignalLongName" SG_ 1357 SSVI_NoRmtDtdPrssBrkToRestrtIO "Startup Shutdown Visual Indications : No Remote Detected Press Brake to Restart Indicator On";
BA_ "SignalLongName" SG_ 1357 SSVI_AutoShtdnTmr "Startup Shutdown Visual Indications : Automatic Shutdown Timer";
BA_ "SignalType" SG_ 1357 SSVI_PrssBtnAgnToTrnEngOffIO "ENM";
BA_ "SignalLongName" SG_ 1357 SSVI_PrssBtnAgnToTrnEngOffIO "Startup Shutdown Visual Indications : Press Button Again To Turn Engine Off Indicator On";
BA_ "SignalType" SG_ 1357 ShfToNeutRestrtVehIndOn "ENM";
BA_ "SignalLongName" SG_ 1357 ShfToNeutRestrtVehIndOn "Shift To Neutral Restart Vehicle Indication On";
BA_ "SignalType" SG_ 1357 RestrtVehIndOn "ENM";
BA_ "SignalLongName" SG_ 1357 RestrtVehIndOn "Restart Vehicle Indication On";
BA_ "SignalType" SG_ 1357 SSVI_KeyMvmtRqrdIndOn "ENM";
BA_ "SignalLongName" SG_ 1357 SSVI_KeyMvmtRqrdIndOn "Startup Shutdown Visual Indications : Key Movement Required Indication On";
BA_ "SignalType" SG_ 1357 SSVI_PrssClchBrkForStrtIO "ENM";
BA_ "SignalLongName" SG_ 1357 SSVI_PrssClchBrkForStrtIO "Startup Shutdown Visual Indications : PressClutchandBrakeForStartIndicationOn";
BA_ "SignalType" SG_ 1357 SSVI_ClsEngCmptToStrtVehIO "ENM";
BA_ "SignalLongName" SG_ 1357 SSVI_ClsEngCmptToStrtVehIO "Startup Shutdown Visual Indications : Close Engine Compartment To Start Vehicle Indication On";
BA_ "SignalType" SG_ 1357 SSVI_KylsStrtUseXmtrPcktIO "ENM";
BA_ "SignalLongName" SG_ 1357 SSVI_KylsStrtUseXmtrPcktIO "Startup Shutdown Visual Indications : Keyless Start Use Transmitter Pocket Indication On";
BA_ "SignalType" SG_ 1357 SSVI_NoRmtDtdPrssClchToRestrtIO "ENM";
BA_ "SignalLongName" SG_ 1357 SSVI_NoRmtDtdPrssClchToRestrtIO "Startup Shutdown Visual Indications : No Remote Detected Press Clutch to Restart Indicator On";
BA_ "SignalType" SG_ 1357 VehInNeutShfToDrvIndOn "ENM";
BA_ "SignalLongName" SG_ 1357 VehInNeutShfToDrvIndOn "Vehicle In Neutral Shift To Drive Indication On";
BA_ "SignalLongName" SG_ 1357 SSVI_CS "Startup Shutdown Visual Indications : Checksum";
BA_ "SignalLongName" SG_ 1357 SSVI_ARC "Startup Shutdown Visual Indications : Alive Rolling Count";
BA_ "SignalLongName" SG_ 522 SysPwrMode_PCSM "System Power Mode Protected Counter Sync Message";
BA_ "SignalLongName" SG_ 644 SPMP_MAC "System Power Mode Protected : MAC";
BA_ "SignalLongName" SG_ 644 SPMP_FCnt "System Power Mode Protected : Freshness Counter";
BA_ "SignalLongName" SG_ 644 SPMP_ARC "System Power Mode Protected : Alive Rolling Count";
BA_ "SignalType" SG_ 644 SPMP_SysPwrModeAuth_Inv "ENM";
BA_ "SignalLongName" SG_ 644 SPMP_SysPwrModeAuth_Inv "System Power Mode Protected : System Power Mode Authenticated Invalid";
BA_ "SignalType" SG_ 644 SPMP_SysPwrModeAuth "ENM";
BA_ "SignalLongName" SG_ 644 SPMP_SysPwrModeAuth "System Power Mode Protected : System Power Mode Authenticated";
BA_ "SignalType" SG_ 644 SPMP_PriRunCrnkCmdActvAuth_Inv "ENM";
BA_ "SignalLongName" SG_ 644 SPMP_PriRunCrnkCmdActvAuth_Inv "System Power Mode Protected : Primary Run Crank Command Active Authenticated Invalid";
BA_ "SignalType" SG_ 644 SPMP_PriRunCrnkCmdActvAuth "ENM";
BA_ "SignalLongName" SG_ 644 SPMP_PriRunCrnkCmdActvAuth "System Power Mode Protected : Primary Run Crank Command Active Authenticated";
BA_ "SignalLongName" SG_ 644 SPMP_PV "System Power Mode Protected : Protection Value";
BA_ "SignalLongName" SG_ 621 PrcsPsngSysSigAcqTm "Precise Positioning System Signal Acquisition Time";
BA_ "SignalType" SG_ 1334 EmrgRespSysTyp "ENM";
BA_ "SignalLongName" SG_ 1334 EmrgRespSysTyp "Emergency Response System Type";
BA_ "SignalLongName" SG_ 1335 TCP_LCMDataAvlblOwnID "LicenseComplianceMaterialDisplayInterface : TCP_LCMDataAvailableOwnerID";
BA_ "SignalLongName" SG_ 1335 TCP_LCMDataAvlblLicTag "LicenseComplianceMaterialDisplayInterface : TCP_LCMDataAvailableLicenseTag";
BA_ "SignalLongName" SG_ 1335 TCP_LCMDataAvlblChksum "LicenseComplianceMaterialDisplayInterface : TCP_LCMDataAvailableChecksum";
BA_ "SignalLongName" SG_ 1335 TCP_LCMDataAvlblTotBlks "LicenseComplianceMaterialDisplayInterface : TCP_LCMDataAvailableTotalBlocks";
BA_ "SignalLongName" SG_ 1336 ASVSC_VolReq "Audio System Volume Setting Control : Volume Request";
BA_ "SignalType" SG_ 1336 ASVSC_ReqEnbld "ENM";
BA_ "SignalLongName" SG_ 1336 ASVSC_ReqEnbld "Audio System Volume Setting Control : Request Enabled";
BA_ "SignalType" SG_ 1336 TBTTrnChmEvntStat "ENM";
BA_ "SignalLongName" SG_ 1336 TBTTrnChmEvntStat "TBT at Turn ChimeEventState";
BA_ "SignalType" SG_ 1336 AudSeltdSrcReq "ENM";
BA_ "SignalLongName" SG_ 1336 AudSeltdSrcReq "Audio Selected Source Request";
BA_ "SignalLongName" SG_ 1339 TunerFreqChanReq "Tuner Frequency Channel Request";
BA_ "SignalType" SG_ 1339 SuprCruzSbscrptnActv "ENM";
BA_ "SignalLongName" SG_ 1339 SuprCruzSbscrptnActv "Super Cruise Subscription Active";
BA_ "SignalType" SG_ 1339 InfoActivtnReq "ENM";
BA_ "SignalLongName" SG_ 1339 InfoActivtnReq "Infotainment Activation Request";
BA_ "SignalType" SG_ 1339 TnrFreqBndReq "ENM";
BA_ "SignalLongName" SG_ 1339 TnrFreqBndReq "Tuner Frequency Band Request";
BA_ "SignalType" SG_ 1340 TAR_AudSrcStat "ENM";
BA_ "SignalLongName" SG_ 1340 TAR_AudSrcStat "Telematics Audio Request : Audio Source Status";
BA_ "SignalType" SG_ 1340 TAR_AudConctReq "ENM";
BA_ "SignalLongName" SG_ 1340 TAR_AudConctReq "Telematics Audio Request : Audio Connection Request";
BA_ "SignalType" SG_ 1340 RmtRflshUpdAvlbl "ENM";
BA_ "SignalLongName" SG_ 1340 RmtRflshUpdAvlbl "Remote Reflash Update Available";
BA_ "SignalLongName" SG_ 1828 TlmGPSDateSrc_PCSM "Telematics GPS Date Source Protected Counter Sync Message";
BA_ "SignalLongName" SG_ 1402 TGPSDSP_MAC "Telematics GPS Date Source Protected : MAC";
BA_ "SignalLongName" SG_ 1402 TGPSDSP_FCnt "Telematics GPS Date Source Protected : Freshness Counter";
BA_ "SignalLongName" SG_ 1402 TGPSDSP_UTCDyAuth "Telematics GPS Date Source Protected : UTC Day Authenticated";
BA_ "SignalType" SG_ 1402 TGPSDSP_DateSrcAuth_Inv "ENM";
BA_ "SignalLongName" SG_ 1402 TGPSDSP_DateSrcAuth_Inv "Telematics GPS Date Source Protected : Date Source Authenticated Invalid";
BA_ "SignalType" SG_ 1402 TGPSDSP_DateSrcAuth "ENM";
BA_ "SignalLongName" SG_ 1402 TGPSDSP_DateSrcAuth "Telematics GPS Date Source Protected : Date Source Authenticated";
BA_ "SignalLongName" SG_ 1402 TGPSDSP_UTCYrAuth "Telematics GPS Date Source Protected : UTC Year Authenticated";
BA_ "SignalType" SG_ 1402 TGPSDSP_UTCMonthAuth_Inv "ENM";
BA_ "SignalLongName" SG_ 1402 TGPSDSP_UTCMonthAuth_Inv "Telematics GPS Date Source Protected : UTC Month Authenticated Invalid";
BA_ "SignalType" SG_ 1402 TGPSDSP_UTCMonthAuth "ENM";
BA_ "SignalLongName" SG_ 1402 TGPSDSP_UTCMonthAuth "Telematics GPS Date Source Protected : UTC Month Authenticated";
BA_ "SignalType" SG_ 1402 TGPSDSP_UTCDyAuth_Inv "ENM";
BA_ "SignalLongName" SG_ 1402 TGPSDSP_UTCDyAuth_Inv "Telematics GPS Date Source Protected : UTC Day Authenticated Invalid";
BA_ "SignalType" SG_ 1402 TGPSDSP_UTCYrAuth_Inv "ENM";
BA_ "SignalLongName" SG_ 1402 TGPSDSP_UTCYrAuth_Inv "Telematics GPS Date Source Protected : UTC Year Authenticated Invalid";
BA_ "SignalLongName" SG_ 1402 TGPSDSP_ARC "Telematics GPS Date Source Protected : Alive Rolling Count";
BA_ "SignalLongName" SG_ 1829 TlmGPSTmSrc_PCSM "Telematics GPS Time Source Protected Counter Sync Message";
BA_ "SignalLongName" SG_ 1403 TGPSTSP_MAC "Telematics GPS Time Source Protected : MAC";
BA_ "SignalLongName" SG_ 1403 TGPSTSP_FCnt "Telematics GPS Time Source Protected : Freshness Counter";
BA_ "SignalLongName" SG_ 1403 TGPSTSP_UTCHrsAuth "Telematics GPS Time Source Protected : UTC Hours Authenticated";
BA_ "SignalType" SG_ 1403 TGPSTSP_TmSrcAuth_Inv "ENM";
BA_ "SignalLongName" SG_ 1403 TGPSTSP_TmSrcAuth_Inv "Telematics GPS Time Source Protected : Time Source Authenticated Invalid";
BA_ "SignalType" SG_ 1403 TGPSTSP_TmSrcAuth "ENM";
BA_ "SignalLongName" SG_ 1403 TGPSTSP_TmSrcAuth "Telematics GPS Time Source Protected : Time Source Authenticated";
BA_ "SignalLongName" SG_ 1403 TGPSTSP_UTCMinsAuth "Telematics GPS Time Source Protected : UTC Minutes Authenticated";
BA_ "SignalType" SG_ 1403 TGPSTSP_UTCHrsAuth_Inv "ENM";
BA_ "SignalLongName" SG_ 1403 TGPSTSP_UTCHrsAuth_Inv "Telematics GPS Time Source Protected : UTC Hours Authenticated Invalid";
BA_ "SignalType" SG_ 1403 TGPSTSP_UTCSecsAuth_Inv "ENM";
BA_ "SignalLongName" SG_ 1403 TGPSTSP_UTCSecsAuth_Inv "Telematics GPS Time Source Protected : UTC Seconds Authenticated Invalid";
BA_ "SignalLongName" SG_ 1403 TGPSTSP_UTCSecsAuth "Telematics GPS Time Source Protected : UTC Seconds Authenticated";
BA_ "SignalType" SG_ 1403 TGPSTSP_UTCMinsAuth_Inv "ENM";
BA_ "SignalLongName" SG_ 1403 TGPSTSP_UTCMinsAuth_Inv "Telematics GPS Time Source Protected : UTC Minutes Authenticated Invalid";
BA_ "SignalLongName" SG_ 1403 TGPSTSP_ARC "Telematics GPS Time Source Protected : Alive Rolling Count";
BA_ "SignalLongName" SG_ 1818 TlmGenInfo1_PCSM "Telematics General Information 1 Protected Counter Sync Message";
BA_ "SignalLongName" SG_ 1101 TGI1P_MAC "Telematics General Information 1 Protected : MAC";
BA_ "SignalLongName" SG_ 1101 TGI1P_FCnt "Telematics General Information 1 Protected : Freshness Counter";
BA_ "SignalType" SG_ 1101 TGI1P_NewFobXmtrLrndRstAuth "ENM";
BA_ "SignalLongName" SG_ 1101 TGI1P_NewFobXmtrLrndRstAuth "Telematics General Information 1 Protected : New Fob Transmitter Learned Reset Authenticated";
BA_ "SignalType" SG_ 1101 TGI1P_EnhdServsLckReqAuth "ENM";
BA_ "SignalLongName" SG_ 1101 TGI1P_EnhdServsLckReqAuth "Telematics General Information 1 Protected : Enhanced Services Locking Request Authenticated";
BA_ "SignalType" SG_ 1101 TGI1P_TlmRmtIgnBlkImbCmdAuth "ENM";
BA_ "SignalLongName" SG_ 1101 TGI1P_TlmRmtIgnBlkImbCmdAuth "Telematics General Information 1 Protected : Telematics Remote Ignition Block Immobilization Command Authenticated";
BA_ "SignalType" SG_ 1101 TGI1P_EnhdServsRmtStrtReqAuth "ENM";
BA_ "SignalLongName" SG_ 1101 TGI1P_EnhdServsRmtStrtReqAuth "Telematics General Information 1 Protected : Enhanced Services Remote Start Request Authenticated";
BA_ "SignalLongName" SG_ 1832 TlmSysGenInfo1_PCSM "Telematics System General Information 1 Protected Counter Sync Message";
BA_ "SignalLongName" SG_ 1382 TSGI1P_MAC "Telematics System General Information 1 Protected : MAC";
BA_ "SignalLongName" SG_ 1382 TSGI1P_FCnt "Telematics System General Information 1 Protected : Freshness Counter";
BA_ "SignalType" SG_ 1382 TSGI1P_EnhdServsSnrfRqAuth "ENM";
BA_ "SignalLongName" SG_ 1382 TSGI1P_EnhdServsSnrfRqAuth "Telematics System General Information 1 Protected : Enhanced Services Sunroof Request Authenticated";
BA_ "SignalType" SG_ 1382 TSGI1P_EnhdServsRrClsrLckRqAuth "ENM";
BA_ "SignalLongName" SG_ 1382 TSGI1P_EnhdServsRrClsrLckRqAuth "Telematics System General Information 1 Protected : Enhanced Services Rear Closure Locking Request Authenticated";
BA_ "SignalType" SG_ 1382 TSGI1P_EnhdServsAllWndRqAuth "ENM";
BA_ "SignalLongName" SG_ 1382 TSGI1P_EnhdServsAllWndRqAuth "Telematics System General Information 1 Protected : Enhanced Services All Window Request Authenticated";
BA_ "SignalLongName" SG_ 1104 TlmVirtKeyReq_PCSM "Telematics Virtual Key Request Protected Counter Sync Message";
BA_ "SignalLongName" SG_ 1102 TVKRP_MAC "Telematics Virtual Key Request Protected : MAC";
BA_ "SignalLongName" SG_ 1102 TVKRP_Fcnt "Telematics Virtual Key Request Protected : Freshness Counter";
BA_ "SignalType" SG_ 1102 TVKRP_FobAvlReqAuth "ENM";
BA_ "SignalLongName" SG_ 1102 TVKRP_FobAvlReqAuth "Telematics Virtual Key Request Protected : Fob Availability Request Authenticated";
BA_ "SignalType" SG_ 1102 TVKRP_VirtKeyRsrvtnRvkReqAuth "ENM";
BA_ "SignalLongName" SG_ 1102 TVKRP_VirtKeyRsrvtnRvkReqAuth "Telematics Virtual Key Request Protected : Virtual Key Reservation Revoke Request Authenticated";
BA_ "SignalType" SG_ 1267 HtchVwAutoElecPrkBrkAppReqd "ENM";
BA_ "SignalLongName" SG_ 1267 HtchVwAutoElecPrkBrkAppReqd "Hitch View Autonomous Electric Park Brake Apply Requested";
BA_ "SignalType" SG_ 1252 TrlrVidVwPhs1ChmEvntStat "ENM";
BA_ "SignalLongName" SG_ 1252 TrlrVidVwPhs1ChmEvntStat "Trailering Video Viewing Phase 1 Chime Event State";
BA_ "SignalType" SG_ 1252 VidTrlrTowPhs2ChmEvntStat "ENM";
BA_ "SignalLongName" SG_ 1252 VidTrlrTowPhs2ChmEvntStat "Trailering Video Viewing Phase 2 Chime Event State";
BA_ "SignalType" SG_ 1252 VidTrlrTowPhs1ChmEvntStat "ENM";
BA_ "SignalLongName" SG_ 1252 VidTrlrTowPhs1ChmEvntStat "Rear Pedestrian Collision Mitigation Notify Chime Event State";
BA_ "SignalLongName" SG_ 1194 TrnsOilTmp "Transmission Oil Temperature";
BA_ "SignalType" SG_ 1194 TrnsOilTmp_Inv "ENM";
BA_ "SignalLongName" SG_ 1194 TrnsOilTmp_Inv "Transmission Oil Temperature Invalid";
BA_ "SignalType" SG_ 1229 TrnsThrmlMngmntSt "ENM";
BA_ "SignalLongName" SG_ 1229 TrnsThrmlMngmntSt "Transmission Thermal Management Status";
BA_ "SignalLongName" SG_ 1051 TrlrBrkInfo_PCSM "Trailer Brake Information Protected Counter Sync Message";
BA_ "SignalLongName" SG_ 1046 TBIP_MAC "Trailer Brake Information Protected : MAC";
BA_ "SignalLongName" SG_ 1046 TBIP_FCnt "Trailer Brake Information Protected : Freshness Counter";
BA_ "SignalLongName" SG_ 1046 TBIP_TrlrBrkgGainSetAuth "Trailer Brake Information Protected : Trailer Braking Gain Setting Authenticated";
BA_ "SignalType" SG_ 1046 TBIP_TrlrBrkgGainSetIndOnAuth "ENM";
BA_ "SignalLongName" SG_ 1046 TBIP_TrlrBrkgGainSetIndOnAuth "Trailer Brake Information Protected : Trailer Braking Gain Setting Indication On Authenticated";
BA_ "SignalType" SG_ 1046 TBIP_TrlrWrgFltIndOnAuth "ENM";
BA_ "SignalLongName" SG_ 1046 TBIP_TrlrWrgFltIndOnAuth "Trailer Brake Information Protected : Trailer Wiring Fault Indication On Authenticated";
BA_ "SignalType" SG_ 1046 TBIP_ServTrlrBrkgSysIndOnAuth "ENM";
BA_ "SignalLongName" SG_ 1046 TBIP_ServTrlrBrkgSysIndOnAuth "Trailer Brake Information Protected : Service Trailer Braking System Indication On Authenticated";
BA_ "SignalType" SG_ 1046 TBIP_TrlrBrkDsbldIndOnAuth "ENM";
BA_ "SignalLongName" SG_ 1046 TBIP_TrlrBrkDsbldIndOnAuth "Trailer Brake Information Protected : Trailer Brakes Disabled Indication On Authenticated";
BA_ "SignalType" SG_ 1046 TBIP_CkTrlrIndOnAuth "ENM";
BA_ "SignalLongName" SG_ 1046 TBIP_CkTrlrIndOnAuth "Trailer Brake Information Protected : Check Trailer Indication On Authenticated";
BA_ "SignalLongName" SG_ 1046 TBIP_ARC "Trailer Brake Information Protected : Alive Rolling Count";
BA_ "SignalLongName" SG_ 30 TGI2P_MAC "Transmission General Information 2 Protected : MAC";
BA_ "SignalLongName" SG_ 30 TGI2P_FCnt "Transmission General Information 2 Protected : Freshness Counter";
BA_ "SignalLongName" SG_ 30 TGI2P_TrnsOutShftAngVelAuth "Transmission General Information 2 Protected : Transmission Output Shaft Angular Velocity Authenticated";
BA_ "SignalLongName" SG_ 30 TGI2P_ARC "Transmission General Information 2 Protected : Alive Rolling Count";
BA_ "SignalType" SG_ 30 TGI2P_TrnsOutShftAngVelAuth_Inv "ENM";
BA_ "SignalLongName" SG_ 30 TGI2P_TrnsOutShftAngVelAuth_Inv "Transmission General Information 2 Protected : Transmission Output Shaft Angular Velocity Authenticated Invalid";
BA_ "SignalLongName" SG_ 1111 UnlckKeyStorCrptoDat1 "Unlock Key Store Cryptographic Data 1";
BA_ "SignalLongName" SG_ 1112 UnlckKeyStorCrptoDat2 "Unlock Key Store Cryptographic Data 2";
BA_ "SignalLongName" SG_ 1113 VehIdNmDig10_17 "Vehicle Identification Number Digits 10-17";
BA_ "SignalLongName" SG_ 1114 VehIdNmDig2_9 "Vehicle Identification Number Digits 2-9";
BA_ "SignalLongName" SG_ 1797 VehMtnMvmt_PCSM "Vehicle Motion Movement Protected Counter Sync Message";
BA_ "SignalLongName" SG_ 1035 VMMP_MAC "Vehicle Motion Movement Protected : MAC";
BA_ "SignalLongName" SG_ 1035 VMMP_FCnt "Vehicle Motion Movement Protected : Freshness Counter";
BA_ "SignalLongName" SG_ 1035 VMMP_ARC "Vehicle Motion Movement Protected : Alive Rolling Count";
BA_ "SignalType" SG_ 1035 VMMP_VehMtnMvmtStatAuth "ENM";
BA_ "SignalLongName" SG_ 1035 VMMP_VehMtnMvmtStatAuth "Vehicle Motion Movement Protected : Vehicle Motion Movement State Authenticated";
BA_ "SignalLongName" SG_ 1798 VehOdoDispVal_PCSM "Vehicle Odometer Display Value Protected Counter Sync Message";
BA_ "SignalLongName" SG_ 1036 VODVP_MAC "Vehicle Odometer Display Value Protected : MAC";
BA_ "SignalLongName" SG_ 1036 VODVP_FCnt "Vehicle Odometer Display Value Protected : Freshness Counter";
BA_ "SignalLongName" SG_ 1036 VODVP_VehOdoDispValAuth "Vehicle Odometer Display Value Protected : Vehicle Odometer Display Value Authenticated";
BA_ "SignalType" SG_ 1036 VODVP_VehOdoDispValAuth_Inv "ENM";
BA_ "SignalLongName" SG_ 1036 VODVP_VehOdoDispValAuth_Inv "Vehicle Odometer Display Value Protected : Vehicle Odometer Display Value Authenticated Invalid";
BA_ "SignalLongName" SG_ 1815 VehOdoStrdDispVal_PCSM "Vehicle Odometer Stored Display Value Protected Counter Sync Message";
BA_ "SignalLongName" SG_ 1079 VOSDVP_MAC "Vehicle Odometer Stored Display Value Protected : MAC";
BA_ "SignalLongName" SG_ 1079 VOSDVP_Fcnt "Vehicle Odometer Stored Display Value Protected : Freshness Counter";
BA_ "SignalLongName" SG_ 1079 VOSDVP_VehOdoStrdDispValAuth "Vehicle Odometer Stored Display Value Protected : Vehicle Odometer Stored Display Value Authenticated";
BA_ "SignalType" SG_ 1079 VOSDVP_VehOdoStrdDspValAuth_Inv "ENM";
BA_ "SignalLongName" SG_ 1079 VOSDVP_VehOdoStrdDspValAuth_Inv "Vehicle Odometer Stored Display Value Protected : Vehicle Odometer Stored Display Value Authenticated Invalid";
BA_ "SignalLongName" SG_ 1807 VehSpdAvgDrvn_PCSM "Vehicle Speed Average Driven Protected Counter Sync Message";
BA_ "SignalLongName" SG_ 553 VSADP_MAC "Vehicle Speed Average Driven Protected : MAC";
BA_ "SignalLongName" SG_ 553 VSADP_FCnt "Vehicle Speed Average Driven Protected : Freshness Counter";
BA_ "SignalLongName" SG_ 553 VSADP_VehSpdAvgDrvnAuth "Vehicle Speed Average Driven Protected : Vehicle Speed Average Driven Authenticated";
BA_ "SignalType" SG_ 553 VSADP_VehSpdAvgDrvnAuth_Inv "ENM";
BA_ "SignalLongName" SG_ 553 VSADP_VehSpdAvgDrvnAuth_Inv "Vehicle Speed Average Driven Protected : Vehicle Speed Average Driven Authenticated Invalid";
BA_ "SignalLongName" SG_ 553 VSADP_ARC "Vehicle Speed Average Driven Protected : Alive Rolling Count";
BA_ "SignalType" SG_ 553 VSADP_FuelModeStsAuth "ENM";
BA_ "SignalLongName" SG_ 553 VSADP_FuelModeStsAuth "Vehicle Speed Average Driven Protected : Fuel Mode Status Authenticated";
BA_ "SignalType" SG_ 553 VSADP_RdcdPwrIndOnAuth "ENM";
BA_ "SignalLongName" SG_ 553 VSADP_RdcdPwrIndOnAuth "Vehicle Speed Average Driven Protected : Reduced Power Indication On Authenticated";
BA_ "SignalType" SG_ 553 VSADP_VehSpdAvgDrvnSrcAuth "ENM";
BA_ "SignalLongName" SG_ 553 VSADP_VehSpdAvgDrvnSrcAuth "Vehicle Speed Average Driven Protected : Vehicle Speed Average Driven Source Authenticated";
BA_ "SignalLongName" SG_ 554 VSANDP_MAC "Vehicle Speed Average Non Driven Protected : MAC";
BA_ "SignalLongName" SG_ 554 VSANDP_Fcnt "Vehicle Speed Average Non Driven Protected : Freshness Counter";
BA_ "SignalLongName" SG_ 554 VSANDP_VehSpdAvgNDrvnAuth "Vehicle Speed Average Non Driven Protected : Vehicle Speed Average NonDriven Authenticated";
BA_ "SignalType" SG_ 554 VSANDP_VehSpdAvgNDrvnAuth_Inv "ENM";
BA_ "SignalLongName" SG_ 554 VSANDP_VehSpdAvgNDrvnAuth_Inv "Vehicle Speed Average Non Driven Protected : Vehicle Speed Average Non Driven Authenticated Invalid";
BA_ "SignalLongName" SG_ 554 VSANDP_ARC "Vehicle Speed Average Non Driven Protected : Alive Rolling Count";
BA_ "SignalLongName" SG_ 1042 VirtKeyInfo2_PCSM "Virtual Key Information 2 Protected Counter Sync Message";
BA_ "SignalLongName" SG_ 1037 VKI2P_MAC "Virtual Key Information 2 Protected : MAC";
BA_ "SignalLongName" SG_ 1037 VKI2P_Fcnt "Virtual Key Information 2 Protected : Freshness Counter";
BA_ "SignalType" SG_ 1037 VKI2P_FobAvlStsAuth "ENM";
BA_ "SignalLongName" SG_ 1037 VKI2P_FobAvlStsAuth "Virtual Key Information 2 Protected : Fob Availability Status Authenticated";
BA_ "SignalLongName" SG_ 1037 VKI2P_AuthIntrUserIdDevCntAuth "Virtual Key Information 2 Protected : Authenticated Interior User Identification Device Count Authenticated";
BA_ "SignalLongName" SG_ 1822 VirtKeyInfo3_PCSM "Virtual Key Information 3 Protected Counter Sync Message";
BA_ "SignalLongName" SG_ 1260 VKI3P_MAC "Virtual Key Information 3 Protected : MAC";
BA_ "SignalLongName" SG_ 1260 VKI3P_FCnt "Virtual Key Information 3 Protected : Freshness Counter";
BA_ "SignalType" SG_ 1260 VKI3P_PncHrnReqAuth "ENM";
BA_ "SignalLongName" SG_ 1260 VKI3P_PncHrnReqAuth "Virtual Key Information 3 Protected : Panic Horn Request Authenticated";
BA_ "SignalType" SG_ 1260 VKI3P_MirUnfldReqdAuth "ENM";
BA_ "SignalLongName" SG_ 1260 VKI3P_MirUnfldReqdAuth "Virtual Key Information 3 Protected : Mirror Unfold Requested Authenticated";
BA_ "SignalType" SG_ 1260 VKI3P_MirFoldReqdAuth "ENM";
BA_ "SignalLongName" SG_ 1260 VKI3P_MirFoldReqdAuth "Virtual Key Information 3 Protected : Mirror Fold Requested Authenticated";
BA_ "SignalType" SG_ 1260 VKI3P_FobAvlReqAuth "ENM";
BA_ "SignalLongName" SG_ 1260 VKI3P_FobAvlReqAuth "Virtual Key Information 3 Protected : Fob Availability Request Authenticated";
BA_ "SignalType" SG_ 1260 VKI3P_ChrgOnReqdAuth "ENM";
BA_ "SignalLongName" SG_ 1260 VKI3P_ChrgOnReqdAuth "Virtual Key Information 3 Protected : Charge On Requested Authenticated";
BA_ "SignalType" SG_ 1260 VKI3P_ChrgOffReqdAuth "ENM";
BA_ "SignalLongName" SG_ 1260 VKI3P_ChrgOffReqdAuth "Virtual Key Information 3 Protected : Charge Off Requested Authenticated";
BA_ "SignalType" SG_ 1260 VKI3P_RmtLctrHrnReqAuth "ENM";
BA_ "SignalLongName" SG_ 1260 VKI3P_RmtLctrHrnReqAuth "Virtual Key Information 3 Protected : Remote Locator Horn Request Authenticated";
BA_ "SignalType" SG_ 1260 VKI3P_RmtFlOprtdHtrOnReqdAuth "ENM";
BA_ "SignalLongName" SG_ 1260 VKI3P_RmtFlOprtdHtrOnReqdAuth "Virtual Key Information 3 Protected : Remote Fuel Operated Heater On Requested Authenticated";
BA_ "SignalType" SG_ 1260 VKI3P_RmtFlOprtdHtrOffReqdAuth "ENM";
BA_ "SignalLongName" SG_ 1260 VKI3P_RmtFlOprtdHtrOffReqdAuth "Virtual Key Information 3 Protected : Remote Fuel Operated Heater Off Requested Authenticated";
BA_ "SignalType" SG_ 1260 VKI3P_PwrToPCtlReqAuth "ENM";
BA_ "SignalLongName" SG_ 1260 VKI3P_PwrToPCtlReqAuth "Virtual Key Information 3 Protected : Power Top Control Request Authenticated";
BA_ "SignalType" SG_ 1260 VKI3P_PncLgtReqAuth "ENM";
BA_ "SignalLongName" SG_ 1260 VKI3P_PncLgtReqAuth "Virtual Key Information 3 Protected : Panic Light Request Authenticated";
BA_ "SignalType" SG_ 1260 VKI3P_VehStrtReqdAuth "ENM";
BA_ "SignalLongName" SG_ 1260 VKI3P_VehStrtReqdAuth "Virtual Key Information 3 Protected : Vehicle Start Requested Authenticated";
BA_ "SignalType" SG_ 1260 VKI3P_VehStopReqdAuth "ENM";
BA_ "SignalLongName" SG_ 1260 VKI3P_VehStopReqdAuth "Virtual Key Information 3 Protected : Vehicle Stop Requested Authenticated";
BA_ "SignalType" SG_ 1260 VKI3P_RsrvtnRvkStsAuth "ENM";
BA_ "SignalLongName" SG_ 1260 VKI3P_RsrvtnRvkStsAuth "Virtual Key Information 3 Protected : Reservation Revoke Status Authenticated";
BA_ "SignalType" SG_ 1260 VKI3P_RmtLctrLgtReqAuth "ENM";
BA_ "SignalLongName" SG_ 1260 VKI3P_RmtLctrLgtReqAuth "Virtual Key Information 3 Protected : Remote Locator Light Request Authenticated";
BA_ "SignalType" SG_ 1260 VKI3P_WndOpnReqdAuth "ENM";
BA_ "SignalLongName" SG_ 1260 VKI3P_WndOpnReqdAuth "Virtual Key Information 3 Protected : Window Open Requested Authenticated";
BA_ "SignalType" SG_ 1260 VKI3P_WndClsReqdAuth "ENM";
BA_ "SignalLongName" SG_ 1260 VKI3P_WndClsReqdAuth "Virtual Key Information 3 Protected : Window Close Requested Authenticated";
BA_ "SignalLongName" SG_ 1823 VirtKeyInfo_PCSM "Virtual Key Information Protected Counter Sync Message";
BA_ "SignalLongName" SG_ 1288 VKIP_MAC "Virtual Key Information Protected : MAC";
BA_ "SignalLongName" SG_ 1288 VKIP_FCnt "Virtual Key Information Protected : Freshness Counter";
BA_ "SignalType" SG_ 1288 VKIP_ExtLtStsAuth "ENM";
BA_ "SignalLongName" SG_ 1288 VKIP_ExtLtStsAuth "Virtual Key Information Protected : Exterior Left Status Authenticated";
BA_ "SignalType" SG_ 1288 VKIP_ExtFrtStsAuth "ENM";
BA_ "SignalLongName" SG_ 1288 VKIP_ExtFrtStsAuth "Virtual Key Information Protected : Exterior Front Status Authenticated";
BA_ "SignalType" SG_ 1288 VKIP_DrvrDrUnlckReqdAuth "ENM";
BA_ "SignalLongName" SG_ 1288 VKIP_DrvrDrUnlckReqdAuth "Virtual Key Information Protected : Driver Door Unlock Requested Authenticated";
BA_ "SignalType" SG_ 1288 VKIP_DrLckReqdAuth "ENM";
BA_ "SignalLongName" SG_ 1288 VKIP_DrLckReqdAuth "Virtual Key Information Protected : Door Lock Requested Authenticated";
BA_ "SignalType" SG_ 1288 VKIP_AllDrUnlckReqdAuth "ENM";
BA_ "SignalLongName" SG_ 1288 VKIP_AllDrUnlckReqdAuth "Virtual Key Information Protected : All Door Unlock Requested Authenticated";
BA_ "SignalType" SG_ 1288 VKIP_FrtCmptRelReqdAuth "ENM";
BA_ "SignalLongName" SG_ 1288 VKIP_FrtCmptRelReqdAuth "Virtual Key Information Protected : Front Compartment Release Requested Authenticated";
BA_ "SignalType" SG_ 1288 VKIP_ExtRtStsAuth "ENM";
BA_ "SignalLongName" SG_ 1288 VKIP_ExtRtStsAuth "Virtual Key Information Protected : Exterior Right Status Authenticated";
BA_ "SignalType" SG_ 1288 VKIP_ExtRrStsAuth "ENM";
BA_ "SignalLongName" SG_ 1288 VKIP_ExtRrStsAuth "Virtual Key Information Protected : Exterior Rear Status Authenticated";
BA_ "SignalType" SG_ 1288 VKIP_PwrRrClsrCtlReqAuth "ENM";
BA_ "SignalLongName" SG_ 1288 VKIP_PwrRrClsrCtlReqAuth "Virtual Key Information Protected : Power Rear Closure Control Request Authenticated";
BA_ "SignalLongName" SG_ 1288 VKIP_IntrZnCntAuth "Virtual Key Information Protected : Interior Zone Count Authenticated";
BA_ "SignalType" SG_ 1288 VKIP_FrtRtEntZnDevPrsntAuth "ENM";
BA_ "SignalLongName" SG_ 1288 VKIP_FrtRtEntZnDevPrsntAuth "Virtual Key Information Protected : Front Right Entry Zone Device Present Authenticated";
BA_ "SignalType" SG_ 1288 VKIP_RrLtEntZnDevPrsntAuth "ENM";
BA_ "SignalLongName" SG_ 1288 VKIP_RrLtEntZnDevPrsntAuth "Virtual Key Information Protected : Rear Left Entry Zone Device Present Authenticated";
BA_ "SignalType" SG_ 1288 VKIP_FrtLtEntZnDevPrsntAuth "ENM";
BA_ "SignalLongName" SG_ 1288 VKIP_FrtLtEntZnDevPrsntAuth "Virtual Key Information Protected : Front Left Entry Zone Device Present Authenticated";
BA_ "SignalType" SG_ 1288 VKIP_WlcmZnDevPrsntAuth "ENM";
BA_ "SignalLongName" SG_ 1288 VKIP_WlcmZnDevPrsntAuth "Virtual Key Information Protected : Welcome Zone Device Present Authenticated";
BA_ "SignalType" SG_ 1288 VKIP_RrRtEntZnDevPrsntAuth "ENM";
BA_ "SignalLongName" SG_ 1288 VKIP_RrRtEntZnDevPrsntAuth "Virtual Key Information Protected : Rear Right Entry Zone Device Present Authenticated";
BA_ "SignalType" SG_ 1288 VKIP_RrExtZnDevPrsntAuth "ENM";
BA_ "SignalLongName" SG_ 1288 VKIP_RrExtZnDevPrsntAuth "Virtual Key Information Protected : Rear Exterior Zone Device Present Authenticated";
BA_ "SignalType" SG_ 1288 VKIP_RrClsrRelReqdAuth "ENM";
BA_ "SignalLongName" SG_ 1288 VKIP_RrClsrRelReqdAuth "Virtual Key Information Protected : Rear Closure Release Requested Authenticated";
BA_ "SignalType" SG_ 1288 VKIP_RrClsrOnAprchReqdAuth "ENM";
BA_ "SignalLongName" SG_ 1288 VKIP_RrClsrOnAprchReqdAuth "Virtual Key Information Protected : Rear Closure On Approach Requested Authenticated";
BA_ "SignalLongName" SG_ 1105 VirtKeyRsrvtnRvk_PCSM "Virtual Key Reservation Revoke Protected Counter Sync Message";
BA_ "SignalLongName" SG_ 1103 VKRRP_MAC "Virtual Key Reservation Revoke Protected : MAC";
BA_ "SignalLongName" SG_ 1103 VKRRP_Fcnt "Virtual Key Reservation Revoke Protected : Freshness Counter";
BA_ "SignalLongName" SG_ 1103 VKRRP_RvkRsrvtnIDAuth "Virtual Key Reservation Revoke Protected : Virtual Key Revoke Reservation ID Authenticated";
BA_ "SignalType" SG_ 1343 PhnLtInVehCstAvlFlg7 "ENM";
BA_ "SignalLongName" SG_ 1343 PhnLtInVehCstAvlFlg7 "Phone Left In Vehicle Customization Availability Flag 7";
BA_ "SignalType" SG_ 1343 PhnLtInVehCstAvlFlg6 "ENM";
BA_ "SignalLongName" SG_ 1343 PhnLtInVehCstAvlFlg6 "Phone Left In Vehicle Customization Availability Flag 6";
BA_ "SignalType" SG_ 1343 PhnLtInVehCstAvlFlg5 "ENM";
BA_ "SignalLongName" SG_ 1343 PhnLtInVehCstAvlFlg5 "Phone Left In Vehicle Customization Availability Flag 5";
BA_ "SignalType" SG_ 1343 PhnLtInVehCstAvlFlg4 "ENM";
BA_ "SignalLongName" SG_ 1343 PhnLtInVehCstAvlFlg4 "Phone Left In Vehicle Customization Availability Flag 4";
BA_ "SignalType" SG_ 1343 PhnLtInVehCstAvlFlg3 "ENM";
BA_ "SignalLongName" SG_ 1343 PhnLtInVehCstAvlFlg3 "Phone Left In Vehicle Customization Availability Flag 3";
BA_ "SignalType" SG_ 1343 PhnLtInVehCstAvlFlg2 "ENM";
BA_ "SignalLongName" SG_ 1343 PhnLtInVehCstAvlFlg2 "Phone Left In Vehicle Customization Availability Flag 2";
BA_ "SignalType" SG_ 1343 PhnLtInVehCstAvlFlg1 "ENM";
BA_ "SignalLongName" SG_ 1343 PhnLtInVehCstAvlFlg1 "Phone Left In Vehicle Customization Availability Flag 1";
BA_ "SignalType" SG_ 1344 PhnLtInVehIndOn "ENM";
BA_ "SignalLongName" SG_ 1344 PhnLtInVehIndOn "Phone Left In Vehicle Indication On";
BA_ "SignalType" SG_ 1344 WrlsChrgSysChrgStat "ENM";
BA_ "SignalLongName" SG_ 1344 WrlsChrgSysChrgStat "Wireless Charging System Charging Status";
BA_ "SignalType" SG_ 1345 PhnLtInVehCstSetAval "ENM";
BA_ "SignalLongName" SG_ 1345 PhnLtInVehCstSetAval "Phone Left In Vehicle Customization Setting Available";
BA_ "SignalType" SG_ 1345 PhnLtInVehCstCurrSetVal "ENM";
BA_ "SignalLongName" SG_ 1345 PhnLtInVehCstCurrSetVal "Phone Left In Vehicle Customization Current Setting Value";
BA_ "SignalLongName" SG_ 50 LCMDI_WCM_DatAvalCksum "License Compliance Material Display Interface - Wireless Charger Module : Data Available Checksum";
BA_ "SignalLongName" SG_ 50 LCMDI_WCM_DatAvalLicTag "License Compliance Material Display Interface - Wireless Charger Module : Data Available License Tag";
BA_ "SignalLongName" SG_ 50 LCMDI_WCM_DatAvalOwnID "License Compliance Material Display Interface - Wireless Charger Module : Data Available Owner Identification";
BA_ "SignalLongName" SG_ 50 LCMDI_WCM_DatAvalTotBlks "License Compliance Material Display Interface - Wireless Charger Module : Data Available Total Blocks";
VAL_ 1333 UTCYr_Inv 0 "FALSE" 1 "TRUE" ;
VAL_ 1333 UTCMin_Inv 0 "FALSE" 1 "TRUE" ;
VAL_ 1333 UTCDay_Inv 0 "FALSE" 1 "TRUE" ;
VAL_ 1333 UTCSec_Inv 0 "FALSE" 1 "TRUE" ;
VAL_ 1333 UTCHrs_Inv 0 "FALSE" 1 "TRUE" ;
VAL_ 1333 UTCMth 0 "Unknown" 1 "January" 2 "February" 3 "March" 4 "April" 5 "May" 6 "June" 7 "July" 8 "August" 9 "September" 10 "October" 11 "November" 12 "December" ;
VAL_ 1333 UTCMth_Inv 0 "FALSE" 1 "TRUE" ;
VAL_ 1333 CellNWDateTimeAvl 0 "FALSE" 1 "TRUE" ;
VAL_ 1338 CmpsOctHding 0 "N" 1 "NE" 2 "E" 3 "SE" 4 "S" 5 "SW" 6 "W" 7 "NW" ;
VAL_ 1338 CmpsDecZone 0 "Unknown" 1 "Zone 1" 2 "Zone 2" 3 "Zone 3" 4 "Zone 4" 5 "Zone 5" 6 "Zone 6" 7 "Zone 7" 8 "Zone 8" 9 "Zone 9" 10 "zone 10" 11 "Zone 11" 12 "Zone 12" 13 "Zone 13" 14 "Zone 14" 15 "Zone 15" ;
VAL_ 1338 EmrgRespSysServIndOn 0 "FALSE" 1 "TRUE" ;
VAL_ 1338 CmpsZnNvrSet 0 "False" 1 "True" ;
VAL_ 1338 CmpsSatrtd 0 "False" 1 "True" ;
VAL_ 1338 CmpsOctHdingDataSrc 0 "Stored Value" 1 "Calculated Value" ;
VAL_ 1338 CmpsModManCalInPrc 0 "False" 1 "True" ;
VAL_ 1338 CmpsModFltPrs 0 "False" 1 "True" ;
VAL_ 1274 CldrMth 0 "Unknown" 1 "January" 2 "February" 3 "March" 4 "April" 5 "May" 6 "June" 7 "July" 8 "August" 9 "September" 10 "October" 11 "November" 12 "December" ;
VAL_ 1285 IntDimSelAnmTypSetReq 0 "No Action" 1 "Off" 2 "Animation Type 1" 3 "Animation Type 2" 4 "Animation Type 3" 5 "Animation Type 4" 6 "Animation Type 5" 7 "Animation Type 6" 8 "Animation Type 7" 9 "Animation Type 8" 10 "Animation Type 9" 11 "Animation Type 10" 12 "Animation Type 11" 13 "Animation Type 12" 14 "Animation Type 13" 15 "Animation Type 14" ;
VAL_ 1285 IntDimSelColTypSetReq 0 "No Action" 1 "Off" 2 "Color Type 1" 3 "Color Type 2" 4 "Color Type 3" 5 "Color Type 4" 6 "Color Type 5" 7 "Color Type 6" 8 "Color Type 7" 9 "Color Type 8" 10 "Color Type 9" 11 "Color Type 10" 12 "Color Type 11" 13 "Color Type 12" 14 "Color Type 13" 15 "Color Type 14" 16 "Color Type 15" 17 "Color Type 16" 18 "Color Type 17" 19 "Color Type 18" 20 "Color Type 19" 21 "Color Type 20" 22 "Color Type 21" 23 "Color Type 22" 24 "Color Type 23" 25 "Color Type 24" 26 "Color Type 25" 27 "Color Type 26" 28 "Color Type 27" 29 "Color Type 28" 30 "Color Type 29" 31 "Color Type 30" ;
VAL_ 1285 RrZnStUpCstChgSetReq 0 "NO_ACTION" 1 "REAR_OFF" 2 "REAR_MIMIC_FRONT" 3 "REAR_LAST_KNOWN" 4 "RESERVED_4" 5 "RESERVED_5" 6 "RESERVED_6" 7 "RESERVED_7" ;
VAL_ 1285 RmtSnrfOpCstChgSetReq 0 "NO_ACTION" 1 "OFF" 2 "ON" 3 "RESERVED_3" 4 "RESERVED_4" 5 "RESERVED_5" 6 "RESERVED_6" 7 "RESERVED_7" ;
VAL_ 1309 FrtCntrStckHptcFdbkStat 0 "FEEDBACK_OFF" 1 "TAP" 2 "LONG_PRESS" 3 "PRESS_&_HOLD_SCROLL" 4 "PRESS_&_HOLD_END" 5 "RESERVED_05" 6 "RESERVED_06" 7 "RESERVED_07" 8 "RESERVED_08" 9 "RESERVED_09" 10 "RESERVED_10" 11 "RESERVED_11" 12 "RESERVED_12" 13 "RESERVED_13" 14 "RESERVED_14" 15 "RESERVED_15" ;
VAL_ 1309 FrtCntrStckTag2Sw 0 "Released" 1 "Pressed" ;
VAL_ 1309 FrtCntrStckTag1Sw 0 "Released" 1 "Pressed" ;
VAL_ 1309 FrtCntrStckPrxmtyStat 0 "FAR" 1 "NEAR" 2 "TOUCH" 3 "PRESS" 4 "PROX_STAT4" 5 "PROX_STAT5" 6 "PROX_STAT6" 7 "PROX_STAT7" ;
VAL_ 1309 FrtCntrStckPrxmtyGstr 0 "NO_ACTION" 1 "PROX_GESTURE1" 2 "PROX_GESTURE2" 3 "PROX_GESTURE3" 4 "PROX_GESTURE4" 5 "PROX_GESTURE5" 6 "PROX_GESTURE6" 7 "PROX_GESTURE7" ;
VAL_ 1309 FrtCntrStckVolUpSw 0 "Released" 1 "Pressed" ;
VAL_ 1309 FrtCntrStckVolDnSw 0 "Released" 1 "Pressed" ;
VAL_ 1309 FrtCntrStckToneSw 0 "Released" 1 "Pressed" ;
VAL_ 1309 FrtCntrStckTag5Sw 0 "Released" 1 "Pressed" ;
VAL_ 1309 FrtCntrStckTag4Sw 0 "Released" 1 "Pressed" ;
VAL_ 1309 FrtCntrStckTag3Sw 0 "Released" 1 "Pressed" ;
VAL_ 1033 LnFllwgFtrStat 0 "Off" 1 "Unavailable" 2 "Disabled" 3 "Enabled" 4 "Active" 5 "Cautionary" 6 "Override" 7 "Degraded" 8 "No Return" 9 "Ended" 10 "Non-Responsive Driver" ;
VAL_ 1377 NodeStsAPA_CAN_2_LcFA 0 "FALSE" 1 "TRUE" ;
VAL_ 1377 NodeStsAPA_CAN_1_LcFA 0 "FALSE" 1 "TRUE" ;
VAL_ 1377 NodeStsAOS_LcFA 0 "FALSE" 1 "TRUE" ;
VAL_ 1377 NodeStsAMP_LcFA 0 "FALSE" 1 "TRUE" ;
VAL_ 1377 NodeStsALC_LcFA 0 "FALSE" 1 "TRUE" ;
VAL_ 1377 NodeStsAHL_AFL_LcFA 0 "FALSE" 1 "TRUE" ;
VAL_ 1377 NodeStsAGC_LcFA 0 "FALSE" 1 "TRUE" ;
VAL_ 1377 NodeStsDMS_LcFA 0 "FALSE" 1 "TRUE" ;
VAL_ 1377 NodeStsDEFC_LcFA 0 "FALSE" 1 "TRUE" ;
VAL_ 1377 NodeStsDCM_LcFA 0 "FALSE" 1 "TRUE" ;
VAL_ 1377 NodeStsCSM_LcFA 0 "FALSE" 1 "TRUE" ;
VAL_ 1377 NodeStsBSM_CAN_3_LcFA 0 "FALSE" 1 "TRUE" ;
VAL_ 1377 NodeStsBSM_CAN_2_LcFA 0 "FALSE" 1 "TRUE" ;
VAL_ 1377 NodeStsBCM_LcFA 0 "FALSE" 1 "TRUE" ;
VAL_ 1377 NodeStsARB_LcFA 0 "FALSE" 1 "TRUE" ;
VAL_ 1377 NodeStsELM_LcFA 0 "FALSE" 1 "TRUE" ;
VAL_ 1377 NodeStsECP_X1_CAN_3_LcFA 0 "FALSE" 1 "TRUE" ;
VAL_ 1377 NodeStsECP_X1_CAN_2_LcFA 0 "FALSE" 1 "TRUE" ;
VAL_ 1377 NodeStsECM_CAN_3_LcFA 0 "FALSE" 1 "TRUE" ;
VAL_ 1377 NodeStsECM_CAN_2_LcFA 0 "FALSE" 1 "TRUE" ;
VAL_ 1377 NodeStsEBCM_CAN_2_LcFA 0 "FALSE" 1 "TRUE" ;
VAL_ 1377 NodeStsEBCM_CAN_1_LcFA 0 "FALSE" 1 "TRUE" ;
VAL_ 1377 NodeStsEPS_LcFA 0 "FALSE" 1 "TRUE" ;
VAL_ 1377 NodeStsEOCM_HCP2_LcFA 0 "FALSE" 1 "TRUE" ;
VAL_ 1377 NodeStsEOCM_HCP1_CAN_8_LcFA 0 "FALSE" 1 "TRUE" ;
VAL_ 1377 NodeStsEOCM_HCP1_CAN_2_LcFA 0 "FALSE" 1 "TRUE" ;
VAL_ 1377 NodeStsEOCM_HCP1_CAN_1_LcFA 0 "FALSE" 1 "TRUE" ;
VAL_ 1377 NodeStsEOCM_CAN_8_LcFA 0 "FALSE" 1 "TRUE" ;
VAL_ 1377 NodeStsEOCM_CAN_2_LcFA 0 "FALSE" 1 "TRUE" ;
VAL_ 1377 NodeStsEOCM_CAN_1_LcFA 0 "FALSE" 1 "TRUE" ;
VAL_ 1377 NodeStsIPC_LcFA 0 "FALSE" 1 "TRUE" ;
VAL_ 1377 NodeStsICS_Info_LcFA 0 "FALSE" 1 "TRUE" ;
VAL_ 1377 NodeStsICCM_LcFA 0 "FALSE" 1 "TRUE" ;
VAL_ 1377 NodeStsHVAC_FP_R_LcFA 0 "FALSE" 1 "TRUE" ;
VAL_ 1377 NodeStsHVAC_FP_F_LcFA 0 "FALSE" 1 "TRUE" ;
VAL_ 1377 NodeStsHUD_CAN_LcFA 0 "FALSE" 1 "TRUE" ;
VAL_ 1377 NodeStsFCM_LcFA 0 "FALSE" 1 "TRUE" ;
VAL_ 1377 NodeStsFCM_LC_LcFA 0 "FALSE" 1 "TRUE" ;
VAL_ 1377 NodeStsMSM_D_LcFA 0 "FALSE" 1 "TRUE" ;
VAL_ 1377 NodeStsMSB2_LcFA 0 "FALSE" 1 "TRUE" ;
VAL_ 1377 NodeStsMSB1_LcFA 0 "FALSE" 1 "TRUE" ;
VAL_ 1377 NodeStsMRCM_R_LcFA 0 "FALSE" 1 "TRUE" ;
VAL_ 1377 NodeStsMRCM_L_LcFA 0 "FALSE" 1 "TRUE" ;
VAL_ 1377 NodeStsMFC_LcFA 0 "FALSE" 1 "TRUE" ;
VAL_ 1377 NodeStsLRR_LcFA 0 "FALSE" 1 "TRUE" ;
VAL_ 1377 NodeStsLRR_HC_LcFA 0 "FALSE" 1 "TRUE" ;
VAL_ 1377 NodeStsPDR_LcFA 0 "FALSE" 1 "TRUE" ;
VAL_ 1377 NodeStsPA_LcFA 0 "FALSE" 1 "TRUE" ;
VAL_ 1377 NodeStsNVM_LcFA 0 "FALSE" 1 "TRUE" ;
VAL_ 1377 NodeStsMTCM_R_LcFA 0 "FALSE" 1 "TRUE" ;
VAL_ 1377 NodeStsMTCM_L_LcFA 0 "FALSE" 1 "TRUE" ;
VAL_ 1377 NodeStsMSM_RR_LcFA 0 "FALSE" 1 "TRUE" ;
VAL_ 1377 NodeStsMSM_P_LcFA 0 "FALSE" 1 "TRUE" ;
VAL_ 1377 NodeStsMSM_LR_LcFA 0 "FALSE" 1 "TRUE" ;
VAL_ 1377 NodeStsSBZA_R_LcFA 0 "FALSE" 1 "TRUE" ;
VAL_ 1377 NodeStsSBZA_L_LcFA 0 "FALSE" 1 "TRUE" ;
VAL_ 1377 NodeStsSADS_LcFA 0 "FALSE" 1 "TRUE" ;
VAL_ 1377 NodeStsAHS_LcFA 0 "FALSE" 1 "TRUE" ;
VAL_ 1377 NodeStsRSC_LcFA 0 "FALSE" 1 "TRUE" ;
VAL_ 1377 NodeStsRDCM_LcFA 0 "FALSE" 1 "TRUE" ;
VAL_ 1377 NodeStsRadioLow_LcFA 0 "FALSE" 1 "TRUE" ;
VAL_ 1377 NodeStsPTM_LcFA 0 "FALSE" 1 "TRUE" ;
VAL_ 1378 NodeStsSRR_SLR_LcFA 0 "FALSE" 1 "TRUE" ;
VAL_ 1378 NodeStsSRR_RR_LcFA 0 "FALSE" 1 "TRUE" ;
VAL_ 1378 NodeStsSRR_RF_LcFA 0 "FALSE" 1 "TRUE" ;
VAL_ 1378 NodeStsSRR_LR_CR_LcFA 0 "FALSE" 1 "TRUE" ;
VAL_ 1378 NodeStsSRR_LF_LcFA 0 "FALSE" 1 "TRUE" ;
VAL_ 1378 NodeStsSIB_LcFA 0 "FALSE" 1 "TRUE" ;
VAL_ 1378 NodeStsSDM_LcFA 0 "FALSE" 1 "TRUE" ;
VAL_ 1378 NodeStsSCL_LcFA 0 "FALSE" 1 "TRUE" ;
VAL_ 1378 NodeStsTIM_LcFA 0 "FALSE" 1 "TRUE" ;
VAL_ 1378 NodeStsTCP_LcFA 0 "FALSE" 1 "TRUE" ;
VAL_ 1378 NodeStsTCM_LcFA 0 "FALSE" 1 "TRUE" ;
VAL_ 1378 NodeStsTCCM3_LcFA 0 "FALSE" 1 "TRUE" ;
VAL_ 1378 NodeStsTCCM_LcFA 0 "FALSE" 1 "TRUE" ;
VAL_ 1378 NodeStsSTC_LcFA 0 "FALSE" 1 "TRUE" ;
VAL_ 1378 NodeStsSRR_SRR_LcFA 0 "FALSE" 1 "TRUE" ;
VAL_ 1378 NodeStsECP_E_CAN_9_LcFA 0 "FALSE" 1 "TRUE" ;
VAL_ 1378 NodeStsCMMb_CAN_2_LcFA 0 "FALSE" 1 "TRUE" ;
VAL_ 1378 NodeStsCMMa_CAN_2_LcFA 0 "FALSE" 1 "TRUE" ;
VAL_ 1378 NodeStsARS_LcFA 0 "FALSE" 1 "TRUE" ;
VAL_ 1378 NodeStsVLM_LcFA 0 "FALSE" 1 "TRUE" ;
VAL_ 1378 NodeStsWCM_LcFA 0 "FALSE" 1 "TRUE" ;
VAL_ 1378 NodeStsVPM_LcFA 0 "FALSE" 1 "TRUE" ;
VAL_ 1378 NodeStsVKM_LcFA 0 "FALSE" 1 "TRUE" ;
VAL_ 1378 NodeStsECP_E_CAN_2_LcFA 0 "FALSE" 1 "TRUE" ;
VAL_ 1441 NodeStsECP_MC_LcFA 0 "FALSE" 1 "TRUE" ;
VAL_ 1441 NodeStsCMMb_CAN_9_LcFA 0 "FALSE" 1 "TRUE" ;
VAL_ 1441 NodeStsCMMa_CAN_9_LcFA 0 "FALSE" 1 "TRUE" ;
VAL_ 1441 NodeStsBSM_MH_LcFA 0 "FALSE" 1 "TRUE" ;
VAL_ 1441 NodeStsSBM_CAN_9_LcFA 0 "FALSE" 1 "TRUE" ;
VAL_ 1441 NodeStsSBM_CAN_10_LcFA 0 "FALSE" 1 "TRUE" ;
VAL_ 1441 NodeStsLIB1_LcFA 0 "FALSE" 1 "TRUE" ;
VAL_ 1441 NodeStsHDLM_LcFA 0 "FALSE" 1 "TRUE" ;
VAL_ 1324 LVMAVR_StreoAudReq 0 "NO_ACTION" 1 "STEREO_REQUEST" ;
VAL_ 1324 LVMAVR_SpchRcgnActv 0 "NO_ACTION" 1 "LVM_SPEECH_REC_READY" 2 "LVM_SPEECH_REC_ACTIVE" ;
VAL_ 1324 LVMAVR_PrmtAudReq 0 "NO_ACTION" 1 "PROMPT_REQUEST" ;
VAL_ 1324 LVMAVR_DispReq 0 "NO_ACTION" 1 "LVM_NAV" 2 "LVM_DMB" 3 "LVM_PDR" ;
VAL_ 1324 IconRcrdReqActv 0 "FALSE" 1 "TRUE" ;
VAL_ 1324 LVMAVR_ApplStat 0 "NO_ACTION" 1 "LVM_NAV" 2 "LVM_DMB" 3 "LVM_PERFORMANCE_COMPUTER" 4 "LVM_COMPLEX_MODE" ;
VAL_ 551 PSP_VehTheftImbChlgRespStsAuth 0 "Undetermined" 1 "Pass" 2 "Fail" ;
VAL_ 551 PSP_RmtVehStrtEngRnngAuth 0 "FALSE" 1 "TRUE" ;
VAL_ 551 PSP_PwrtrnCrnkAbrtdAuth 0 "FALSE" 1 "TRUE" ;
VAL_ 551 PSP_PrplSysStlActvAuth 0 "FALSE" 1 "TRUE" ;
VAL_ 551 PSP_PrplSysActvAuth 0 "FALSE" 1 "TRUE" ;
VAL_ 551 PSP_EngRnngAuth 0 "FALSE" 1 "TRUE" ;
VAL_ 551 PSP_ClchBtmTrvlAchvdAuth_Inv 0 "FALSE" 1 "TRUE" ;
VAL_ 551 PSP_ClchBtmTrvlAchvdAuth 0 "FALSE" 1 "TRUE" ;
VAL_ 551 PSP_PrkNeutSwStatAuth_Inv 0 "FALSE" 1 "TRUE" ;
VAL_ 551 PSP_PrkNeutSwStatAuth 0 "Park/Neutral" 1 "Not Park/Neutral" ;
VAL_ 1090 PCIP_MemStRclDsblReqdAuth 0 "FALSE" 1 "TRUE" ;
VAL_ 1090 PCIP_IntrLgtOnReqdAuth 0 "FALSE" 1 "TRUE" ;
VAL_ 1090 PCIP_HzrdLgtsOnReqdAuth 0 "FALSE" 1 "TRUE" ;
VAL_ 1090 PCIP_HybVehHiVltgDsblReqdAuth 0 "FALSE" 1 "TRUE" ;
VAL_ 1090 PCIP_HVACBlwDsblReqdAuth 0 "FALSE" 1 "TRUE" ;
VAL_ 1090 PCIP_FuelCutOffReqdAuth 0 "FALSE" 1 "TRUE" ;
VAL_ 1090 PCIP_DrUnlckReqdAuth 0 "FALSE" 1 "TRUE" ;
VAL_ 1090 PCIP_BrkActReqdAuth 0 "FALSE" 1 "TRUE" ;
VAL_ 1090 PCIP_NftnFrtImpPrtnsrSevAchAuth 0 "FALSE" 1 "TRUE" ;
VAL_ 1090 PCIP_NtfnRlOvrSevAchvdAuth 0 "FALSE" 1 "TRUE" ;
VAL_ 1090 PCIP_NtfnPedtrnPrtctnSevAchAuth 0 "FALSE" 1 "TRUE" ;
VAL_ 1090 PCIP_NtfnLtSdSevAchvdAuth 0 "FALSE" 1 "TRUE" ;
VAL_ 1090 PCIP_NtfnFrtImpStg2SevAchvdAuth 0 "FALSE" 1 "TRUE" ;
VAL_ 1090 PCIP_NtfnFrtImpStg1SevAchvdAuth 0 "FALSE" 1 "TRUE" ;
VAL_ 1090 PCIP_NtfnEvntStsAuth 0 "No Event" 1 "Near Deploy Event" 2 "Deployment Event" ;
VAL_ 1090 PCIP_HVCrshImpSnsSysDsbldAuth 0 "FALSE" 1 "TRUE" ;
VAL_ 1090 PCIP_CruzCtlDsblReqdAuth 0 "FALSE" 1 "TRUE" ;
VAL_ 1090 PCIP_eCallReqdAuth 0 "FALSE" 1 "TRUE" ;
VAL_ 1090 PCIP_NtfnRtSdSevAchvdAuth 0 "FALSE" 1 "TRUE" ;
VAL_ 1090 PCIP_NtfnRrImpSevAchvdAuth 0 "FALSE" 1 "TRUE" ;
VAL_ 1067 PSIP_StrgAsstRdcdLvl3IndOnAuth 0 "FALSE" 1 "TRUE" ;
VAL_ 1067 PSIP_StrgAsstRdcdLvl2IndOnAuth 0 "FALSE" 1 "TRUE" ;
VAL_ 1067 PSIP_StrgAsstRdcdIndOnAuth 0 "FALSE" 1 "TRUE" ;
VAL_ 1067 PSIP_PwrStrgIndOnAuth 0 "FALSE" 1 "TRUE" ;
VAL_ 681 RPPSDBG2P_CldrYrAuth_Inv 0 "FALSE" 1 "TRUE" ;
VAL_ 681 RPPSDBG2P_ElvtnAuth_Inv 0 "FALSE" 1 "TRUE" ;
VAL_ 681 RPPSDBG2P_LngAuth_Inv 0 "FALSE" 1 "TRUE" ;
VAL_ 682 RPPSDBG3P_LocUsblAuth_Inv 0 "FALSE" 1 "TRUE" ;
VAL_ 682 RPPSDBG3P_LocUsblAuth 0 "FALSE" 1 "TRUE" ;
VAL_ 682 RPPSDBG3P_LatAuth_Inv 0 "FALSE" 1 "TRUE" ;
VAL_ 682 RPPSDBG3P_TmOfDyAuth_Inv 0 "FALSE" 1 "TRUE" ;
VAL_ 683 RPPSDBG4P_2DAbsPsErrEstAuth_Inv 0 "FALSE" 1 "TRUE" ;
VAL_ 683 RPPSDBG4P_AbsHdgErrEstAuth_Inv 0 "FALSE" 1 "TRUE" ;
VAL_ 683 RPPSDBG4P_CldrDyAuth_Inv 0 "FALSE" 1 "TRUE" ;
VAL_ 683 RPPSDBG4P_SigAcqTmAuth_Inv 0 "FALSE" 1 "TRUE" ;
VAL_ 680 RPPSDBG1P_HdgAuth_Inv 0 "FALSE" 1 "TRUE" ;
VAL_ 684 RPPSDBG5P_GPSModeAuth_Inv 0 "FALSE" 1 "TRUE" ;
VAL_ 684 RPPSDBG5P_GPSModeAuth 0 "GNSS Standalone" 1 "GNSS and SBAS" 2 "GNSS and RTX" 3 "GNSS and DR" 4 "GNSS and SBAS and DR" 5 "GNSS and RTX and DR" 6 "DR ONLY" 7 "GNSS and RTX and DR and MM" ;
VAL_ 684 RPPSDBG5P_LwrGblTmStmAuth_Inv 0 "FALSE" 1 "TRUE" ;
VAL_ 1327 RrSeatCtrlrPrsnt 0 "RSC_NotPresent" 1 "RSC_Present" ;
VAL_ 1327 RrSeatCtrlrBttns 0 "RSC_VOLUME_UP" 1 "RSC_VOLUME_DOWN" 2 "RSC_POWER" 3 "RSC_SOURCE_SELECT" 4 "RSC_PRESET" 5 "RSC_SEEK_UP" 6 "RSC_SEEK_DOWN" 7 "RSC_OK" 8 "RSC_BUTTON8" 9 "RSC_BUTTON9" 10 "RSC_BUTTON10" 11 "RSC_BUTTON11" 12 "RSC_BUTTON12" 13 "RSC_BUTTON13" 14 "RSC_BUTTON14" 15 "RSC_NONE" ;
VAL_ 516 RIP_RmtIgnBlkImbCustClrCmdAuth 0 "FALSE" 1 "TRUE" ;
VAL_ 516 RIP_PreRelAllwdAuth 0 "FALSE" 1 "TRUE" ;
VAL_ 516 RIP_NewFobXmtrLrndNtfnAuth 0 "FALSE" 1 "TRUE" ;
VAL_ 516 RIP_FrtCmptRelEnblReqAuth 0 "No_Action" 1 "Ajar" 2 "Open" ;
VAL_ 516 RIP_ElecStrgColUnlckAllwdAuth 0 "FALSE" 1 "TRUE" ;
VAL_ 516 RIP_StrtStopIgnSwPrssdAuth 0 "FALSE" 1 "TRUE" ;
VAL_ 1462 RrCrsTrfcBrkgAutoBrkgRelIndOn 0 "FALSE" 1 "TRUE" ;
VAL_ 35 SWIP_StrgWhlAngAuth_DuD 0 "FALSE" 1 "TRUE" ;
VAL_ 35 SWIP_StrgWhlAngCalStsAuth 0 "Unknown" 1 "Estimated" 2 "Calibrated" ;
VAL_ 35 SWIP_StrgWhlAngAuth_Inv 0 "FALSE" 1 "TRUE" ;
VAL_ 1357 SSVI_PrssClchPrssStrtAgnIO 0 "FALSE" 1 "TRUE" ;
VAL_ 1357 SSVI_NoRmtDtdIO 0 "FALSE" 1 "TRUE" ;
VAL_ 1357 SSVI_AutoShtdnDsbldIO 0 "FALSE" 1 "TRUE" ;
VAL_ 1357 SSVI_ShfToNeutPrssStrtAgnIO 0 "FALSE" 1 "TRUE" ;
VAL_ 1357 SSVI_AutoShtdnIO 0 "FALSE" 1 "TRUE" ;
VAL_ 1357 SSVI_AppPrkBrkIO 0 "FALSE" 1 "TRUE" ;
VAL_ 1357 SSVI_AppBrkPedIO 0 "FALSE" 1 "TRUE" ;
VAL_ 1357 SSVI_PrssStrtAgnIO 0 "FALSE" 1 "TRUE" ;
VAL_ 1357 SSVI_ShfToPrkIO 0 "FALSE" 1 "TRUE" ;
VAL_ 1357 SSVI_AppClchPedIO 0 "FALSE" 1 "TRUE" ;
VAL_ 1357 SSVI_NoRmtDtdPrssBrkToRestrtIO 0 "FALSE" 1 "TRUE" ;
VAL_ 1357 SSVI_PrssBtnAgnToTrnEngOffIO 0 "FALSE" 1 "TRUE" ;
VAL_ 1357 ShfToNeutRestrtVehIndOn 0 "FALSE" 1 "TRUE" ;
VAL_ 1357 RestrtVehIndOn 0 "FALSE" 1 "TRUE" ;
VAL_ 1357 SSVI_KeyMvmtRqrdIndOn 0 "FALSE" 1 "TRUE" ;
VAL_ 1357 SSVI_PrssClchBrkForStrtIO 0 "FALSE" 1 "TRUE" ;
VAL_ 1357 SSVI_ClsEngCmptToStrtVehIO 0 "FALSE" 1 "TRUE" ;
VAL_ 1357 SSVI_KylsStrtUseXmtrPcktIO 0 "FALSE" 1 "TRUE" ;
VAL_ 1357 SSVI_NoRmtDtdPrssClchToRestrtIO 0 "FALSE" 1 "TRUE" ;
VAL_ 1357 VehInNeutShfToDrvIndOn 0 "FALSE" 1 "TRUE" ;
VAL_ 644 SPMP_SysPwrModeAuth_Inv 0 "FALSE" 1 "TRUE" ;
VAL_ 644 SPMP_SysPwrModeAuth 0 "Off" 1 "Accessory" 2 "Run" 3 "Start Request" 4 "Propulsion" ;
VAL_ 644 SPMP_PriRunCrnkCmdActvAuth_Inv 0 "FALSE" 1 "TRUE" ;
VAL_ 644 SPMP_PriRunCrnkCmdActvAuth 0 "FALSE" 1 "TRUE" ;
VAL_ 1334 EmrgRespSysTyp 0 "Unknown" 1 "none" 2 "Onstar" 3 "eCall" 4 "ChevyStar" 5 "ERA" 6 "Generic" ;
VAL_ 1336 ASVSC_ReqEnbld 0 "FALSE" 1 "TRUE" ;
VAL_ 1336 TBTTrnChmEvntStat 0 "NO_ACTION" 1 "ACTIVE" 2 "CANCEL_CHIME" ;
VAL_ 1336 AudSeltdSrcReq 0 "No Action" 1 "AM" 2 "FM" 3 "XM" 4 "DAB" 5 "MediaPlayer" 6 "IPOD" 7 "Bluetooth" 8 "AUX" 9 "Audio Disk Player" 10 "LVM Stereo Audio" 11 "Internet App Audio" 12 "RSI_1" 13 "RSI_2" 14 "RadioSourceReserve14" 15 "RadioSourceReserve15" 16 "RadioSourceReserve16" 17 "RadioSourceReserve17" 18 "RadioSourceReserve18" 19 "RadioSourceReserve19" 20 "RadioSourceReserve20" 21 "RadioSourceReserve21" 22 "RadioSourceReserve22" 23 "RadioSourceReserve23" 24 "RadioSourceReserve24" 25 "RadioSourceReserve25" 26 "RadioSourceReserve26" 27 "RadioSourceReserve27" 28 "RadioSourceReserve29" 29 "RadioSourceReserve30" 30 "RadioSourceReserve31" ;
VAL_ 1339 SuprCruzSbscrptnActv 0 "FALSE" 1 "TRUE" ;
VAL_ 1339 InfoActivtnReq 0 "FALSE" 1 "TRUE" ;
VAL_ 1339 TnrFreqBndReq 0 "No Action" 1 "Off" 2 "AM" 3 "FM" 4 "DAB" 5 "XM" 6 "RadioBandReserve6" 7 "RadioBandReserve7" 8 "RadioBandReserve8" 9 "RadioBandReserve9" 10 "RadioBandReserve10" 11 "RadioBandReserve11" 12 "RadioBandReserve12" 13 "RadioBandReserve13" 14 "RadioBandReserve14" 15 "RadioBandReserve15" ;
VAL_ 1340 TAR_AudSrcStat 0 "NO_ACTION" 1 "AUDIO_READY" 2 "AUDIO_PLAYING" 3 "AUDIO_REQUEST" 4 "AUDIO_DISCONNECT RESERVED_1" 5 "RESERVED_2" 6 "RESERVED_3" 7 "RESERVED_4" 8 "RESERVED_5" 9 "RESERVED_6" 10 "RESERVED_7" 11 "RESERVED_8" 12 "RESERVED_9" 13 "RESERVED_10" 14 "RESERVED_11" ;
VAL_ 1340 TAR_AudConctReq 0 "NO ACTION" 1 "MIX_PROMPT" 2 "MUTEX_PROMPT" 3 "RING_TONE" 4 "PHONE" 5 "EMERGENCY_PHONE" 6 "RESERVED_1" 7 "RESERVED_2" 8 "RESERVED_3" 9 "RESERVED_4" 10 "RESERVED_5" 11 "RESERVED_6" 12 "RESERVED_7" 13 "RESERVED_8" 14 "RESERVED_9" 15 "RESERVED_10" ;
VAL_ 1340 RmtRflshUpdAvlbl 0 "FALSE" 1 "TRUE" ;
VAL_ 1402 TGPSDSP_DateSrcAuth_Inv 0 "FALSE" 1 "TRUE" ;
VAL_ 1402 TGPSDSP_DateSrcAuth 0 "Signal_Unavailable" 1 "GPP_Used_GNSS_RTC_Unavailable" 2 "Adjusted_RTC_Used_GPP_Unavailable" 3 "Adjusted_RTC_Used_GPP_Available" 4 "GNSS_GPP_Unavailable" 5 "GNSS_GPP_Time_synchronized" ;
VAL_ 1402 TGPSDSP_UTCMonthAuth_Inv 0 "FALSE" 1 "TRUE" ;
VAL_ 1402 TGPSDSP_UTCMonthAuth 0 "Unknown" 1 "January" 2 "February" 3 "March" 4 "April" 5 "May" 6 "June" 7 "July" 8 "August" 9 "September" 10 "October" 11 "November" 12 "December" ;
VAL_ 1402 TGPSDSP_UTCDyAuth_Inv 0 "FALSE" 1 "TRUE" ;
VAL_ 1402 TGPSDSP_UTCYrAuth_Inv 0 "FALSE" 1 "TRUE" ;
VAL_ 1403 TGPSTSP_TmSrcAuth_Inv 0 "FALSE" 1 "TRUE" ;
VAL_ 1403 TGPSTSP_TmSrcAuth 0 "Signal_Unavailable" 1 "GPP_Used_GNSS_RTC_Unavailable" 2 "Adjusted_RTC_Used_GPP_Unavailable" 3 "Adjusted_RTC_Used_GPP_Available" 4 "GNSS_GPP_Unavailable" 5 "GNSS_GPP_Time_synchronized" ;
VAL_ 1403 TGPSTSP_UTCHrsAuth_Inv 0 "FALSE" 1 "TRUE" ;
VAL_ 1403 TGPSTSP_UTCSecsAuth_Inv 0 "FALSE" 1 "TRUE" ;
VAL_ 1403 TGPSTSP_UTCMinsAuth_Inv 0 "FALSE" 1 "TRUE" ;
VAL_ 1101 TGI1P_NewFobXmtrLrndRstAuth 0 "FALSE" 1 "TRUE" ;
VAL_ 1101 TGI1P_EnhdServsLckReqAuth 0 "Lock All" 1 "Unlock All" 2 "No Action" ;
VAL_ 1101 TGI1P_TlmRmtIgnBlkImbCmdAuth 0 "FALSE" 1 "TRUE" ;
VAL_ 1101 TGI1P_EnhdServsRmtStrtReqAuth 0 "No Activation" 1 "Engine Requested Off" 2 "Engine Requested On" ;
VAL_ 1382 TSGI1P_EnhdServsSnrfRqAuth 0 "No Request" 1 "Fully Open" 2 "Open Vent" 3 "Fully Closed" ;
VAL_ 1382 TSGI1P_EnhdServsRrClsrLckRqAuth 0 "No Request" 1 "Unlock" 2 "Lock" ;
VAL_ 1382 TSGI1P_EnhdServsAllWndRqAuth 0 "No Request" 1 "Fully Open" 2 "Open Vent" 3 "Fully Closed" ;
VAL_ 1102 TVKRP_FobAvlReqAuth 0 "No Action" 1 "Disable" 2 "Enable" 3 "Return Results" ;
VAL_ 1102 TVKRP_VirtKeyRsrvtnRvkReqAuth 0 "No Action" 1 "Revoke Certificate" 2 "Revoke All Certificates" ;
VAL_ 1267 HtchVwAutoElecPrkBrkAppReqd 0 "FALSE" 1 "TRUE" ;
VAL_ 1252 TrlrVidVwPhs1ChmEvntStat 0 "No Action" 1 "Active" 2 "Cancel Chime" ;
VAL_ 1252 VidTrlrTowPhs2ChmEvntStat 0 "NO_ACTION" 1 "ACTIVE" 2 "CANCEL_CHIME" ;
VAL_ 1252 VidTrlrTowPhs1ChmEvntStat 0 "NO_ACTION" 1 "ACTIVE" 2 "CANCEL_CHIME" ;
VAL_ 1194 TrnsOilTmp_Inv 0 "FALSE" 1 "TRUE" ;
VAL_ 1229 TrnsThrmlMngmntSt 0 "Normal" 1 "Countermeasures Active" 2 "Driver Intervention Requested" ;
VAL_ 1046 TBIP_TrlrBrkgGainSetIndOnAuth 0 "FALSE" 1 "TRUE" ;
VAL_ 1046 TBIP_TrlrWrgFltIndOnAuth 0 "FALSE" 1 "TRUE" ;
VAL_ 1046 TBIP_ServTrlrBrkgSysIndOnAuth 0 "FALSE" 1 "TRUE" ;
VAL_ 1046 TBIP_TrlrBrkDsbldIndOnAuth 0 "FALSE" 1 "TRUE" ;
VAL_ 1046 TBIP_CkTrlrIndOnAuth 0 "FALSE" 1 "TRUE" ;
VAL_ 30 TGI2P_TrnsOutShftAngVelAuth_Inv 0 "FALSE" 1 "TRUE" ;
VAL_ 1035 VMMP_VehMtnMvmtStatAuth 0 "Parked" 1 "Neutral" 2 "Forward" 3 "Reverse" 4 "Invalid" ;
VAL_ 1036 VODVP_VehOdoDispValAuth_Inv 0 "FALSE" 1 "TRUE" ;
VAL_ 1079 VOSDVP_VehOdoStrdDspValAuth_Inv 0 "FALSE" 1 "TRUE" ;
VAL_ 553 VSADP_VehSpdAvgDrvnAuth_Inv 0 "FALSE" 1 "TRUE" ;
VAL_ 553 VSADP_FuelModeStsAuth 0 "Unknown" 1 "Gasoline Mode" 2 "Natural Gas Mode" 3 "Liquified Petroleum Gas Mode" 4 "Alternative Fuel Cut-off Active" ;
VAL_ 553 VSADP_RdcdPwrIndOnAuth 0 "FALSE" 1 "TRUE" ;
VAL_ 553 VSADP_VehSpdAvgDrvnSrcAuth 0 "Transmission Output Speed" 1 "Wheel Speed" ;
VAL_ 554 VSANDP_VehSpdAvgNDrvnAuth_Inv 0 "FALSE" 1 "TRUE" ;
VAL_ 1037 VKI2P_FobAvlStsAuth 0 "No Action" 1 "Disabled" 2 "Enabled" 3 "Fail" ;
VAL_ 1260 VKI3P_PncHrnReqAuth 0 "No Action" 1 "Active" 2 "Cancel Horn" ;
VAL_ 1260 VKI3P_MirUnfldReqdAuth 0 "FALSE" 1 "TRUE" ;
VAL_ 1260 VKI3P_MirFoldReqdAuth 0 "FALSE" 1 "TRUE" ;
VAL_ 1260 VKI3P_FobAvlReqAuth 0 "No Action" 1 "Enable" 2 "Disable" 3 "Return Status" ;
VAL_ 1260 VKI3P_ChrgOnReqdAuth 0 "FALSE" 1 "TRUE" ;
VAL_ 1260 VKI3P_ChrgOffReqdAuth 0 "FALSE" 1 "TRUE" ;
VAL_ 1260 VKI3P_RmtLctrHrnReqAuth 0 "No_Action" 1 "Active_Low" 2 "Active_Med" 3 "Active_High" 4 "Cancel_Horn" ;
VAL_ 1260 VKI3P_RmtFlOprtdHtrOnReqdAuth 0 "FALSE" 1 "TRUE" ;
VAL_ 1260 VKI3P_RmtFlOprtdHtrOffReqdAuth 0 "FALSE" 1 "TRUE" ;
VAL_ 1260 VKI3P_PwrToPCtlReqAuth 0 "No Action" 1 "Open" 2 "Close" 3 "Stop" 4 "Pause" ;
VAL_ 1260 VKI3P_PncLgtReqAuth 0 "No Action" 1 "Active" 2 "Cancel Light" ;
VAL_ 1260 VKI3P_VehStrtReqdAuth 0 "FALSE" 1 "TRUE" ;
VAL_ 1260 VKI3P_VehStopReqdAuth 0 "FALSE" 1 "TRUE" ;
VAL_ 1260 VKI3P_RsrvtnRvkStsAuth 0 "No Action" 1 "Write Failure" 2 "Revoke Certificate Successful" 3 "Certificate Not Found" 4 "No Certificates Stored" ;
VAL_ 1260 VKI3P_RmtLctrLgtReqAuth 0 "No_Action" 1 "Active" ;
VAL_ 1260 VKI3P_WndOpnReqdAuth 0 "FALSE" 1 "TRUE" ;
VAL_ 1260 VKI3P_WndClsReqdAuth 0 "FALSE" 1 "TRUE" ;
VAL_ 1288 VKIP_ExtLtStsAuth 0 "Idle" 1 "Auth in Process" 2 "Auth in Process - Single Authenticated" 3 "Auth Complete - Not Authenticated" 4 "Auth Complete - Authenticated" 5 "Auth Complete - Undetermined" ;
VAL_ 1288 VKIP_ExtFrtStsAuth 0 "Idle" 1 "Auth in Process" 2 "Auth in Process - Single Authenticated" 3 "Auth Complete - Not Authenticated" 4 "Auth Complete - Authenticated" 5 "Auth Complete - Undetermined" ;
VAL_ 1288 VKIP_DrvrDrUnlckReqdAuth 0 "FALSE" 1 "TRUE" ;
VAL_ 1288 VKIP_DrLckReqdAuth 0 "FALSE" 1 "TRUE" ;
VAL_ 1288 VKIP_AllDrUnlckReqdAuth 0 "FALSE" 1 "TRUE" ;
VAL_ 1288 VKIP_FrtCmptRelReqdAuth 0 "FALSE" 1 "TRUE" ;
VAL_ 1288 VKIP_ExtRtStsAuth 0 "Idle" 1 "Auth in Process" 2 "Auth in Process - Single Authenticated" 3 "Auth Complete - Not Authenticated" 4 "Auth Complete - Authenticated" 5 "Auth Complete - Undetermined" ;
VAL_ 1288 VKIP_ExtRrStsAuth 0 "Idle" 1 "Auth in Process" 2 "Auth in Process - Single Authenticated" 3 "Auth Complete - Not Authenticated" 4 "Auth Complete - Authenticated" 5 "Auth Complete - Undetermined" ;
VAL_ 1288 VKIP_PwrRrClsrCtlReqAuth 0 "No Action" 1 "Stop" 2 "Start" ;
VAL_ 1288 VKIP_FrtRtEntZnDevPrsntAuth 0 "FALSE" 1 "TRUE" ;
VAL_ 1288 VKIP_RrLtEntZnDevPrsntAuth 0 "FALSE" 1 "TRUE" ;
VAL_ 1288 VKIP_FrtLtEntZnDevPrsntAuth 0 "FALSE" 1 "TRUE" ;
VAL_ 1288 VKIP_WlcmZnDevPrsntAuth 0 "FALSE" 1 "TRUE" ;
VAL_ 1288 VKIP_RrRtEntZnDevPrsntAuth 0 "FALSE" 1 "TRUE" ;
VAL_ 1288 VKIP_RrExtZnDevPrsntAuth 0 "FALSE" 1 "TRUE" ;
VAL_ 1288 VKIP_RrClsrRelReqdAuth 0 "FALSE" 1 "TRUE" ;
VAL_ 1288 VKIP_RrClsrOnAprchReqdAuth 0 "FALSE" 1 "TRUE" ;
VAL_ 1343 PhnLtInVehCstAvlFlg7 0 "FALSE" 1 "TRUE" ;
VAL_ 1343 PhnLtInVehCstAvlFlg6 0 "FALSE" 1 "TRUE" ;
VAL_ 1343 PhnLtInVehCstAvlFlg5 0 "FALSE" 1 "TRUE" ;
VAL_ 1343 PhnLtInVehCstAvlFlg4 0 "FALSE" 1 "TRUE" ;
VAL_ 1343 PhnLtInVehCstAvlFlg3 0 "FALSE" 1 "TRUE" ;
VAL_ 1343 PhnLtInVehCstAvlFlg2 0 "FALSE" 1 "TRUE" ;
VAL_ 1343 PhnLtInVehCstAvlFlg1 0 "FALSE" 1 "TRUE" ;
VAL_ 1344 PhnLtInVehIndOn 0 "FALSE" 1 "TRUE" ;
VAL_ 1344 WrlsChrgSysChrgStat 0 "WCS Not Present" 1 "Charging Inactive" 2 "Charging Active" 3 "Charging Complete" 4 "Foreign Object Detected" 5 "WCS Overtemp Shutdown" 6 "Reserved 1" 7 "Reserved 2" ;
VAL_ 1345 PhnLtInVehCstSetAval 0 "FALSE" 1 "TRUE" ;
VAL_ 1345 PhnLtInVehCstCurrSetVal 0 "Setting_Unknown" 1 "Off" 2 "On" 3 "Reserved_3" 4 "Reserved_4" 5 "Reserved_5" 6 "Reserved_6" 7 "Reserved_7" ;
